VERSION ""

NS_ :

BS_:

BU_: SMART_CORE
VAL_TABLE_ FIRST_TOUCH_COORDINATE_Y_IS 0 "Default Value" ;
VAL_TABLE_ FIRST_TOUCH_COORDINATE_X_IS 0 "Default Value" ;

BO_ 3221225472 VECTOR__INDEPENDENT_SIG_MSG: 0 Vector__XXX
 SG_ VCU_DRIVE_MODE : 0|3@1+ (1,0) [0|7] "" Vector__XXX
 SG_ VCU36_MSG_CNT : 0|4@1+ (1,0) [0|15] "" Vector__XXX
 SG_ REMAINING_OIL_LIFE_PERCENT : 0|7@1+ (1,0) [0|100] "%" Vector__XXX
 SG_ BATT_OCV : 0|9@1+ (20,6000) [6000|16000] "mV" Vector__XXX

BO_ 1506 EMS49_500: 8 Vector__XXX
 SG_ IBS_Q_DISCHARGE : 32|16@1+ (0.125,0) [0|8191.75] "Ah"  SMART_CORE
 SG_ IBS_Q_CHARGE : 16|16@1+ (0.125,0) [0|8191.75] "Ah"  SMART_CORE
 SG_ IBS_INT_RESISTANCE_ERR : 12|4@1+ (1,2) [0|15] "%"  SMART_CORE
 SG_ IBS_INT_RESISTANCE : 0|12@1+ (0.0625,0) [0|255.875] "mOhm"  SMART_CORE

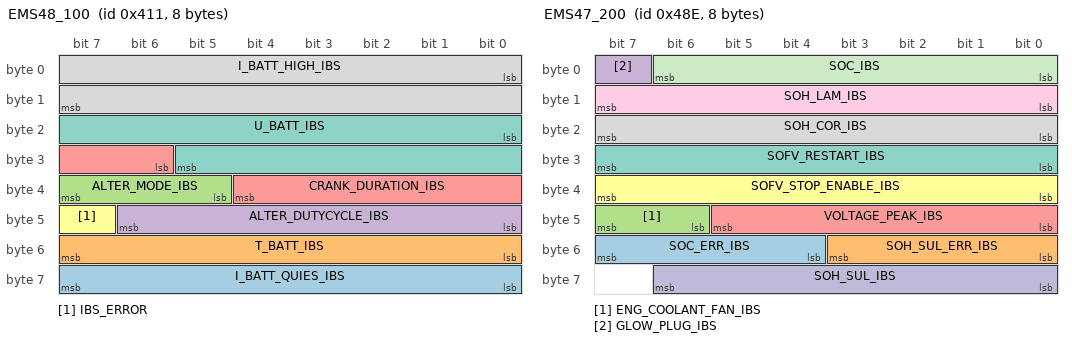
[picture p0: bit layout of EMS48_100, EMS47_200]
BO_ 1041 EMS48_100: 8 Vector__XXX
 SG_ I_BATT_QUIES_IBS : 56|8@1+ (0.00390625,0) [0|0.984375] "A"  SMART_CORE
 SG_ T_BATT_IBS : 48|8@1+ (1,-40) [-40|214] "degC"  SMART_CORE
 SG_ ALTER_MODE_IBS : 37|3@1+ (1,0) [0|7] ""  SMART_CORE
 SG_ ALTER_DUTYCYCLE_IBS : 40|7@1+ (1,0) [0|100] "%"  SMART_CORE
 SG_ CRANK_DURATION_IBS : 30|7@1+ (0.1,0) [0|9] "sec"  SMART_CORE
 SG_ IBS_ERROR : 47|1@1+ (1,0) [0|1] ""  SMART_CORE
 SG_ U_BATT_IBS : 16|14@1+ (0.001,3) [3|19.382] "V"  SMART_CORE
 SG_ I_BATT_HIGH_IBS : 0|16@1+ (0.03125,-1536) [-1536|511.90625] "A"  SMART_CORE

BO_ 1166 EMS47_200: 8 Vector__XXX
 SG_ SOC_ERR_IBS : 52|4@1+ (1,2) [0|15] "%"  SMART_CORE
 SG_ SOH_SUL_ERR_IBS : 48|4@1+ (1,2) [0|15] "%"  SMART_CORE
 SG_ ENG_COOLANT_FAN_IBS : 46|2@1+ (1,0) [0|3] ""  SMART_CORE
 SG_ GLOW_PLUG_IBS : 7|1@1+ (1,0) [0|1] ""  SMART_CORE
 SG_ VOLTAGE_PEAK_IBS : 40|6@1+ (0.125,5) [5|12.75] "V"  SMART_CORE
 SG_ SOFV_STOP_ENABLE_IBS : 32|8@1+ (0.0625,0) [0|15.875] "V"  SMART_CORE
 SG_ SOFV_RESTART_IBS : 24|8@1+ (0.0625,0) [0|15.875] "V"  SMART_CORE
 SG_ SOH_COR_IBS : 16|8@1+ (1,0) [0|100] "%"  SMART_CORE
 SG_ SOH_LAM_IBS : 8|8@1+ (1,0) [0|100] "%"  SMART_CORE
 SG_ SOH_SUL_IBS : 56|7@1+ (1,0) [0|100] "%"  SMART_CORE
 SG_ SOC_IBS : 0|7@1+ (1,0) [0|100] "%"  SMART_CORE

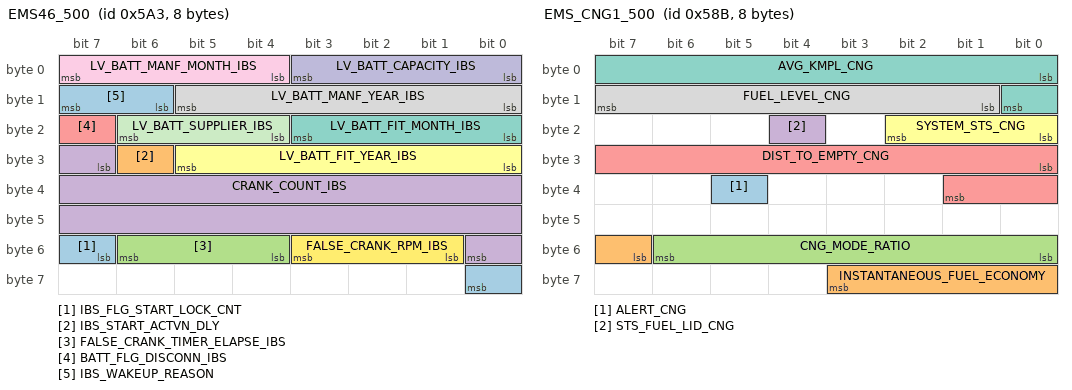
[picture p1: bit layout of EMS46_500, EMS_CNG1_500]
BO_ 1443 EMS46_500: 8 Vector__XXX
 SG_ IBS_FLG_START_LOCK_CNT : 55|2@1+ (1,0) [0|3] ""  SMART_CORE
 SG_ IBS_START_ACTVN_DLY : 30|1@1+ (1,0) [0|1] ""  SMART_CORE
 SG_ FALSE_CRANK_TIMER_ELAPSE_IBS : 52|3@1+ (1,0) [0|7] ""  SMART_CORE
 SG_ CRANK_COUNT_IBS : 31|18@1+ (1,0) [0|262143] ""  SMART_CORE
 SG_ BATT_FLG_DISCONN_IBS : 23|1@1+ (1,0) [0|1] ""  SMART_CORE
 SG_ LV_BATT_FIT_YEAR_IBS : 24|6@1+ (1,2026) [2026|2089] ""  SMART_CORE
 SG_ LV_BATT_FIT_MONTH_IBS : 16|4@1+ (1,0) [0|12] ""  SMART_CORE
 SG_ LV_BATT_MANF_YEAR_IBS : 8|6@1+ (1,2026) [2026|2089] ""  SMART_CORE
 SG_ LV_BATT_MANF_MONTH_IBS : 4|4@1+ (1,0) [0|12] ""  SMART_CORE
 SG_ LV_BATT_CAPACITY_IBS : 0|4@1+ (1,0) [0|15] "Ah"  SMART_CORE
 SG_ LV_BATT_SUPPLIER_IBS : 20|3@1+ (1,0) [0|7] ""  SMART_CORE
 SG_ FALSE_CRANK_RPM_IBS : 49|3@1+ (1,0) [0|7] ""  SMART_CORE
 SG_ IBS_WAKEUP_REASON : 14|2@1+ (1,0) [0|3] ""  SMART_CORE

BO_ 1419 EMS_CNG1_500: 8 Vector__XXX
 SG_ ALERT_CNG : 37|1@1+ (1,0) [0|1] ""  SMART_CORE
 SG_ INSTANTANEOUS_FUEL_ECONOMY : 55|5@1+ (1,0) [0|30] "km/kg"  SMART_CORE
 SG_ CNG_MODE_RATIO : 48|7@1+ (1,0) [0|100] "%"  SMART_CORE
 SG_ STS_FUEL_LID_CNG : 20|1@1+ (1,0) [0|1] ""  SMART_CORE
 SG_ DIST_TO_EMPTY_CNG : 24|10@1+ (1,0) [0|1000] "Km"  SMART_CORE
 SG_ SYSTEM_STS_CNG : 16|3@1+ (1,0) [0|7] ""  SMART_CORE
 SG_ AVG_KMPL_CNG : 0|9@1+ (0.1,0) [0|51] "km/kg"  SMART_CORE
 SG_ FUEL_LEVEL_CNG : 9|7@1+ (1,0) [0|100] "%"  SMART_CORE

BO_ 535 RVC1_100: 8 Vector__XXX
 SG_ RVC_GUIDED_VOICE_REQ : 8|4@1+ (1,0) [0|15] ""  SMART_CORE
 SG_ RVC_OPERATION_STATE : 4|3@1+ (1,0) [0|5] ""  SMART_CORE
 SG_ RVC_BUTTON_GROUP : 0|4@1+ (1,0) [0|9] ""  SMART_CORE

BO_ 833 MCM3_100: 8 SMART_CORE
 SG_ F_TRIG_F_STATE : 2|2@1+ (1,0) [0|3] "" Vector__XXX

BO_ 257 MCM_SP: 8 SMART_CORE
 SG_ IMMOVAL4 : 0|64@1+ (1,0) [0|1.8446744074] "" Vector__XXX

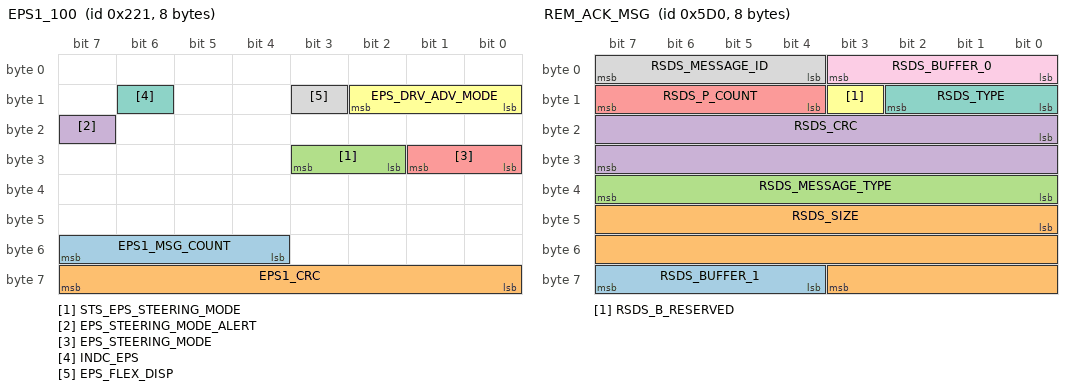
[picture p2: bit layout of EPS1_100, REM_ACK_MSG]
BO_ 545 EPS1_100: 8 Vector__XXX
 SG_ EPS1_MSG_COUNT : 52|4@1+ (1,0) [0|15] ""  SMART_CORE
 SG_ EPS1_CRC : 56|8@1+ (1,0) [0|255] ""  SMART_CORE
 SG_ STS_EPS_STEERING_MODE : 26|2@1+ (1,0) [0|3] ""  SMART_CORE
 SG_ EPS_STEERING_MODE_ALERT : 23|1@1+ (1,0) [0|1] ""  SMART_CORE
 SG_ EPS_STEERING_MODE : 24|2@1+ (1,0) [0|3] ""  SMART_CORE
 SG_ EPS_DRV_ADV_MODE : 8|3@1+ (1,0) [0|7] ""  SMART_CORE
 SG_ INDC_EPS : 14|1@1+ (1,0) [0|1] ""  SMART_CORE
 SG_ EPS_FLEX_DISP : 11|1@1+ (1,0) [0|1] ""  SMART_CORE

BO_ 987 OBC5_100: 8 Vector__XXX
 SG_ OBC_EVWARNING_TT : 4|2@1+ (1,0) [0|3] ""  SMART_CORE
 SG_ OBC_ALERT_MESGS : 8|6@1+ (1,0) [0|63] ""  SMART_CORE

BO_ 818 MCU6_100: 8 Vector__XXX
 SG_ MCU_EVWARNING_TT : 6|2@1+ (1,0) [0|3] ""  SMART_CORE
 SG_ MCU_ALERT_MSGS : 0|6@1+ (1,0) [0|63] ""  SMART_CORE

BO_ 992 LDC5_100: 8 Vector__XXX
 SG_ LDC_EVWARNING_TT : 6|2@1+ (1,0) [0|3] ""  SMART_CORE
 SG_ LDC_ALERT_MSGS : 0|6@1+ (1,0) [0|63] ""  SMART_CORE

BO_ 298 BMS21_100: 8 Vector__XXX
 SG_ BMS_BattEnergyDisAcc_Drv : 48|16@1+ (0.01,0) [0|50] "KWH"  SMART_CORE
 SG_ BMS_BattEnergyAcc_Regen : 32|16@1+ (0.01,0) [0|50] "KWH"  SMART_CORE
 SG_ BMS_BattEnergyAcc_NC : 16|16@1+ (0.01,0) [0|50] "KWH"  SMART_CORE
 SG_ BMS_BattEnergyAcc_FC : 0|16@1+ (0.01,0) [0|50] "KWH"  SMART_CORE

BO_ 1019 BMS15_200: 8 Vector__XXX
 SG_ BMS_ServiceDueDetection : 26|2@1+ (1,0) [0|3] ""  SMART_CORE
 SG_ BMS_BatteryContactorLife : 0|11@1+ (1,0) [0|2000] "kcycle"  SMART_CORE

BO_ 445 ESC16_10: 8 Vector__XXX
 SG_ STS_ITA : 0|2@1+ (1,0) [0|3] ""  SMART_CORE
 SG_ ITA_ACTIVE : 2|1@1+ (1,0) [0|1] ""  SMART_CORE
 SG_ CCO_WARNING : 11|3@1+ (1,0) [0|7] ""  SMART_CORE
 SG_ CCO_SET_SPD : 8|3@1+ (1,0) [0|7] ""  SMART_CORE
 SG_ CCO_ACTIVE : 5|2@1+ (1,0) [0|3] ""  SMART_CORE

BO_ 1488 REM_ACK_MSG: 8 SMART_CORE
 SG_ RSDS_BUFFER_1 : 60|4@1+ (1,0) [0|15] "" Vector__XXX
 SG_ RSDS_SIZE : 40|20@1+ (1,0) [0|1048575] "Byte" Vector__XXX
 SG_ RSDS_MESSAGE_TYPE : 32|8@1+ (1,0) [0|255] "NA" Vector__XXX
 SG_ RSDS_CRC : 16|16@1+ (1,0) [0|65535] "NA" Vector__XXX
 SG_ RSDS_P_COUNT : 12|4@1+ (1,0) [0|15] "counter" Vector__XXX
 SG_ RSDS_B_RESERVED : 11|1@1+ (1,0) [0|1] "NA" Vector__XXX
 SG_ RSDS_TYPE : 8|3@1+ (1,0) [0|7] "ENUM" Vector__XXX
 SG_ RSDS_MESSAGE_ID : 4|4@1+ (1,0) [0|15] "" Vector__XXX
 SG_ RSDS_BUFFER_0 : 0|4@1+ (1,0) [0|15] "" Vector__XXX

BO_ 1486 IS_REM_05: 8 SMART_CORE
 SG_ GPS_LONGITUDE : 32|31@1+ (1E-007,0) [0|180] "deg" Vector__XXX
 SG_ GPS_LATITUDE : 0|31@1+ (1E-007,0) [0|90] "deg" Vector__XXX
 SG_ GPS_HDOP_V : 31|1@1+ (1,0) [0|1] "bool" Vector__XXX

BO_ 1485 IS_REM_04: 8 SMART_CORE
 SG_ GPS_MCU_TIMESTAMP : 0|64@1+ (1,0) [0|1.84467440737096E+019] "us" Vector__XXX

BO_ 1484 IS_REM_03: 8 SMART_CORE
 SG_ GPS_EPOCH_TIMESTAMP : 0|64@1+ (1,0) [0|1.84467440737096E+019] "ms" Vector__XXX

BO_ 1827 EX_SUMMARY_RESPONSE_0: 8 SMART_CORE
 SG_ SUMMARY_DATA_0_MSG_CNT : 56|8@1+ (1,0) [0|255] "" Vector__XXX
 SG_ SUMMARY_DATA_0 : 0|56@1+ (1,0) [0|7.20575940379279E+016] "" Vector__XXX

BO_ 1828 EX_SUMMARY_RESPONSE_1: 8 SMART_CORE
 SG_ SUMMARY_DATA_1_MSG_CNT : 56|8@1+ (1,0) [0|255] "" Vector__XXX
 SG_ SUMMARY_DATA_1 : 0|56@1+ (1,0) [0|7.20575940379279E+016] "" Vector__XXX

BO_ 1830 EX_SUMMARY_RESPONSE_2: 8 SMART_CORE
 SG_ SUMMARY_DATA_2_MSG_CNT : 56|8@1+ (1,0) [0|255] "" Vector__XXX
 SG_ SUMMARY_DATA_2 : 0|56@1+ (1,0) [0|7.20575940379279E+016] "" Vector__XXX

BO_ 1831 EX_SUMMARY_RESPONSE_3: 8 SMART_CORE
 SG_ SUMMARY_DATA_3_MSG_CNT : 56|8@1+ (1,0) [0|255] "" Vector__XXX
 SG_ SUMMARY_DATA_3 : 0|56@1+ (1,0) [0|7.20575940379279E+016] "" Vector__XXX

BO_ 1487 IS_REM_06: 8 SMART_CORE
 SG_ GPS_HDOP : 0|10@1+ (0.1,0) [0|100] "NA" Vector__XXX
 SG_ GPS_ALTITUDE : 10|20@1+ (0.01,-500) [-500|6000] "m" Vector__XXX
 SG_ GPS_ALT_POSITION_STD : 30|14@1+ (0.01,0) [0|100] "m" Vector__XXX

BO_ 1483 IS_REM_02: 8 SMART_CORE
 SG_ GPS_ALT_POSITION_STD_V : 0|1@1+ (1,0) [0|1] "bool" Vector__XXX
 SG_ GPS_NUM_SATELLITES_V : 22|1@1+ (1,0) [0|1] "BOOL" Vector__XXX
 SG_ GPS_NUM_SATELLITES : 24|5@1+ (1,0) [0|31] "COUNTER" Vector__XXX
 SG_ GPS_MCU_TIMESTAMP_V : 21|1@1+ (1,0) [0|1] "bool" Vector__XXX
 SG_ GPS_LONGITUDE_V : 20|1@1+ (1,0) [0|1] "bool" Vector__XXX
 SG_ GPS_LONG_POSITION_STD_V : 18|1@1+ (1,0) [0|1] "bool" Vector__XXX
 SG_ GPS_LONG_POSITION_STD : 46|14@1+ (0.01,0) [0|100] "m" Vector__XXX
 SG_ GPS_LONG_DIRECTION_V : 19|1@1+ (1,0) [0|1] "bool" Vector__XXX
 SG_ GPS_LONG_DIRECTION : 23|1@1+ (1,0) [0|1] "bool" Vector__XXX
 SG_ GPS_LATITUDE_V : 17|1@1+ (1,0) [0|1] "bool" Vector__XXX
 SG_ GPS_LAT_POSITION_STD_V : 29|1@1+ (1,0) [0|1] "bool" Vector__XXX
 SG_ GPS_LAT_POSITION_STD : 32|14@1+ (0.01,0) [0|100] "m" Vector__XXX
 SG_ GPS_LAT_DIRECTION_V : 30|1@1+ (1,0) [0|1] "bool" Vector__XXX
 SG_ GPS_LAT_DIRECTION : 31|1@1+ (1,0) [0|1] "bool" Vector__XXX
 SG_ GPS_EPOCH_TIMESTAMP_V : 4|1@1+ (1,0) [0|1] "bool" Vector__XXX
 SG_ GPS_COURSE_V : 2|1@1+ (1,0) [0|1] "bool" Vector__XXX
 SG_ GPS_COURSE : 5|12@1+ (0.1,0) [0|360] "deg" Vector__XXX
 SG_ GPS_ALTITUDE_V : 1|1@1+ (1,0) [0|1] "bool" Vector__XXX

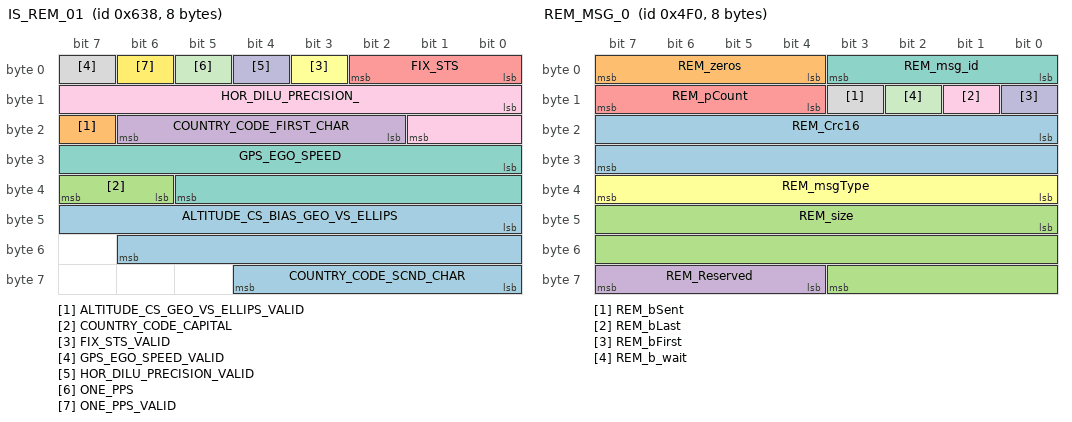
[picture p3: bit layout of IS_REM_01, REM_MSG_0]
BO_ 1592 IS_REM_01: 8 SMART_CORE
 SG_ ALTITUDE_CS_BIAS_GEO_VS_ELLIPS : 40|15@1+ (0.01,-150) [-150|150] "m" Vector__XXX
 SG_ ALTITUDE_CS_GEO_VS_ELLIPS_VALID : 23|1@1+ (1,0) [0|1] "bool" Vector__XXX
 SG_ COUNTRY_CODE_CAPITAL : 38|2@1+ (1,0) [0|2] "ENUM" Vector__XXX
 SG_ COUNTRY_CODE_FIRST_CHAR : 18|5@1+ (1,0) [0|26] "" Vector__XXX
 SG_ FIX_STS : 0|3@1+ (1,0) [0|6] "ENUM" Vector__XXX
 SG_ FIX_STS_VALID : 3|1@1+ (1,0) [0|1] "bool" Vector__XXX
 SG_ GPS_EGO_SPEED : 24|14@1+ (0.01,0) [0|100] "m_per_s" Vector__XXX
 SG_ GPS_EGO_SPEED_VALID : 7|1@1+ (1,0) [0|1] "bool" Vector__XXX
 SG_ HOR_DILU_PRECISION_ : 8|10@1+ (0.1,0) [0|100] "NA" Vector__XXX
 SG_ HOR_DILU_PRECISION_VALID : 4|1@1+ (1,0) [0|1] "bool" Vector__XXX
 SG_ ONE_PPS : 5|1@1+ (1,0) [0|1] "bool" Vector__XXX
 SG_ ONE_PPS_VALID : 6|1@1+ (1,0) [0|1] "bool" Vector__XXX
 SG_ COUNTRY_CODE_SCND_CHAR : 56|5@1+ (1,0) [0|26] "" Vector__XXX

BO_ 1279 REM_MSG_15: 8 Vector__XXX
 SG_ REM_DATA_15_MSG_CNT : 56|8@1+ (1,0) [0|255] ""  SMART_CORE
 SG_ REM_DATA_15 : 0|56@1+ (1,0) [0|7.20575940379279E+016] ""  SMART_CORE

BO_ 1278 REM_MSG_14: 8 Vector__XXX
 SG_ REM_DATA_14_MSG_CNT : 56|8@1+ (1,0) [0|255] ""  SMART_CORE
 SG_ REM_DATA_14 : 0|56@1+ (1,0) [0|7.20575940379279E+016] ""  SMART_CORE

BO_ 1277 REM_MSG_13: 8 Vector__XXX
 SG_ REM_DATA_13_MSG_CNT : 56|8@1+ (1,0) [0|255] ""  SMART_CORE
 SG_ REM_DATA_13 : 0|56@1+ (1,0) [0|7.20575940379279E+016] ""  SMART_CORE

BO_ 1276 REM_MSG_12: 8 Vector__XXX
 SG_ REM_DATA_12_MSG_CNT : 56|8@1+ (1,0) [0|255] ""  SMART_CORE
 SG_ REM_DATA_12 : 0|56@1+ (1,0) [0|7.20575940379279E+016] ""  SMART_CORE

BO_ 1275 REM_MSG_11: 8 Vector__XXX
 SG_ REM_DATA_11_MSG_CNT : 56|8@1+ (1,0) [0|255] ""  SMART_CORE
 SG_ REM_DATA_11 : 0|56@1+ (1,0) [0|7.20575940379279E+016] ""  SMART_CORE

BO_ 1274 REM_MSG_10: 8 Vector__XXX
 SG_ REM_DATA_10_MSG_CNT : 56|8@1+ (1,0) [0|255] ""  SMART_CORE
 SG_ REM_DATA_10 : 0|56@1+ (1,0) [0|7.20575940379279E+016] ""  SMART_CORE

BO_ 1273 REM_MSG_9: 8 Vector__XXX
 SG_ REM_DATA_9_MSG_CNT : 56|8@1+ (1,0) [0|255] ""  SMART_CORE
 SG_ REM_DATA_9 : 0|56@1+ (1,0) [0|7.20575940379279E+016] ""  SMART_CORE

BO_ 1272 REM_MSG_8: 8 Vector__XXX
 SG_ REM_DATA_8_MSG_CNT : 56|8@1+ (1,0) [0|255] ""  SMART_CORE
 SG_ REM_DATA_8 : 0|56@1+ (1,0) [0|7.20575940379279E+016] ""  SMART_CORE

BO_ 1271 REM_MSG_7: 8 Vector__XXX
 SG_ REM_DATA_7_MSG_CNT : 56|8@1+ (1,0) [0|255] ""  SMART_CORE
 SG_ REM_DATA_7 : 0|56@1+ (1,0) [0|7.20575940379279E+016] ""  SMART_CORE

BO_ 1270 REM_MSG_6: 8 Vector__XXX
 SG_ REM_DATA_6_MSG_CNT : 56|8@1+ (1,0) [0|255] ""  SMART_CORE
 SG_ REM_DATA_6 : 0|56@1+ (1,0) [0|7.20575940379279E+016] ""  SMART_CORE

BO_ 1269 REM_MSG_5: 8 Vector__XXX
 SG_ REM_DATA_5_MSG_CNT : 56|8@1+ (1,0) [0|255] ""  SMART_CORE
 SG_ REM_DATA_5 : 0|56@1+ (1,0) [0|7.20575940379279E+016] ""  SMART_CORE

BO_ 1268 REM_MSG_4: 8 Vector__XXX
 SG_ REM_DATA_4_MSG_CNT : 56|8@1+ (1,0) [0|255] ""  SMART_CORE
 SG_ REM_DATA_4 : 0|56@1+ (1,0) [0|7.20575940379279E+016] ""  SMART_CORE

BO_ 1267 REM_MSG_3: 8 Vector__XXX
 SG_ REM_DATA_3_MSG_CNT : 56|8@1+ (1,0) [0|255] ""  SMART_CORE
 SG_ REM_DATA_3 : 0|56@1+ (1,0) [0|7.20575940379279E+016] ""  SMART_CORE

BO_ 1266 REM_MSG_2: 8 Vector__XXX
 SG_ REM_DATA_2_MSG_CNT : 56|8@1+ (1,0) [0|255] ""  SMART_CORE
 SG_ REM_DATA_2 : 0|56@1+ (1,0) [0|7.20575940379279E+016] ""  SMART_CORE

BO_ 1265 REM_MSG_1: 8 Vector__XXX
 SG_ REM_DATA_1_MSG_CNT : 56|8@1+ (1,0) [0|255] ""  SMART_CORE
 SG_ REM_DATA_1 : 0|56@1+ (1,0) [0|7.20575940379279E+016] ""  SMART_CORE

BO_ 1264 REM_MSG_0: 8 Vector__XXX
 SG_ REM_Crc16 : 16|16@1+ (1,0) [0|65535] ""  SMART_CORE
 SG_ REM_zeros : 4|4@1+ (1,0) [0|15] ""  SMART_CORE
 SG_ REM_size : 40|20@1+ (1,0) [0|1048575] ""  SMART_CORE
 SG_ REM_Reserved : 60|4@1+ (1,0) [0|15] ""  SMART_CORE
 SG_ REM_pCount : 12|4@1+ (1,0) [0|15] ""  SMART_CORE
 SG_ REM_msgType : 32|8@1+ (1,0) [0|255] ""  SMART_CORE
 SG_ REM_msg_id : 0|4@1+ (1,0) [0|15] ""  SMART_CORE
 SG_ REM_bSent : 11|1@1+ (1,0) [0|1] ""  SMART_CORE
 SG_ REM_bLast : 9|1@1+ (1,0) [0|1] ""  SMART_CORE
 SG_ REM_bFirst : 8|1@1+ (1,0) [0|1] ""  SMART_CORE
 SG_ REM_b_wait : 10|1@1+ (1,0) [0|1] ""  SMART_CORE

BO_ 1007 VCU15_100: 8 Vector__XXX
 SG_ VCU_TorqueCoasting : 32|16@1+ (0.0625,-2048) [-2045|2045] "Nm"  SMART_CORE
 SG_ VCU_SwitchS2 : 50|1@1+ (1,0) [0|1] ""  SMART_CORE
 SG_ VCU_StCreep : 49|1@1+ (1,0) [0|1] ""  SMART_CORE
 SG_ VCU_StCoasting : 48|1@1+ (1,0) [0|1] ""  SMART_CORE
 SG_ VCU_HVAccPowerConsumption : 16|16@1+ (0.001,0) [0|65] "Kw"  SMART_CORE
 SG_ VCU_EConsPerKm : 0|16@1+ (0.001,0) [0|65.535] "Kwh/km"  SMART_CORE

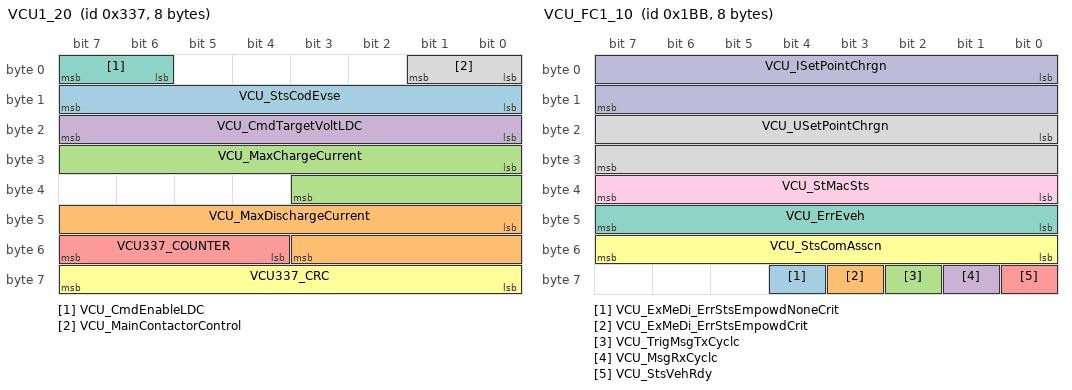
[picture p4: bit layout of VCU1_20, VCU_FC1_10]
BO_ 823 VCU1_20: 8 Vector__XXX
 SG_ VCU_StsCodEvse : 8|8@1+ (1,0) [0|255] ""  SMART_CORE
 SG_ VCU_MaxDischargeCurrent : 40|12@1+ (1,0) [0|4094] "A"  SMART_CORE
 SG_ VCU_MaxChargeCurrent : 24|12@1+ (1,0) [0|4094] "A"  SMART_CORE
 SG_ VCU_CmdTargetVoltLDC : 16|8@1+ (0.1,0) [0|25.5] "V"  SMART_CORE
 SG_ VCU337_COUNTER : 52|4@1+ (1,0) [0|15] "NA"  SMART_CORE
 SG_ VCU337_CRC : 56|8@1+ (1,0) [0|255] "NA"  SMART_CORE
 SG_ VCU_CmdEnableLDC : 6|2@1+ (1,0) [0|3] "NA"  SMART_CORE
 SG_ VCU_MainContactorControl : 0|2@1+ (1,0) [0|3] ""  SMART_CORE

BO_ 443 VCU_FC1_10: 8 Vector__XXX
 SG_ VCU_ExMeDi_ErrStsEmpowdNoneCrit : 60|1@1+ (1,0) [0|1] ""  SMART_CORE
 SG_ VCU_ExMeDi_ErrStsEmpowdCrit : 59|1@1+ (1,0) [0|1] ""  SMART_CORE
 SG_ VCU_TrigMsgTxCyclc : 58|1@1+ (1,0) [0|1] ""  SMART_CORE
 SG_ VCU_MsgRxCyclc : 57|1@1+ (1,0) [0|1] ""  SMART_CORE
 SG_ VCU_StsVehRdy : 56|1@1+ (1,0) [0|1] ""  SMART_CORE
 SG_ VCU_StsComAsscn : 48|8@1+ (1,0) [0|255] ""  SMART_CORE
 SG_ VCU_ErrEveh : 40|8@1+ (1,0) [0|255] ""  SMART_CORE
 SG_ VCU_USetPointChrgn : 16|16@1+ (0.1,0) [0|1500] "V"  SMART_CORE
 SG_ VCU_StMacSts : 32|8@1+ (1,0) [0|255] ""  SMART_CORE
 SG_ VCU_ISetPointChrgn : 0|16@1+ (0.1,0) [0|1000] "A"  SMART_CORE

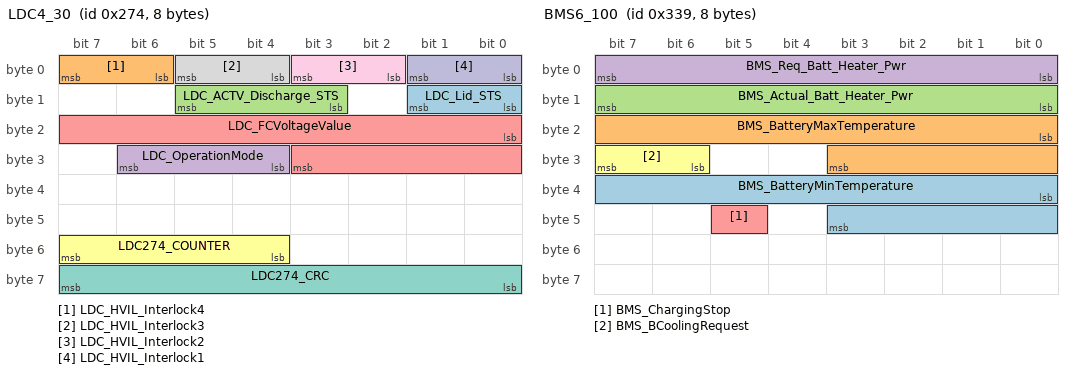
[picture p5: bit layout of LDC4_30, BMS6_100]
BO_ 628 LDC4_30: 8 Vector__XXX
 SG_ LDC_Lid_STS : 8|2@1+ (1,0) [0|3] ""  SMART_CORE
 SG_ LDC_HVIL_Interlock4 : 6|2@1+ (1,0) [0|3] "NA"  SMART_CORE
 SG_ LDC_ACTV_Discharge_STS : 11|3@1+ (1,0) [0|3] ""  SMART_CORE
 SG_ LDC_OperationMode : 28|3@1+ (1,0) [0|7] "NA"  SMART_CORE
 SG_ LDC_FCVoltageValue : 16|12@1+ (0.1,0) [0|500] "V"  SMART_CORE
 SG_ LDC274_COUNTER : 52|4@1+ (1,0) [0|14] "NA"  SMART_CORE
 SG_ LDC274_CRC : 56|8@1+ (1,0) [0|0] "NA"  SMART_CORE
 SG_ LDC_HVIL_Interlock3 : 4|2@1+ (1,0) [0|3] "NA"  SMART_CORE
 SG_ LDC_HVIL_Interlock2 : 2|2@1+ (1,0) [0|3] "NA"  SMART_CORE
 SG_ LDC_HVIL_Interlock1 : 0|2@1+ (1,0) [0|3] "NA"  SMART_CORE

BO_ 991 LDC3_100: 8 Vector__XXX
 SG_ LDC_OPV_Circuit_Error : 22|1@1+ (1,0) [0|1] ""  SMART_CORE
 SG_ LDC_Low_Temp_Shutdown : 23|1@1+ (1,0) [0|1] ""  SMART_CORE
 SG_ LDC_IPV_Circuit_Error : 21|1@1+ (1,0) [0|1] ""  SMART_CORE
 SG_ LDC_INTERNAL_FAIL : 20|1@1+ (1,0) [0|1] ""  SMART_CORE
 SG_ LDC_Input_Over_Current : 19|1@1+ (1,0) [0|1] ""  SMART_CORE
 SG_ LDC_Heat_Sink_Over_Temp_Shutdown : 2|1@1+ (1,0) [0|1] ""  SMART_CORE
 SG_ LDC_HVDC_Side_Relay_Sts : 52|1@1+ (1,0) [0|1] ""  SMART_CORE
 SG_ LDC_CC_CV_STS : 51|1@1+ (1,0) [0|1] ""  SMART_CORE
 SG_ LDC_Burst_Mode_Sts : 50|1@1+ (1,0) [0|1] ""  SMART_CORE
 SG_ LDC_HW_Enable : 49|1@1+ (1,0) [0|1] ""  SMART_CORE
 SG_ LDC_Stage : 46|3@1+ (1,0) [0|7] ""  SMART_CORE
 SG_ LDC_Debounce_Count : 41|3@1+ (1,0) [0|7] ""  SMART_CORE
 SG_ LDC_Vprog_Out_of_Range : 40|1@1+ (1,0) [0|1] ""  SMART_CORE
 SG_ LDC_Watchdog_Failure : 18|1@1+ (1,0) [0|1] ""  SMART_CORE
 SG_ LDC_VCU_Node_Absent : 17|1@1+ (1,0) [0|1] ""  SMART_CORE
 SG_ LDC_Temp_Sensing_Failure : 16|1@1+ (1,0) [0|1] ""  SMART_CORE
 SG_ LDC_IPC_COMM_ERR_OBC : 15|1@1+ (1,0) [0|1] ""  SMART_CORE
 SG_ LDC_EEPROM_Failure : 14|1@1+ (1,0) [0|1] ""  SMART_CORE
 SG_ LDC_Short_Circuit : 13|1@1+ (1,0) [0|1] ""  SMART_CORE
 SG_ LDC_Output_Under_Voltage : 12|1@1+ (1,0) [0|1] ""  SMART_CORE
 SG_ LDC_Output_Over_Voltage : 11|1@1+ (1,0) [0|1] ""  SMART_CORE
 SG_ LDC_Output_Over_Current : 10|1@1+ (1,0) [0|1] ""  SMART_CORE
 SG_ LDC_LPS_Under_Voltage : 9|1@1+ (1,0) [0|1] ""  SMART_CORE
 SG_ LDC_LPS_Over_Voltage : 8|1@1+ (1,0) [0|1] ""  SMART_CORE
 SG_ LDC_Input_Under_Voltage : 7|1@1+ (1,0) [0|1] ""  SMART_CORE
 SG_ LDC_Input_Over_Voltage : 6|1@1+ (1,0) [0|1] ""  SMART_CORE
 SG_ LDC_Heat_Sink_Over_Temp_Wng_2 : 5|1@1+ (1,0) [0|1] ""  SMART_CORE
 SG_ LDC_Heat_Sink_Over_Temp_Wng_1 : 4|1@1+ (1,0) [0|1] ""  SMART_CORE
 SG_ LDC_Heat_Sink_Over_Temp_Wng_0 : 3|1@1+ (1,0) [0|1] ""  SMART_CORE
 SG_ LDC_Amb_Over_Temp_Wng : 1|1@1+ (1,0) [0|1] ""  SMART_CORE
 SG_ LDC_Amb_Over_Temp_Shutdown : 0|1@1+ (1,0) [0|1] ""  SMART_CORE

BO_ 580 LDC2_30: 8 Vector__XXX
 SG_ LDC_OutputVoltageValue : 40|12@1+ (0.01,0) [0|25] "V"  SMART_CORE
 SG_ LDC_OutputCurrent : 16|14@1+ (0.1,0) [0|1000] "A"  SMART_CORE
 SG_ LDC_InputVoltageValue : 0|14@1+ (0.1,0) [0|1000] "V"  SMART_CORE
 SG_ LDC_InputCurrentValue : 32|8@1+ (0.1,0) [0|25] "A"  SMART_CORE

BO_ 989 LDC1_100: 8 Vector__XXX
 SG_ LDC_Primary_Temperature : 32|12@1+ (0.1,-55) [-55|150] "deg C"  SMART_CORE
 SG_ LDC_CoolingRequest : 0|8@1+ (0.5,0) [0|100] "%"  SMART_CORE
 SG_ LDC_MOSFET_Temperature : 48|12@1+ (0.1,-55) [-55|150] "deg C"  SMART_CORE
 SG_ LDC_Secondary_Temperature : 8|12@1+ (0.1,-55) [-55|150] "deg C"  SMART_CORE
 SG_ LDC_ProtectionMode : 28|3@1+ (1,0) [0|7] "NA"  SMART_CORE

BO_ 825 BMS6_100: 8 Vector__XXX
 SG_ BMS_BatteryMinTemperature : 32|12@1+ (0.1,-40) [-40|125] "deg C"  SMART_CORE
 SG_ BMS_BatteryMaxTemperature : 16|12@1+ (0.1,-40) [-40|125] "deg C"  SMART_CORE
 SG_ BMS_Actual_Batt_Heater_Pwr : 8|8@1+ (50,0) [0|8000] "Watts"  SMART_CORE
 SG_ BMS_Req_Batt_Heater_Pwr : 0|8@1+ (50,0) [0|8000] "watts"  SMART_CORE
 SG_ BMS_ChargingStop : 45|1@1+ (1,0) [0|1] ""  SMART_CORE
 SG_ BMS_BCoolingRequest : 30|2@1+ (1,0) [0|3] ""  SMART_CORE

BO_ 352 BMS_IVT_MSG_RESULT_U3: 6 Vector__XXX
 SG_ BMS_IVT_Result_U3 : 0|32@1+ (1,0) [0|45000] "mV"  SMART_CORE

BO_ 345 BMS_IVT_MSG_RESULT_U2: 6 Vector__XXX
 SG_ BMS_IVT_Result_U2 : 0|32@1+ (1,0) [0|45000] "mV"  SMART_CORE

BO_ 344 BMS_IVT_MSG_RESULT_U1: 6 Vector__XXX
 SG_ BMS_IVT_Result_U1 : 0|32@1+ (1,0) [0|45000] "mV"  SMART_CORE

BO_ 979 BMS9_10: 8 Vector__XXX
 SG_ BMS_Discharge_Cycle : 48|16@1+ (1,0) [0|65534] ""  SMART_CORE
 SG_ BMS_Charge_Cycle : 32|16@1+ (1,0) [0|65534] ""  SMART_CORE
 SG_ BMS_ChargePowerAvailable_2 : 16|16@1+ (0.01,0) [0|200] "Kw"  SMART_CORE
 SG_ BMS_ChargePowerAvailable_10 : 0|16@1+ (0.01,0) [0|200] "Kw"  SMART_CORE

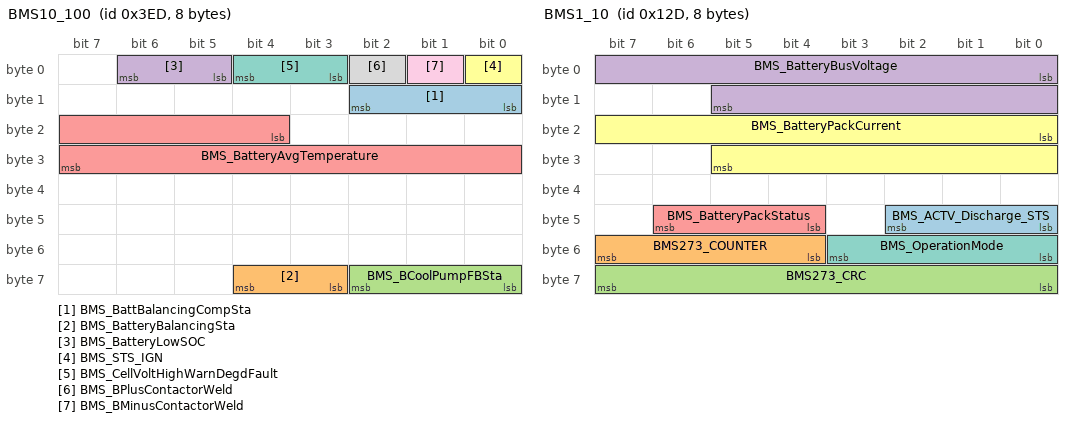
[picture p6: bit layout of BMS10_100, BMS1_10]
BO_ 1005 BMS10_100: 8 Vector__XXX
 SG_ BMS_BattBalancingCompSta : 8|3@1+ (1,0) [0|4] ""  SMART_CORE
 SG_ BMS_BatteryBalancingSta : 59|2@1+ (1,0) [0|1] ""  SMART_CORE
 SG_ BMS_BCoolPumpFBSta : 56|3@1+ (1,0) [0|7] ""  SMART_CORE
 SG_ BMS_BatteryLowSOC : 5|2@1+ (1,0) [0|3] ""  SMART_CORE
 SG_ BMS_BatteryAvgTemperature : 20|12@1+ (0.1,-40) [-40|125] "deg C"  SMART_CORE
 SG_ BMS_STS_IGN : 0|1@1+ (1,0) [0|1] ""  SMART_CORE
 SG_ BMS_CellVoltHighWarnDegdFault : 3|2@1+ (1,0) [0|3] ""  SMART_CORE
 SG_ BMS_BPlusContactorWeld : 2|1@1+ (1,0) [0|1] ""  SMART_CORE
 SG_ BMS_BMinusContactorWeld : 1|1@1+ (1,0) [0|1] ""  SMART_CORE

BO_ 301 BMS1_10: 8 Vector__XXX
 SG_ BMS_ACTV_Discharge_STS : 40|3@1+ (1,0) [0|4] ""  SMART_CORE
 SG_ BMS273_COUNTER : 52|4@1+ (1,0) [0|14] "NA"  SMART_CORE
 SG_ BMS273_CRC : 56|8@1+ (1,0) [0|0] "NA"  SMART_CORE
 SG_ BMS_BatteryBusVoltage : 0|14@1+ (0.1,0) [0|460] "V"  SMART_CORE
 SG_ BMS_BatteryPackStatus : 44|3@1+ (1,0) [0|7] ""  SMART_CORE
 SG_ BMS_BatteryPackCurrent : 16|14@1+ (0.1,-600) [-600|600] "A"  SMART_CORE
 SG_ BMS_OperationMode : 48|4@1+ (1,0) [0|15] ""  SMART_CORE

BO_ 1003 BMS19_100: 8 Vector__XXX
 SG_ BMS_CellTemp9 m2 : 48|16@1+ (0.1,-50) [-40|125] "degC"  SMART_CORE
 SG_ BMS_CellTemp8 m2 : 32|16@1+ (0.1,-50) [-40|125] "degC"  SMART_CORE
 SG_ BMS_CellTemp7 m2 : 16|16@1+ (0.1,-50) [-40|125] "degC"  SMART_CORE
 SG_ BMS_CellTemp6 m1 : 48|16@1+ (0.1,-50) [-40|125] "degC"  SMART_CORE
 SG_ BMS_CellTemp5 m1 : 32|16@1+ (0.1,-50) [-40|125] "degC"  SMART_CORE
 SG_ BMS_CellTemp4 m1 : 16|16@1+ (0.1,-50) [-40|125] "degC"  SMART_CORE
 SG_ BMS_CellTemp32 m10 : 32|16@1+ (0.1,-50) [-40|125] "degC"  SMART_CORE
 SG_ BMS_CellTemp31 m10 : 16|16@1+ (0.1,-50) [-40|125] "degC"  SMART_CORE
 SG_ BMS_CellTemp30 m9 : 48|16@1+ (0.1,-50) [-40|125] "degC"  SMART_CORE
 SG_ BMS_CellTemp29 m9 : 32|16@1+ (0.1,-50) [-40|125] "degC"  SMART_CORE
 SG_ BMS_CellTemp28 m9 : 16|16@1+ (0.1,-50) [-40|125] "degC"  SMART_CORE
 SG_ BMS_CellTemp27 m8 : 48|16@1+ (0.1,-50) [-40|125] "degC"  SMART_CORE
 SG_ BMS_CellTemp26 m8 : 32|16@1+ (0.1,-50) [-40|125] "degC"  SMART_CORE
 SG_ BMS_CellTemp25 m8 : 16|16@1+ (0.1,-50) [-40|125] "degC"  SMART_CORE
 SG_ BMS_CellTemp24 m7 : 48|16@1+ (0.1,-50) [-40|125] "degC"  SMART_CORE
 SG_ BMS_CellTemp23 m7 : 32|16@1+ (0.1,-50) [-40|125] "degC"  SMART_CORE
 SG_ BMS_CellTemp22 m7 : 16|16@1+ (0.1,-50) [-40|125] "degC"  SMART_CORE
 SG_ BMS_CellTemp21 m6 : 48|16@1+ (0.1,-50) [-40|125] "degC"  SMART_CORE
 SG_ BMS_CellTemp20 m6 : 32|16@1+ (0.1,-50) [-40|125] "degC"  SMART_CORE
 SG_ BMS_CellTemp19 m6 : 16|16@1+ (0.1,-50) [-40|125] "degC"  SMART_CORE
 SG_ BMS_CellTemp18 m5 : 48|16@1+ (0.1,-50) [-40|125] "degC"  SMART_CORE
 SG_ BMS_CellTemp17 m5 : 32|16@1+ (0.1,-50) [-40|125] "degC"  SMART_CORE
 SG_ BMS_CellTemp16 m5 : 16|16@1+ (0.1,-50) [-40|125] "degC"  SMART_CORE
 SG_ BMS_CellTemp15 m4 : 48|16@1+ (0.1,-50) [-40|125] "degC"  SMART_CORE
 SG_ BMS_CellTemp14 m4 : 32|16@1+ (0.1,-50) [-40|125] "degC"  SMART_CORE
 SG_ BMS_CellTemp13 m4 : 16|16@1+ (0.1,-50) [-40|125] "degC"  SMART_CORE
 SG_ BMS_CellTemp12 m3 : 48|16@1+ (0.1,-50) [-40|125] "degC"  SMART_CORE
 SG_ BMS_CellTemp11 m3 : 32|16@1+ (0.1,-50) [-40|125] "degC"  SMART_CORE
 SG_ BMS_CellTemp10 m3 : 16|16@1+ (0.1,-50) [-40|125] "degC"  SMART_CORE
 SG_ BMS_CellTemp3 m0 : 48|16@1+ (0.1,-50) [-40|125] "degC"  SMART_CORE
 SG_ BMS_CellTemp2 m0 : 32|16@1+ (0.1,-50) [-40|125] "degC"  SMART_CORE
 SG_ BMS_CellTemp1 m0 : 16|16@1+ (0.1,-50) [-40|125] "degC"  SMART_CORE
 SG_ BMS_CellTemp_Index M : 0|8@1+ (1,0) [0|255] ""  SMART_CORE

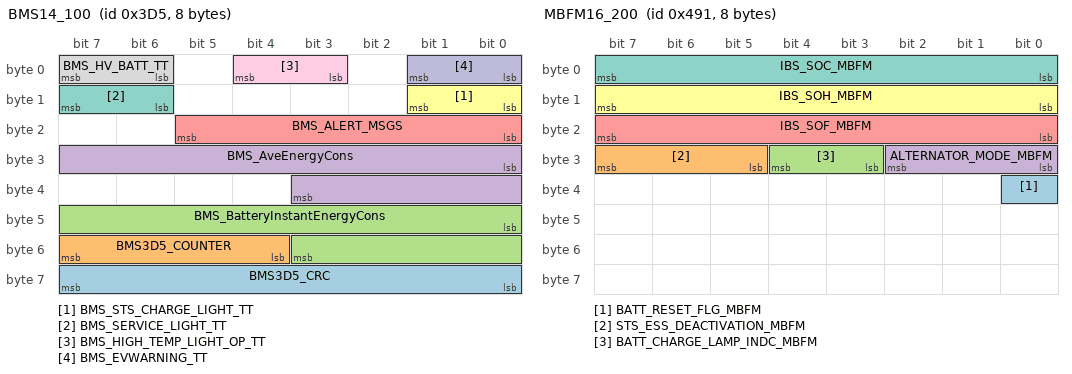
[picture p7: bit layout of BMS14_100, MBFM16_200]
BO_ 981 BMS14_100: 8 Vector__XXX
 SG_ BMS3D5_CRC : 56|8@1+ (1,0) [0|0] "NA"  SMART_CORE
 SG_ BMS3D5_COUNTER : 52|4@1+ (1,0) [0|14] "NA"  SMART_CORE
 SG_ BMS_BatteryInstantEnergyCons : 40|12@1+ (0.1,0) [0|45] "Kwh"  SMART_CORE
 SG_ BMS_AveEnergyCons : 24|12@1+ (0.1,0) [0|45] "Kwh"  SMART_CORE
 SG_ BMS_ALERT_MSGS : 16|6@1+ (1,0) [0|63] ""  SMART_CORE
 SG_ BMS_STS_CHARGE_LIGHT_TT : 8|2@1+ (1,0) [0|3] ""  SMART_CORE
 SG_ BMS_SERVICE_LIGHT_TT : 14|2@1+ (1,0) [0|3] ""  SMART_CORE
 SG_ BMS_HV_BATT_TT : 6|2@1+ (1,0) [0|3] ""  SMART_CORE
 SG_ BMS_HIGH_TEMP_LIGHT_OP_TT : 3|2@1+ (1,0) [0|3] ""  SMART_CORE
 SG_ BMS_EVWARNING_TT : 0|2@1+ (1,0) [0|3] ""  SMART_CORE

BO_ 1949 SBRM_DIAG_RES: 8 Vector__XXX
 SG_ DIAG_SBRM_RES_DATA : 0|64@1+ (1,0) [0|1.8446744074] ""  SMART_CORE

BO_ 1941 SBRM_DIAG_REQ: 8 SMART_CORE
 SG_ DIAG_SBRM_REQ_DATA : 0|64@1+ (1,0) [0|1.8446744074E+019] "" Vector__XXX

BO_ 779 FRM3_TEST_100: 8 Vector__XXX
 SG_ TIME_GAP_FRM : 40|8@1+ (0.1,0) [0|25.5] "sec"  SMART_CORE

BO_ 1852 FDHM_DIAG_RES: 8 Vector__XXX
 SG_ DIAG_FDHM_RES_DATA : 0|64@1+ (1,0) [0|1.8446744074E+019] ""  SMART_CORE

BO_ 1866 APA_DIAG_RES: 8 Vector__XXX
 SG_ DIAG_APA_RES_DATA : 0|64@1+ (1,0) [0|1.8446744074E+019] ""  SMART_CORE

BO_ 1585 ICC1_1000: 8 Vector__XXX
 SG_ TRANSFER_MODE_ICC : 4|2@1+ (1,0) [0|3] ""  SMART_CORE
 SG_ ICC_ALERT_MSG : 8|3@1+ (1,0) [0|7] ""  SMART_CORE

BO_ 1170 MBFM17_200: 8 Vector__XXX
 SG_ IBS_BATT_TEMP_MBFM : 32|16@1+ (0.5,-40) [-40|125] "DegC"  SMART_CORE
 SG_ IBS_BATT_VOLT_MBFM : 16|16@1+ (0.001,0) [4|24] "V"  SMART_CORE
 SG_ IBS_CURRENT_MBFM : 0|16@1+ (1,-1250) [-1250|1250] "Amps"  SMART_CORE

BO_ 1994 ICC_DIAG_RES: 8 Vector__XXX
 SG_ DIAG_ICC_RES_DATA : 0|64@1+ (1,0) [0|1.8446744074E+019] ""  SMART_CORE

BO_ 1169 MBFM16_200: 8 Vector__XXX
 SG_ BATT_RESET_FLG_MBFM : 32|1@1- (1,0) [0|1] ""  SMART_CORE
 SG_ STS_ESS_DEACTIVATION_MBFM : 29|3@1+ (1,0) [0|7] ""  SMART_CORE
 SG_ BATT_CHARGE_LAMP_INDC_MBFM : 27|2@1+ (1,0) [0|3] ""  SMART_CORE
 SG_ ALTERNATOR_MODE_MBFM : 24|3@1+ (1,0) [0|7] ""  SMART_CORE
 SG_ IBS_SOF_MBFM : 16|8@1+ (1,0) [0|100] "%"  SMART_CORE
 SG_ IBS_SOH_MBFM : 8|8@1+ (1,0) [0|100] "%"  SMART_CORE
 SG_ IBS_SOC_MBFM : 0|8@1+ (1,0) [0|100] "%"  SMART_CORE

BO_ 1988 HLCU1_DIAG_REQ: 8 SMART_CORE
 SG_ DIAG_HLCU_REQ_DATA : 0|64@1+ (1,0) [0|1.8446744074E+019] "" Vector__XXX

BO_ 2006 HLCU2_DIAG_REQ: 8 SMART_CORE
 SG_ DIAG_HLCU_REQ_DATA : 0|64@1+ (1,0) [0|1.8446744074E+019] "" Vector__XXX

BO_ 2019 TC_DIAG_REQ: 8 SMART_CORE
 SG_ DIAG_TC_REQ_DATA : 0|64@1+ (1,0) [0|1.8446744074E+019] "" Vector__XXX

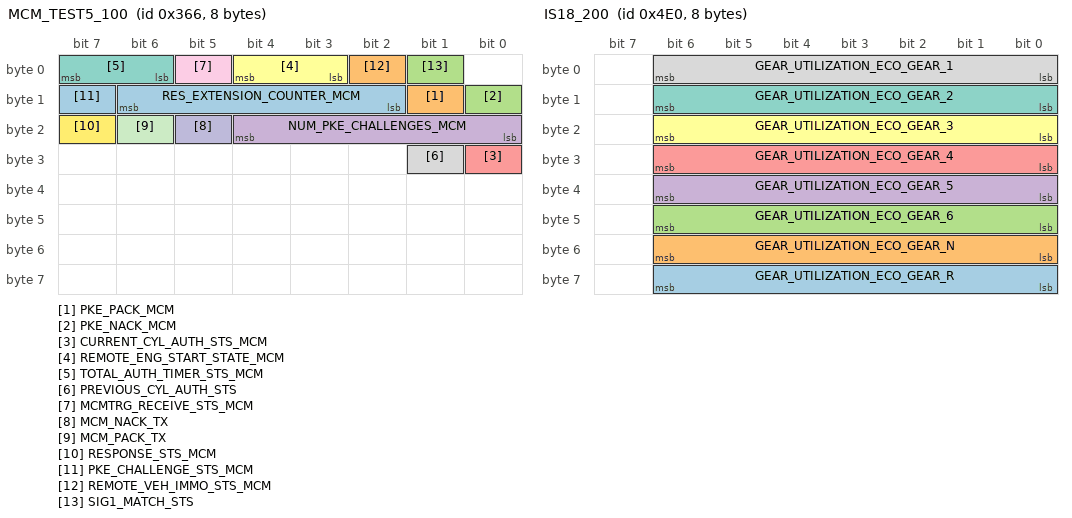
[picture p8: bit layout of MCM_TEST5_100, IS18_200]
BO_ 870 MCM_TEST5_100: 8 SMART_CORE
 SG_ RES_EXTENSION_COUNTER_MCM : 10|5@1+ (1,0) [0|31] "" Vector__XXX
 SG_ PKE_PACK_MCM : 9|1@1+ (1,0) [0|0] "" Vector__XXX
 SG_ PKE_NACK_MCM : 8|1@1+ (1,0) [0|0] "" Vector__XXX
 SG_ NUM_PKE_CHALLENGES_MCM : 16|5@1+ (1,0) [0|31] "" Vector__XXX
 SG_ CURRENT_CYL_AUTH_STS_MCM : 24|1@1+ (1,0) [0|1] "" Vector__XXX
 SG_ REMOTE_ENG_START_STATE_MCM : 3|2@1+ (1,0) [0|3] "" Vector__XXX
 SG_ TOTAL_AUTH_TIMER_STS_MCM : 6|2@1+ (1,0) [0|0] "" Vector__XXX
 SG_ PREVIOUS_CYL_AUTH_STS : 25|1@1+ (1,0) [0|1] "" Vector__XXX
 SG_ MCMTRG_RECEIVE_STS_MCM : 5|1@1+ (1,0) [0|1] "" Vector__XXX
 SG_ MCM_NACK_TX : 21|1@1+ (1,0) [0|1] "" Vector__XXX
 SG_ MCM_PACK_TX : 22|1@1+ (1,0) [0|1] "" Vector__XXX
 SG_ RESPONSE_STS_MCM : 23|1@1+ (1,0) [0|1] "" Vector__XXX
 SG_ PKE_CHALLENGE_STS_MCM : 15|1@1+ (1,0) [0|1] "" Vector__XXX
 SG_ REMOTE_VEH_IMMO_STS_MCM : 2|1@1+ (1,0) [0|1] "" Vector__XXX
 SG_ SIG1_MATCH_STS : 1|1@1+ (1,0) [0|1] "" Vector__XXX

BO_ 1654 MCM4_1000: 8 SMART_CORE
 SG_ UPDATE_REPROG_USER_AUTH : 2|2@1+ (1,0) [0|3] "" Vector__XXX
 SG_ UPDATE_DOWNLOAD_USER_AUTH : 0|2@1+ (1,0) [0|3] "" Vector__XXX
 SG_ MCM4_CRC : 56|8@1+ (1,0) [0|255] "" Vector__XXX
 SG_ MCM4_CNT : 52|4@1+ (1,0) [0|15] "" Vector__XXX

BO_ 1958 SCM_DIAG_REQ: 8 SMART_CORE
 SG_ DIAG_SCM_REQ_DATA : 0|64@1+ (1,0) [0|1.8446744074E+019] "" Vector__XXX

BO_ 1959 FVC_DIAG_REQ: 8 SMART_CORE
 SG_ DIAG_FVC_REQ_DATA : 0|64@1+ (1,0) [0|1.8446744074E+019] "" Vector__XXX

BO_ 1842 FRM_DIAG_REQ: 8 SMART_CORE
 SG_ DIAG_FRM_REQ_DATA : 0|64@1+ (1,0) [0|1.8446744074E+019] "" Vector__XXX

BO_ 1986 ICC_DIAG_REQ: 8 SMART_CORE
 SG_ DIAG_ICC_REQ_DATA : 0|64@1+ (1,0) [0|1.8446744074E+019] "" Vector__XXX

BO_ 1858 APA_DIAG_REQ: 8 SMART_CORE
 SG_ DIAG_APA_REQ_DATA : 0|64@1+ (1,0) [0|1.8446744074E+019] "" Vector__XXX

BO_ 1859 AMP_DIAG_REQ: 8 SMART_CORE
 SG_ DIAG_AMP_REQ_DATA : 0|64@1+ (1,0) [0|1.8446744074E+019] "" Vector__XXX

BO_ 1248 IS18_200: 8 SMART_CORE
 SG_ GEAR_UTILIZATION_ECO_GEAR_R : 56|7@1+ (1,0) [0|100] "perKM" Vector__XXX
 SG_ GEAR_UTILIZATION_ECO_GEAR_N : 48|7@1+ (1,0) [0|100] "perKM" Vector__XXX
 SG_ GEAR_UTILIZATION_ECO_GEAR_6 : 40|7@1+ (1,0) [0|100] "perKM" Vector__XXX
 SG_ GEAR_UTILIZATION_ECO_GEAR_5 : 32|7@1+ (1,0) [0|100] "perKM" Vector__XXX
 SG_ GEAR_UTILIZATION_ECO_GEAR_4 : 24|7@1+ (1,0) [0|100] "perKM" Vector__XXX
 SG_ GEAR_UTILIZATION_ECO_GEAR_3 : 16|7@1+ (1,0) [0|100] "perKM" Vector__XXX
 SG_ GEAR_UTILIZATION_ECO_GEAR_2 : 8|7@1+ (1,0) [0|100] "perKM" Vector__XXX
 SG_ GEAR_UTILIZATION_ECO_GEAR_1 : 0|7@1+ (1,0) [0|100] "perKM" Vector__XXX

BO_ 2017 TCU_DIAG_REQ: 8 SMART_CORE
 SG_ DIAG_TCU_REQ_DATA : 0|64@1+ (1,0) [0|1.8446744074E+019] "" Vector__XXX

BO_ 1955 WLC_DIAG_REQ: 8 SMART_CORE
 SG_ DIAG_WLC_REQ_DATA : 0|64@1+ (1,0) [0|1.84467440737096E+019] "" Vector__XXX

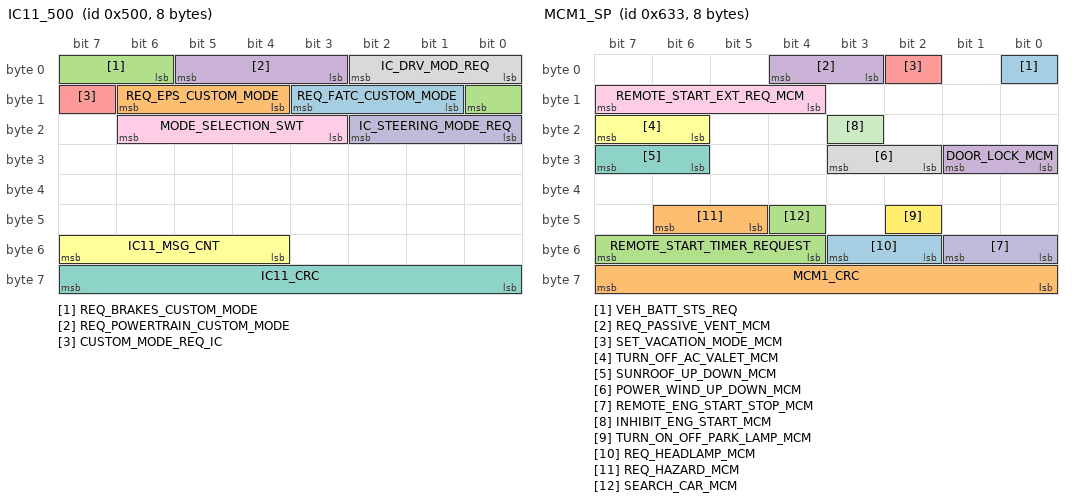
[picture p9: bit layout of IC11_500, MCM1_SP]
BO_ 1280 IC11_500: 8 SMART_CORE
 SG_ REQ_FATC_CUSTOM_MODE : 9|3@1+ (1,0) [0|0] "" Vector__XXX
 SG_ REQ_EPS_CUSTOM_MODE : 12|3@1+ (1,0) [0|7] "" Vector__XXX
 SG_ REQ_BRAKES_CUSTOM_MODE : 6|3@1+ (1,0) [0|7] "" Vector__XXX
 SG_ REQ_POWERTRAIN_CUSTOM_MODE : 3|3@1+ (1,0) [0|7] "" Vector__XXX
 SG_ CUSTOM_MODE_REQ_IC : 15|1@1+ (1,0) [0|1] "" Vector__XXX
 SG_ IC11_MSG_CNT : 52|4@1+ (1,0) [0|15] "" Vector__XXX
 SG_ IC11_CRC : 56|8@1+ (1,0) [0|255] "" Vector__XXX
 SG_ IC_DRV_MOD_REQ : 0|3@1+ (1,0) [0|7] "" Vector__XXX
 SG_ MODE_SELECTION_SWT : 19|4@1+ (1,0) [0|15] "" Vector__XXX
 SG_ IC_STEERING_MODE_REQ : 16|3@1+ (1,0) [0|7] "" Vector__XXX

BO_ 154 MCM_WAKEUP: 8 SMART_CORE
 SG_ MCM_WAKEUP_REASON : 0|16@1+ (1,0) [0|65535] "" Vector__XXX

BO_ 955 MCM_SLEEP: 8 SMART_CORE
 SG_ RESERVED_3 : 0|64@1+ (1,0) [0|1.8446744074E+019] "" Vector__XXX

BO_ 957 MCM_ACTIVE: 8 SMART_CORE
 SG_ RESERVED_3 : 0|64@1+ (1,0) [0|1.8446744074E+019] "" Vector__XXX

BO_ 1587 MCM1_SP: 8 SMART_CORE
 SG_ VEH_BATT_STS_REQ : 0|1@1+ (1,0) [0|1] "" Vector__XXX
 SG_ MCM1_CRC : 56|8@1+ (1,0) [0|0] "" Vector__XXX
 SG_ REMOTE_START_TIMER_REQUEST : 52|4@1+ (1,0) [0|15] "minutes" Vector__XXX
 SG_ REQ_PASSIVE_VENT_MCM : 3|2@1+ (1,0) [0|3] "" Vector__XXX
 SG_ SET_VACATION_MODE_MCM : 2|1@1+ (1,0) [0|1] "" Vector__XXX
 SG_ TURN_OFF_AC_VALET_MCM : 22|2@1+ (1,0) [0|3] "" Vector__XXX
 SG_ SUNROOF_UP_DOWN_MCM : 30|2@1+ (1,0) [0|3] "" Vector__XXX
 SG_ POWER_WIND_UP_DOWN_MCM : 26|2@1+ (1,0) [0|3] "" Vector__XXX
 SG_ REMOTE_START_EXT_REQ_MCM : 12|4@1+ (1,0) [0|15] "" Vector__XXX
 SG_ REMOTE_ENG_START_STOP_MCM : 48|2@1+ (1,0) [0|3] "" Vector__XXX
 SG_ INHIBIT_ENG_START_MCM : 19|1@1+ (1,0) [0|1] "" Vector__XXX
 SG_ TURN_ON_OFF_PARK_LAMP_MCM : 42|1@1+ (1,0) [0|1] "" Vector__XXX
 SG_ REQ_HEADLAMP_MCM : 50|2@1+ (1,0) [0|3] "" Vector__XXX
 SG_ REQ_HAZARD_MCM : 45|2@1+ (1,0) [0|3] "" Vector__XXX
 SG_ SEARCH_CAR_MCM : 44|1@1+ (1,0) [0|1] "" Vector__XXX
 SG_ DOOR_LOCK_MCM : 24|2@1+ (1,0) [0|3] "" Vector__XXX

BO_ 1856 FATC_DIAG_REQ: 8 SMART_CORE
 SG_ DIAG_FATC_REQ_DATA : 0|64@1+ (1,0) [0|1.8446744074E+019] "" Vector__XXX

BO_ 1144 SBRM1_100: 8 Vector__XXX
 SG_ PSGR_REAR_SEAT_BELT_SBRM : 2|6@1+ (1,0) [0|63] ""  SMART_CORE

BO_ 1963 WLC_DIAG_RES: 8 Vector__XXX
 SG_ DIAG_WLC_RES_DATA : 0|64@1+ (1,0) [0|1.84467440737096E+019] ""  SMART_CORE

BO_ 956 WLC_ACTIVE: 8 Vector__XXX
 SG_ RESERVED_2 : 0|64@1+ (1,0) [0|1.84467440737096E+019] ""  SMART_CORE

BO_ 786 EMS13_200: 8 Vector__XXX
 SG_ IBS_CURRENT : 0|16@1+ (1,-1250) [-1250|1250] "Amps"  SMART_CORE
 SG_ IBS_BATT_TEMP : 32|16@1+ (0.5,-40) [-40|125] "DegC"  SMART_CORE
 SG_ IBS_BATT_VOLT : 16|16@1+ (0.001,0) [4|24] "V"  SMART_CORE

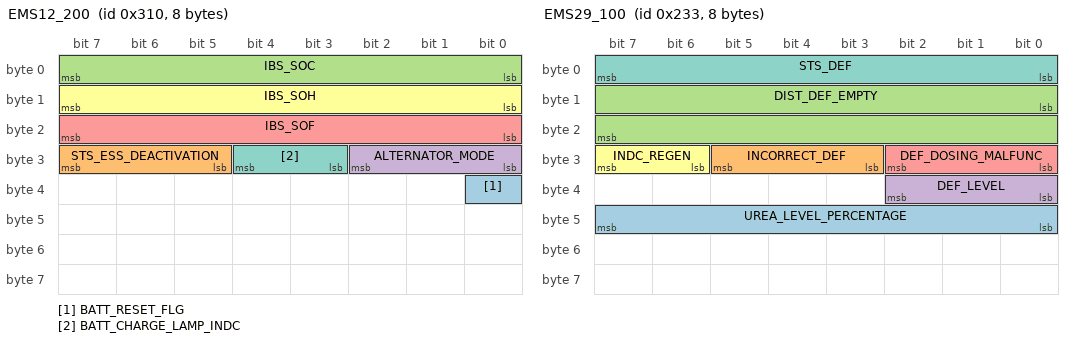
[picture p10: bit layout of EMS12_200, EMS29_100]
BO_ 784 EMS12_200: 8 Vector__XXX
 SG_ BATT_RESET_FLG : 32|1@1- (1,0) [0|1] ""  SMART_CORE
 SG_ STS_ESS_DEACTIVATION : 29|3@1+ (1,0) [0|7] ""  SMART_CORE
 SG_ IBS_SOC : 0|8@1+ (1,0) [0|100] "%"  SMART_CORE
 SG_ ALTERNATOR_MODE : 24|3@1+ (1,0) [0|7] ""  SMART_CORE
 SG_ IBS_SOF : 16|8@1+ (1,0) [0|100] "%"  SMART_CORE
 SG_ IBS_SOH : 8|8@1+ (1,0) [0|100] "%"  SMART_CORE
 SG_ BATT_CHARGE_LAMP_INDC : 27|2@1+ (1,0) [0|3] ""  SMART_CORE

BO_ 563 EMS29_100: 8 Vector__XXX
 SG_ UREA_LEVEL_PERCENTAGE : 40|8@1+ (1,0) [0|100] "%"  SMART_CORE
 SG_ INCORRECT_DEF : 27|3@1+ (1,0) [0|4] ""  SMART_CORE
 SG_ DIST_DEF_EMPTY : 8|16@1+ (1,0) [0|2400] "km"  SMART_CORE
 SG_ DEF_LEVEL : 32|3@1+ (1,0) [0|4] ""  SMART_CORE
 SG_ DEF_DOSING_MALFUNC : 24|3@1+ (1,0) [0|4] ""  SMART_CORE
 SG_ INDC_REGEN : 30|2@1+ (1,0) [0|3] ""  SMART_CORE
 SG_ STS_DEF : 0|8@1+ (1,0) [0|255] ""  SMART_CORE

BO_ 295 EMS21_10: 8 Vector__XXX
 SG_ ACC_PED_ACTUAL : 32|8@1+ (0.4,0) [0|100] "%"  SMART_CORE
 SG_ ENG_LOSSES : 40|11@1+ (1,-1024) [-1024|1021] "NM"  SMART_CORE
 SG_ EMS21_MSG_CNT : 52|4@1+ (1,0) [0|15] ""  SMART_CORE
 SG_ EMS21_CRC : 56|8@1+ (1,0) [0|255] ""  SMART_CORE
 SG_ BRK_PEDAL1 : 27|2@1+ (1,0) [0|3] ""  SMART_CORE

BO_ 375 AMT6_20: 8 Vector__XXX
 SG_ TGS_LEVER_AMT : 16|4@1+ (1,0) [0|15] ""  SMART_CORE
 SG_ AMT_BUZZER : 34|1@1+ (1,0) [0|1] ""  SMART_CORE
 SG_ AMT_MIL : 22|2@1+ (1,0) [0|3] ""  SMART_CORE
 SG_ ALERT_AMT : 29|3@1+ (1,0) [0|7] ""  SMART_CORE

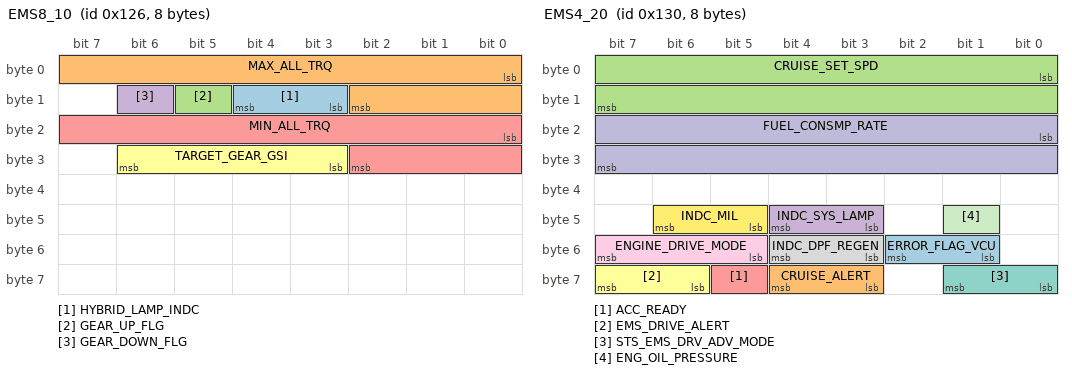
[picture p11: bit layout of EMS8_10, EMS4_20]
BO_ 294 EMS8_10: 8 Vector__XXX
 SG_ HYBRID_LAMP_INDC : 11|2@1+ (1,0) [0|2] ""  SMART_CORE
 SG_ MAX_ALL_TRQ : 0|11@1+ (1,-1024) [-1024|1022] "Nm"  SMART_CORE
 SG_ GEAR_UP_FLG : 13|1@1+ (1,0) [0|1] ""  SMART_CORE
 SG_ GEAR_DOWN_FLG : 14|1@1+ (1,0) [0|1] ""  SMART_CORE
 SG_ MIN_ALL_TRQ : 16|11@1+ (1,-1024) [-1024|1022] "Nm"  SMART_CORE
 SG_ TARGET_GEAR_GSI : 27|4@1+ (1,0) [0|15] ""  SMART_CORE

BO_ 304 EMS4_20: 8 Vector__XXX
 SG_ ERROR_FLAG_VCU : 49|2@1+ (1,0) [0|3] ""  SMART_CORE
 SG_ CRUISE_ALERT : 59|2@1+ (1,0) [0|3] ""  SMART_CORE
 SG_ CRUISE_SET_SPD : 0|16@1+ (0.015625,0) [0|300] "kmph"  SMART_CORE
 SG_ INDC_SYS_LAMP : 43|2@1+ (1,0) [0|3] ""  SMART_CORE
 SG_ ACC_READY : 61|1@1+ (1,0) [0|1] ""  SMART_CORE
 SG_ EMS_DRIVE_ALERT : 62|2@1+ (1,0) [0|3] ""  SMART_CORE
 SG_ STS_EMS_DRV_ADV_MODE : 56|2@1+ (1,0) [0|3] ""  SMART_CORE
 SG_ INDC_DPF_REGEN : 51|2@1+ (1,0) [0|3] ""  SMART_CORE
 SG_ ENGINE_DRIVE_MODE : 53|3@1+ (1,0) [0|7] ""  SMART_CORE
 SG_ FUEL_CONSMP_RATE : 16|16@1+ (1,0) [0|65534] "ul/20ms"  SMART_CORE
 SG_ ENG_OIL_PRESSURE : 41|1@1+ (1,0) [0|1] ""  SMART_CORE
 SG_ INDC_MIL : 45|2@1+ (1,0) [0|3] ""  SMART_CORE

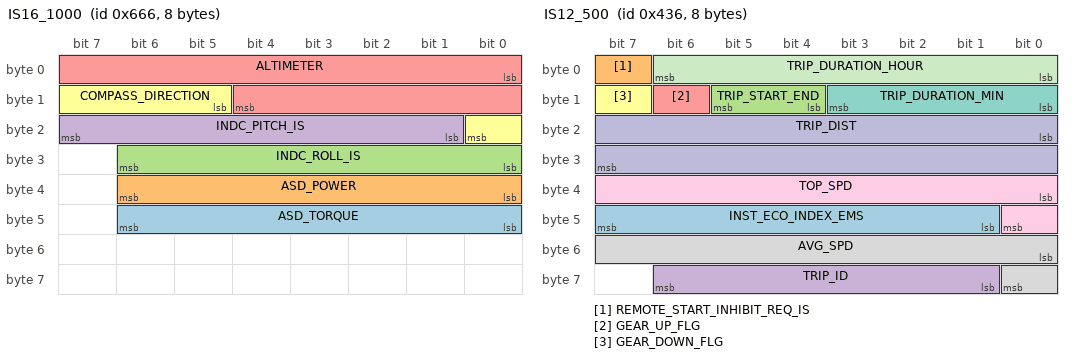
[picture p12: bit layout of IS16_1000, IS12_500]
BO_ 1638 IS16_1000: 8 SMART_CORE
 SG_ ASD_TORQUE : 40|7@1+ (1,0) [0|100] "%" Vector__XXX
 SG_ ASD_POWER : 32|7@1+ (1,0) [0|100] "%" Vector__XXX
 SG_ INDC_ROLL_IS : 24|7@1+ (1,-62) [-62|65] "Deg" Vector__XXX
 SG_ INDC_PITCH_IS : 17|7@1+ (1,-62) [-62|65] "Deg" Vector__XXX
 SG_ ALTIMETER : 0|13@1+ (1,0) [0|8192] "m" Vector__XXX
 SG_ COMPASS_DIRECTION : 13|4@1+ (1,0) [0|15] "" Vector__XXX

BO_ 1079 IS13_500: 8 SMART_CORE
 SG_ ESS_DURATION : 8|12@1+ (0.1,0) [0|409.5] "MIN" Vector__XXX
 SG_ IDLING_DURATION : 0|8@1+ (1,0) [0|254] "min" Vector__XXX

BO_ 1078 IS12_500: 8 SMART_CORE
 SG_ INST_ECO_INDEX_EMS : 41|7@1+ (1,0) [0|100] "" Vector__XXX
 SG_ REMOTE_START_INHIBIT_REQ_IS : 7|1@1+ (1,0) [0|1] "" Vector__XXX
 SG_ TRIP_START_END : 12|2@1+ (1,0) [0|3] "" Vector__XXX
 SG_ TRIP_ID : 57|6@1+ (1,0) [0|63] "" Vector__XXX
 SG_ GEAR_UP_FLG : 14|1@1+ (1,0) [0|1] "" Vector__XXX
 SG_ GEAR_DOWN_FLG : 15|1@1+ (1,0) [0|1] "" Vector__XXX
 SG_ TRIP_DURATION_MIN : 8|4@1+ (1,0) [0|14] "min" Vector__XXX
 SG_ AVG_SPD : 48|9@1+ (1,0) [0|300] "KMPH" Vector__XXX
 SG_ TOP_SPD : 32|9@1+ (1,0) [0|300] "kmph" Vector__XXX
 SG_ TRIP_DIST : 16|16@1+ (0.1,0) [0|6553.4] "km" Vector__XXX
 SG_ TRIP_DURATION_HOUR : 0|7@1+ (1,0) [0|126] "Hours" Vector__XXX

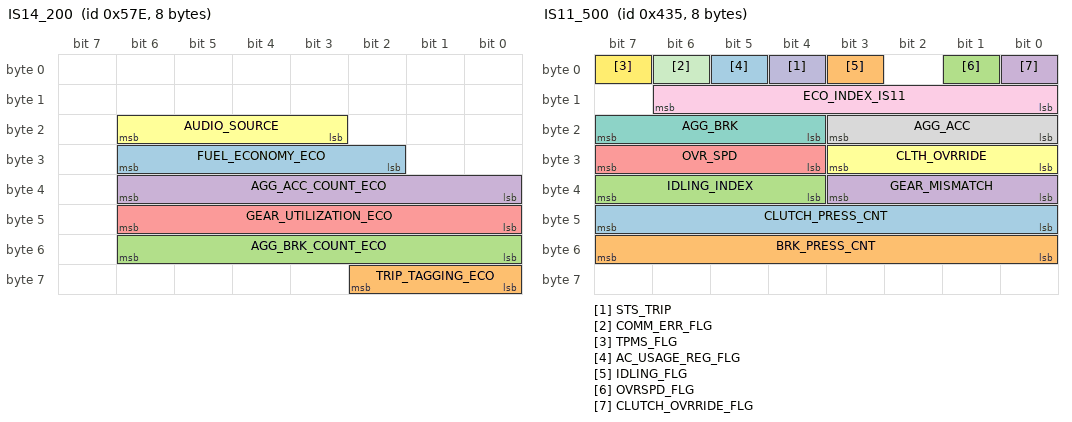
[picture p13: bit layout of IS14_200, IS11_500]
BO_ 1406 IS14_200: 8 SMART_CORE
 SG_ FUEL_ECONOMY_ECO : 26|5@1+ (1,0) [0|0] "" Vector__XXX
 SG_ TRIP_TAGGING_ECO : 56|3@1+ (1,0) [0|0] "" Vector__XXX
 SG_ AGG_BRK_COUNT_ECO : 48|7@1+ (1,0) [0|100] "perKM" Vector__XXX
 SG_ AGG_ACC_COUNT_ECO : 32|7@1+ (1,0) [0|100] "perKM" Vector__XXX
 SG_ GEAR_UTILIZATION_ECO : 40|7@1+ (1,0) [0|100] "perKM" Vector__XXX
 SG_ AUDIO_SOURCE : 19|4@1+ (1,0) [0|15] "" Vector__XXX

BO_ 1077 IS11_500: 8 SMART_CORE
 SG_ CLUTCH_PRESS_CNT : 40|8@1+ (1,0) [0|253] "" Vector__XXX
 SG_ BRK_PRESS_CNT : 48|8@1+ (1,0) [0|253] "" Vector__XXX
 SG_ IDLING_INDEX : 36|4@1+ (1,0) [0|15] "" Vector__XXX
 SG_ GEAR_MISMATCH : 32|4@1+ (1,0) [0|15] "" Vector__XXX
 SG_ OVR_SPD : 28|4@1+ (1,0) [0|15] "" Vector__XXX
 SG_ CLTH_OVRRIDE : 24|4@1+ (1,0) [0|15] "" Vector__XXX
 SG_ AGG_BRK : 20|4@1+ (1,0) [0|15] "" Vector__XXX
 SG_ AGG_ACC : 16|4@1+ (1,0) [0|15] "" Vector__XXX
 SG_ ECO_INDEX_IS11 : 8|7@1+ (1,0) [0|127] "" Vector__XXX
 SG_ STS_TRIP : 4|1@1+ (1,0) [0|1] "" Vector__XXX
 SG_ COMM_ERR_FLG : 6|1@1+ (1,0) [0|1] "" Vector__XXX
 SG_ TPMS_FLG : 7|1@1+ (1,0) [0|1] "" Vector__XXX
 SG_ AC_USAGE_REG_FLG : 5|1@1+ (1,0) [0|1] "" Vector__XXX
 SG_ IDLING_FLG : 3|1@1+ (1,0) [0|1] "" Vector__XXX
 SG_ OVRSPD_FLG : 1|1@1+ (1,0) [0|1] "" Vector__XXX
 SG_ CLUTCH_OVRRIDE_FLG : 0|1@1+ (1,0) [0|1] "" Vector__XXX

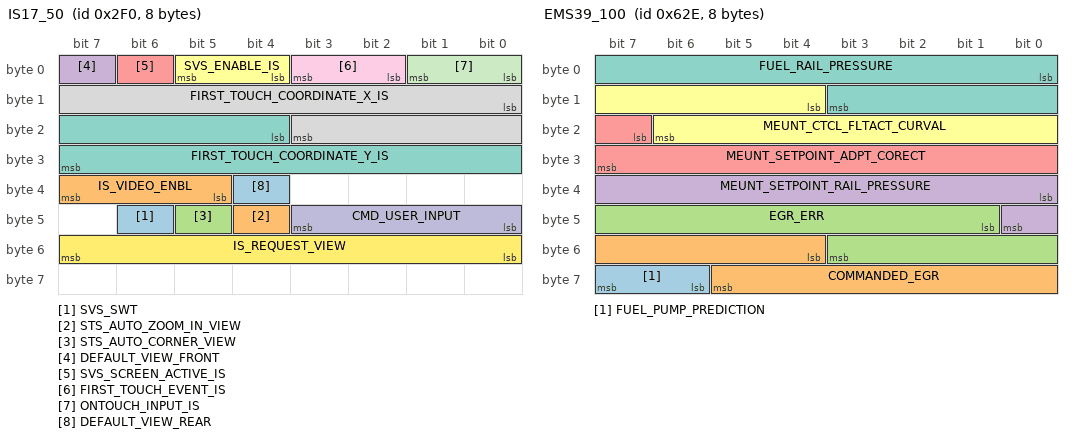
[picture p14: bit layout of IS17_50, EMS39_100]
BO_ 752 IS17_50: 8 SMART_CORE
 SG_ SVS_SWT : 46|1@1+ (1,0) [0|1] "" Vector__XXX
 SG_ STS_AUTO_ZOOM_IN_VIEW : 44|1@1+ (1,0) [0|1] "" Vector__XXX
 SG_ STS_AUTO_CORNER_VIEW : 45|1@1+ (1,0) [0|1] "" Vector__XXX
 SG_ DEFAULT_VIEW_FRONT : 7|1@1+ (1,0) [0|0] "" Vector__XXX
 SG_ SVS_SCREEN_ACTIVE_IS : 6|1@1+ (1,0) [0|1] "" Vector__XXX
 SG_ SVS_ENABLE_IS : 4|2@1+ (1,0) [0|0] "" Vector__XXX
 SG_ FIRST_TOUCH_COORDINATE_Y_IS : 20|12@1+ (0.025,0) [0|100] "%" Vector__XXX
 SG_ FIRST_TOUCH_COORDINATE_X_IS : 8|12@1+ (0.025,0) [0|100] "%" Vector__XXX
 SG_ FIRST_TOUCH_EVENT_IS : 2|2@1+ (1,0) [0|3] "" Vector__XXX
 SG_ CMD_USER_INPUT : 40|4@1+ (1,0) [0|15] "" Vector__XXX
 SG_ ONTOUCH_INPUT_IS : 0|2@1+ (1,0) [0|3] "" Vector__XXX
 SG_ IS_REQUEST_VIEW : 48|8@1+ (1,0) [0|255] "" Vector__XXX
 SG_ DEFAULT_VIEW_REAR : 36|1@1+ (1,0) [0|0] "" Vector__XXX
 SG_ IS_VIDEO_ENBL : 37|3@1+ (1,0) [0|7] "" Vector__XXX

BO_ 1584 EMS42_100: 8 Vector__XXX
 SG_ NOX_UPSTR_MDL : 0|9@1+ (4,0) [0|2000] ""  SMART_CORE

BO_ 1595 EMS44_100: 8 Vector__XXX
 SG_ KNOCK_SIGNALS_0 : 0|8@1+ (1,0) [0|255] ""  SMART_CORE
 SG_ KNOCK_SIGNALS_1 : 8|8@1+ (1,0) [0|255] ""  SMART_CORE
 SG_ KNOCK_SIGNALS_2 : 16|8@1+ (1,0) [0|255] ""  SMART_CORE
 SG_ KNOCK_SIGNALS_3 : 24|8@1+ (1,0) [0|255] ""  SMART_CORE
 SG_ MASS_AIR_FLOW : 32|8@1+ (4,0) [0|1020] ""  SMART_CORE
 SG_ MISFIRE_DETECT_THRESHOLD : 40|8@1+ (64,-12000) [-12000|4000] ""  SMART_CORE
 SG_ MISFIRE_SUM_A : 48|8@1+ (1,0) [0|255] ""  SMART_CORE
 SG_ MISFIRE_SUM_B : 56|8@1+ (1,0) [0|255] ""  SMART_CORE

BO_ 1596 EMS45_100: 8 Vector__XXX
 SG_ MISFIRE_CTR_A_0 : 0|8@1+ (1,0) [0|255] ""  SMART_CORE
 SG_ MISFIRE_CTR_A_1 : 8|8@1+ (1,0) [0|255] ""  SMART_CORE
 SG_ MISFIRE_CTR_A_2 : 16|8@1+ (1,0) [0|255] ""  SMART_CORE
 SG_ MISFIRE_CTR_A_3 : 24|8@1+ (1,0) [0|255] ""  SMART_CORE
 SG_ MISFIRE_CTR_B_0 : 32|8@1+ (1,0) [0|255] ""  SMART_CORE
 SG_ MISFIRE_CTR_B_1 : 40|8@1+ (1,0) [0|255] ""  SMART_CORE
 SG_ MISFIRE_CTR_B_2 : 48|8@1+ (1,0) [0|255] ""  SMART_CORE
 SG_ MISFIRE_CTR_B_3 : 56|8@1+ (1,0) [0|255] ""  SMART_CORE

BO_ 1428 ESC15_1000: 8 Vector__XXX
 SG_ BRAKE_PREDICTION_STS : 0|2@1+ (1,0) [0|3] ""  SMART_CORE

BO_ 661 TC_NSM: 8 Vector__XXX
 SG_ RESERVED_TC : 0|64@1+ (1,0) [0|0] ""  SMART_CORE

BO_ 922 SVS1_10: 8 Vector__XXX
 SG_ SVS_VIEW_REQUEST_IC : 10|1@1+ (1,0) [0|1] ""  SMART_CORE
 SG_ SVS_VIEW_REQUEST_IS : 9|1@1+ (1,0) [0|1] ""  SMART_CORE
 SG_ SVS_INFO : 8|1@1+ (1,0) [0|1] ""  SMART_CORE
 SG_ SVS_GUIDED_VOICE_REQ : 0|4@1+ (1,0) [0|15] ""  SMART_CORE

BO_ 1867 AMP_DIAG_RES: 8 Vector__XXX
 SG_ DIAG_AMP_RES_DATA : 0|64@1+ (1,0) [0|1.8446744074E+019] ""  SMART_CORE

BO_ 1582 EMS39_100: 8 Vector__XXX
 SG_ FUEL_PUMP_PREDICTION : 62|2@1+ (1,0) [0|0] ""  SMART_CORE
 SG_ COMMANDED_EGR : 52|10@1+ (0.1,-30) [-30|50] ""  SMART_CORE
 SG_ EGR_ERR : 41|11@1- (0.1,-60) [-60|60] ""  SMART_CORE
 SG_ MEUNT_SETPOINT_RAIL_PRESSURE : 32|9@1+ (10,-2000) [-2000|2000] ""  SMART_CORE
 SG_ MEUNT_SETPOINT_ADPT_CORECT : 23|9@1+ (10,-2000) [-2000|2000] ""  SMART_CORE
 SG_ MEUNT_CTCL_FLTACT_CURVAL : 12|11@1+ (1,-100) [-100|1000] ""  SMART_CORE
 SG_ FUEL_RAIL_PRESSURE : 0|12@1+ (1000,-100000) [-100000|2000000] ""  SMART_CORE

BO_ 1965 SVS_DIAG_RES: 8 Vector__XXX
 SG_ DIAG_SVS_RES_DATA : 0|64@1+ (1,0) [0|1.8446744074E+019] ""  SMART_CORE

BO_ 1967 FVC_DIAG_RES: 8 Vector__XXX
 SG_ DIAG_FVC_RES_DATA : 0|64@1+ (1,0) [0|1.8446744074] ""  SMART_CORE

BO_ 2014 HLCU2_DIAG_RES: 8 Vector__XXX
 SG_ DIAG_HLCU_RES_DATA : 0|64@1+ (1,0) [0|1.8446744074E+019] ""  SMART_CORE

BO_ 1996 HLCU1_DIAG_RES: 8 Vector__XXX
 SG_ DIAG_HLCU_RES_DATA : 0|64@1+ (1,0) [0|1.8446744074E+019] ""  SMART_CORE

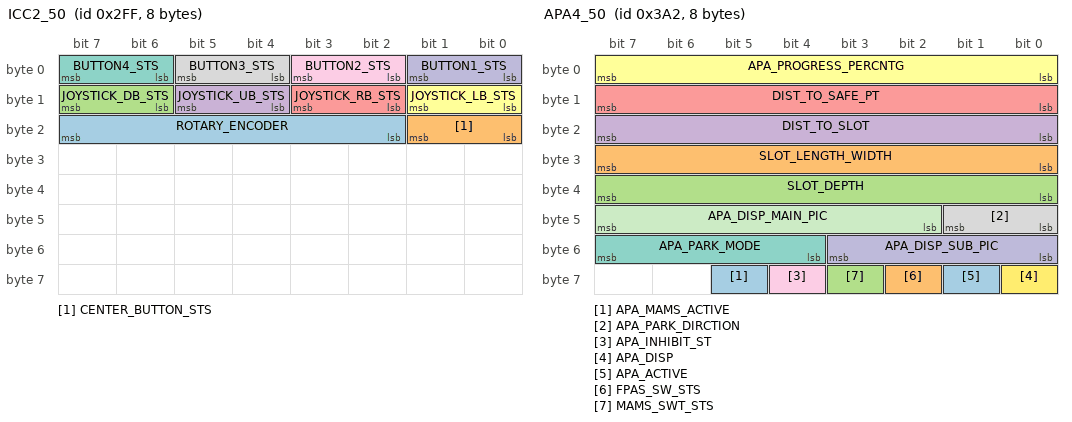
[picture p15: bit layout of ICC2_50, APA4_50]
BO_ 767 ICC2_50: 8 Vector__XXX
 SG_ ROTARY_ENCODER : 18|6@1+ (1,0) [0|64] ""  SMART_CORE
 SG_ CENTER_BUTTON_STS : 16|2@1+ (1,0) [0|3] ""  SMART_CORE
 SG_ JOYSTICK_DB_STS : 14|2@1+ (1,0) [0|3] ""  SMART_CORE
 SG_ JOYSTICK_UB_STS : 12|2@1+ (1,0) [0|3] ""  SMART_CORE
 SG_ JOYSTICK_RB_STS : 10|2@1+ (1,0) [0|3] ""  SMART_CORE
 SG_ JOYSTICK_LB_STS : 8|2@1+ (1,0) [0|3] ""  SMART_CORE
 SG_ BUTTON4_STS : 6|2@1+ (1,0) [0|3] ""  SMART_CORE
 SG_ BUTTON3_STS : 4|2@1+ (1,0) [0|3] ""  SMART_CORE
 SG_ BUTTON2_STS : 2|2@1+ (1,0) [0|3] ""  SMART_CORE
 SG_ BUTTON1_STS : 0|2@1+ (1,0) [0|3] ""  SMART_CORE

BO_ 917 FVC1_100: 8 Vector__XXX
 SG_ FVC_OPERATION_STATE : 4|3@1+ (1,0) [0|5] ""  SMART_CORE
 SG_ FVC_BUTTON_GROUP : 0|4@1+ (1,0) [0|9] ""  SMART_CORE

BO_ 2027 TC_DIAG_RES: 8 Vector__XXX
 SG_ DIAG_TC_RES_DATA : 0|64@1+ (1,0) [0|1.8446744074E+019] ""  SMART_CORE

BO_ 1966 SCM_DIAG_RES: 8 Vector__XXX
 SG_ DIAG_SCM_RES_DATA : 0|64@1+ (1,0) [0|1.8446744074] ""  SMART_CORE

BO_ 1850 FRM_DIAG_RES: 8 Vector__XXX
 SG_ DIAG_FRM_RES_DATA : 0|64@1+ (1,0) [0|1.8446744074E+019] ""  SMART_CORE

BO_ 666 FRM_NSM: 8 Vector__XXX
 SG_ RESERVED_FRM : 0|64@1+ (1,0) [0|0] ""  SMART_CORE

BO_ 930 APA4_50: 8 Vector__XXX
 SG_ APA_MAMS_ACTIVE : 61|1@1+ (1,0) [0|1] ""  SMART_CORE
 SG_ SLOT_LENGTH_WIDTH : 24|8@1+ (5,0) [0|800] "cm"  SMART_CORE
 SG_ SLOT_DEPTH : 32|8@1+ (2,0) [0|500] "cm"  SMART_CORE
 SG_ DIST_TO_SLOT : 16|8@1+ (5,0) [0|1000] "cm"  SMART_CORE
 SG_ DIST_TO_SAFE_PT : 8|8@1+ (5,0) [0|1000] "cm"  SMART_CORE
 SG_ APA_PROGRESS_PERCNTG : 0|8@1+ (1,0) [0|100] "%"  SMART_CORE
 SG_ APA_PARK_MODE : 52|4@1+ (1,0) [0|15] ""  SMART_CORE
 SG_ APA_PARK_DIRCTION : 40|2@1+ (1,0) [0|3] ""  SMART_CORE
 SG_ APA_INHIBIT_ST : 60|1@1+ (1,0) [0|1] ""  SMART_CORE
 SG_ APA_DISP_SUB_PIC : 48|4@1+ (1,0) [0|15] ""  SMART_CORE
 SG_ APA_DISP_MAIN_PIC : 42|6@1+ (1,0) [0|63] ""  SMART_CORE
 SG_ APA_DISP : 56|1@1+ (1,0) [0|1] ""  SMART_CORE
 SG_ APA_ACTIVE : 57|1@1+ (1,0) [0|1] ""  SMART_CORE
 SG_ FPAS_SW_STS : 58|1@1+ (1,0) [0|1] ""  SMART_CORE
 SG_ MAMS_SWT_STS : 59|1@1+ (1,0) [0|1] ""  SMART_CORE

BO_ 929 APA3_50: 8 Vector__XXX
 SG_ FLS_SEGMENT : 0|4@1+ (1,0) [0|15] ""  SMART_CORE
 SG_ LEFT_MIN_DIST : 40|8@1+ (2,0) [0|500] "cm"  SMART_CORE
 SG_ RRMS_SEGMENT : 24|4@1+ (1,0) [0|15] ""  SMART_CORE
 SG_ APA_SWITCH_FAULT : 59|3@1+ (1,0) [0|7] ""  SMART_CORE
 SG_ FRMS_SEGMENT : 8|4@1+ (1,0) [0|15] ""  SMART_CORE
 SG_ RIGHT_MIN_DIST : 48|8@1+ (2,0) [0|500] "cm"  SMART_CORE
 SG_ RRS_SEG_WARN : 39|1@1+ (1,0) [0|1] ""  SMART_CORE
 SG_ RRMS_SEG_WARN : 38|1@1+ (1,0) [0|1] ""  SMART_CORE
 SG_ RLMS_SEG_WARN : 37|1@1+ (1,0) [0|1] ""  SMART_CORE
 SG_ RLS_SEG_WARN : 36|1@1+ (1,0) [0|1] ""  SMART_CORE
 SG_ FRS_SEG_WARN : 35|1@1+ (1,0) [0|1] ""  SMART_CORE
 SG_ FLMS_SEG_WARN : 33|1@1+ (1,0) [0|1] ""  SMART_CORE
 SG_ RRS_SEGMENT : 28|4@1+ (1,0) [0|15] ""  SMART_CORE
 SG_ RLMS_SEGMENT : 20|4@1+ (1,0) [0|15] ""  SMART_CORE
 SG_ FLS_SEG_WARN : 32|1@1+ (1,0) [0|1] ""  SMART_CORE
 SG_ FRS_SEGMENT : 12|4@1+ (1,0) [0|15] ""  SMART_CORE
 SG_ APA_LED_FAULT : 56|3@1+ (1,0) [0|6] ""  SMART_CORE
 SG_ FRMS_SEG_WARN : 34|1@1+ (1,0) [0|1] ""  SMART_CORE
 SG_ RLS_SEGMENT : 16|4@1+ (1,0) [0|15] ""  SMART_CORE
 SG_ FLMS_SEGMENT : 4|4@1+ (1,0) [0|15] ""  SMART_CORE

BO_ 1653 GW1_1000: 8 Vector__XXX
 SG_ PRECNT_COMPLETION : 32|8@1+ (1,0) [0|100] "%"  SMART_CORE
 SG_ STS_CODE_FOTA : 0|8@1+ (1,0) [0|255] ""  SMART_CORE
 SG_ REQ_REPROG_FOTA : 25|1@1+ (1,0) [0|1] ""  SMART_CORE
 SG_ READY_UPDATE_DOWNLOAD_FOTA : 24|1@1+ (1,0) [0|1] ""  SMART_CORE
 SG_ METADATA_ID_FOTA : 8|8@1+ (1,0) [0|255] ""  SMART_CORE
 SG_ LAST_EXECUTED_STEP_FOTA : 16|8@1+ (1,0) [0|255] ""  SMART_CORE

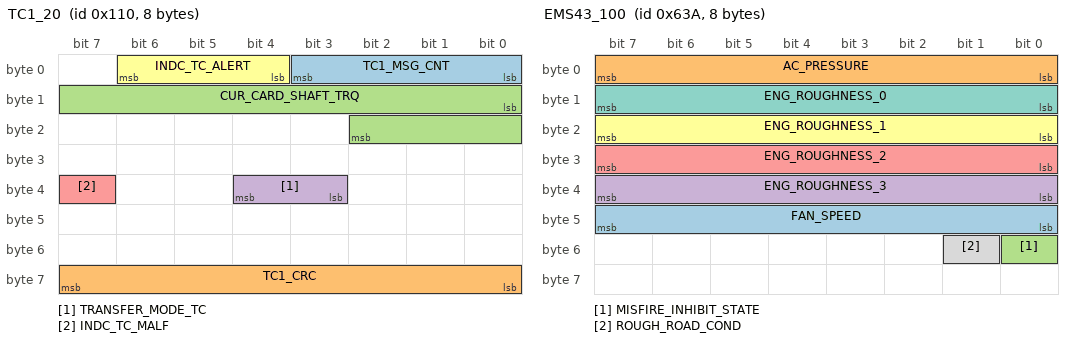
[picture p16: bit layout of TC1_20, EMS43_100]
BO_ 272 TC1_20: 8 Vector__XXX
 SG_ TC1_MSG_CNT : 0|4@1+ (1,0) [0|15] ""  SMART_CORE
 SG_ TC1_CRC : 56|8@1+ (1,0) [0|255] ""  SMART_CORE
 SG_ CUR_CARD_SHAFT_TRQ : 8|11@1+ (1,-1024) [-1024|1022] "Nm"  SMART_CORE
 SG_ TRANSFER_MODE_TC : 35|2@1+ (1,0) [0|3] ""  SMART_CORE
 SG_ INDC_TC_MALF : 39|1@1+ (1,0) [0|1] ""  SMART_CORE
 SG_ INDC_TC_ALERT : 4|3@1+ (1,0) [0|7] ""  SMART_CORE

BO_ 950 HLCU1_ACTIVE: 8 Vector__XXX
 SG_ RESERVED_2 : 0|64@1+ (1,0) [0|1.84467440737096E+019] ""  SMART_CORE

BO_ 962 ICC_SLEEP: 8 Vector__XXX
 SG_ RESERVED_2 : 0|64@1+ (1,0) [0|1.84467440737096E+019] ""  SMART_CORE

BO_ 158 ICC_WAKEUP: 8 Vector__XXX
 SG_ ICC_WAKEUP_REASON : 0|16@1+ (1,0) [0|65535] ""  SMART_CORE

BO_ 949 ICC_ACTIVE: 8 Vector__XXX
 SG_ RESERVED_2 : 0|64@1+ (1,0) [0|1.84467440737096E+019] ""  SMART_CORE

BO_ 2031 ICUA_DIAG_RES: 8 Vector__XXX
 SG_ DIAG_ICUA_RES_DATA : 0|64@1+ (1,0) [0|1.84467440737096E+019] ""  SMART_CORE

BO_ 1594 EMS43_100: 8 Vector__XXX
 SG_ FAN_SPEED : 40|8@1+ (0.5,0) [0|100] ""  SMART_CORE
 SG_ AC_PRESSURE : 0|8@1+ (16,0) [0|3100] ""  SMART_CORE
 SG_ MISFIRE_INHIBIT_STATE : 48|1@1+ (1,0) [0|1] ""  SMART_CORE
 SG_ ENG_ROUGHNESS_3 : 32|8@1+ (64,-12000) [-12000|4000] ""  SMART_CORE
 SG_ ENG_ROUGHNESS_2 : 24|8@1+ (64,-12000) [-12000|4000] ""  SMART_CORE
 SG_ ENG_ROUGHNESS_1 : 16|8@1+ (64,-12000) [-12000|4000] ""  SMART_CORE
 SG_ ENG_ROUGHNESS_0 : 8|8@1+ (64,-12000) [-12000|4000] ""  SMART_CORE
 SG_ ROUGH_ROAD_COND : 49|1@1+ (1,0) [0|1] ""  SMART_CORE

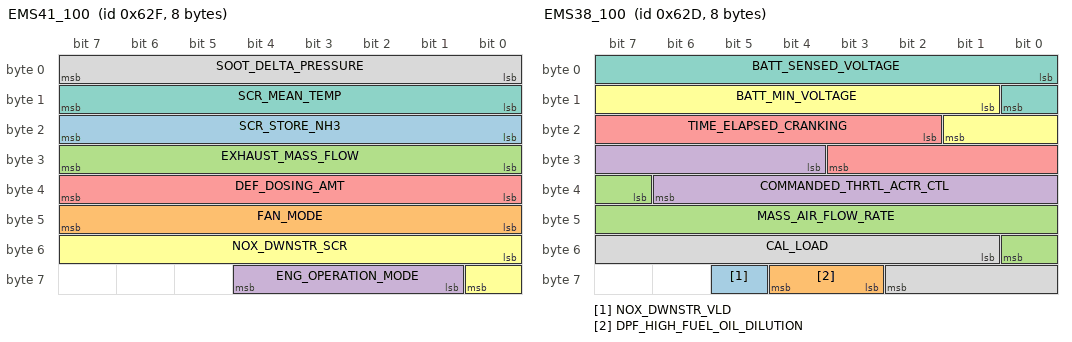
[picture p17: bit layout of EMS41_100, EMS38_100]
BO_ 1583 EMS41_100: 8 Vector__XXX
 SG_ SCR_STORE_NH3 : 16|8@1+ (0.05,0) [0|12] ""  SMART_CORE
 SG_ FAN_MODE : 40|8@1+ (0.5,0) [0|100] ""  SMART_CORE
 SG_ EXHAUST_MASS_FLOW : 24|8@1+ (4,-100) [-100|800] ""  SMART_CORE
 SG_ ENG_OPERATION_MODE : 57|4@1+ (1,0) [0|15] ""  SMART_CORE
 SG_ DEF_DOSING_AMT : 32|8@1+ (2,0) [0|300] ""  SMART_CORE
 SG_ NOX_DWNSTR_SCR : 48|9@1+ (2,0) [0|1000] ""  SMART_CORE
 SG_ SCR_MEAN_TEMP : 8|8@1+ (4,-100) [-100|800] ""  SMART_CORE
 SG_ SOOT_DELTA_PRESSURE : 0|8@1+ (0.25,0) [0|60] ""  SMART_CORE

BO_ 2025 TCU_DIAG_RES: 8 Vector__XXX
 SG_ DIAG_TCU_RES_DATA : 0|64@1+ (1,0) [0|1.8446744074E+019] ""  SMART_CORE

BO_ 1581 EMS38_100: 8 Vector__XXX
 SG_ NOX_DWNSTR_VLD : 61|1@1+ (1,0) [0|1] ""  SMART_CORE
 SG_ DPF_HIGH_FUEL_OIL_DILUTION : 59|2@1+ (1,0) [0|3] ""  SMART_CORE
 SG_ MASS_AIR_FLOW_RATE : 39|10@1+ (0.1,0) [0|100] ""  SMART_CORE
 SG_ COMMANDED_THRTL_ACTR_CTL : 28|11@1- (0.1,-50) [-50|100] ""  SMART_CORE
 SG_ TIME_ELAPSED_CRANKING : 18|10@1+ (10,0) [0|8000] "ms"  SMART_CORE
 SG_ BATT_MIN_VOLTAGE : 9|9@1+ (20,6000) [6000|16000] "mV"  SMART_CORE
 SG_ BATT_SENSED_VOLTAGE : 0|9@1+ (20,6000) [6000|16000] "mV"  SMART_CORE
 SG_ CAL_LOAD : 49|10@1+ (0.1,0) [0|100] "%"  SMART_CORE

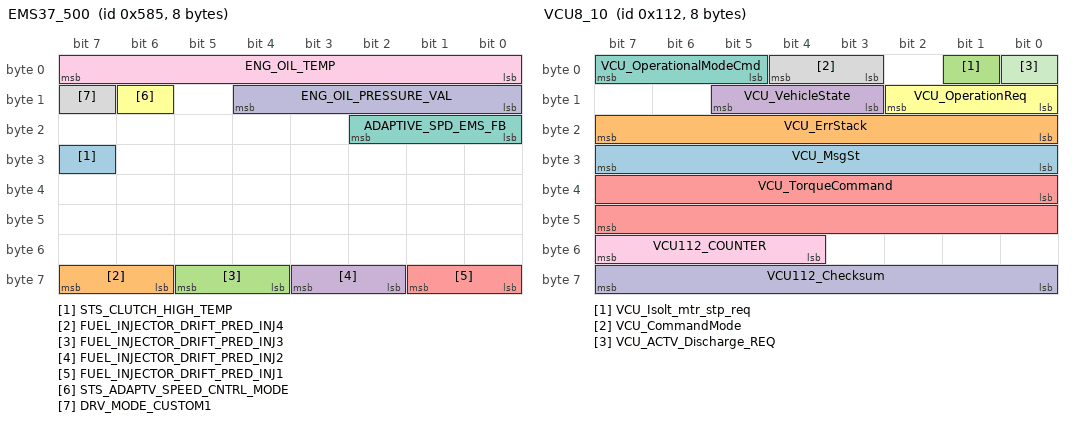
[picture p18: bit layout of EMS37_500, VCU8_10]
BO_ 1413 EMS37_500: 8 Vector__XXX
 SG_ STS_CLUTCH_HIGH_TEMP : 31|1@1+ (1,0) [0|1] ""  SMART_CORE
 SG_ FUEL_INJECTOR_DRIFT_PRED_INJ4 : 62|2@1+ (1,0) [0|0] ""  SMART_CORE
 SG_ FUEL_INJECTOR_DRIFT_PRED_INJ3 : 60|2@1+ (1,0) [0|0] ""  SMART_CORE
 SG_ FUEL_INJECTOR_DRIFT_PRED_INJ2 : 58|2@1+ (1,0) [0|0] ""  SMART_CORE
 SG_ FUEL_INJECTOR_DRIFT_PRED_INJ1 : 56|2@1+ (1,0) [0|0] ""  SMART_CORE
 SG_ STS_ADAPTV_SPEED_CNTRL_MODE : 14|1@1+ (1,0) [0|1] ""  SMART_CORE
 SG_ ADAPTIVE_SPD_EMS_FB : 16|3@1+ (1,0) [0|7] ""  SMART_CORE
 SG_ DRV_MODE_CUSTOM1 : 15|1@1+ (1,0) [0|1] ""  SMART_CORE
 SG_ ENG_OIL_TEMP : 0|8@1+ (1,-40) [-40|214] "deg C."  SMART_CORE
 SG_ ENG_OIL_PRESSURE_VAL : 8|5@1+ (1,0) [0|30] "Bar"  SMART_CORE

BO_ 259 EMS30_SP: 8 Vector__XXX
 SG_ IMMOVAL3 : 0|64@1+ (1,0) [0|1.8446744074] ""  SMART_CORE

BO_ 1864 FATC_DIAG_RES: 8 Vector__XXX
 SG_ DIAG_FATC_RES_DATA : 0|64@1+ (1,0) [0|1.8446744074E+019] ""  SMART_CORE

BO_ 1786 IC10_1000_TEST: 8 SMART_CORE
 SG_ RAWPITCH : 16|16@1- (0.01,0) [0|0] "" Vector__XXX
 SG_ RAWROLL : 0|16@1- (0.01,0) [0|0] "" Vector__XXX

BO_ 1787 IC11_1000_TEST: 8 SMART_CORE
 SG_ PITCHCOMP : 16|16@1- (0.01,0) [0|0] "" Vector__XXX
 SG_ ROLLCOMP : 0|16@1- (0.01,0) [0|0] "" Vector__XXX

BO_ 1784 IC8_1000_TEST: 6 SMART_CORE
 SG_ ROLLDEBOUNCE : 40|8@1+ (1,0) [0|0] "" Vector__XXX
 SG_ PITCHDEBOUNCE : 32|8@1+ (1,0) [0|0] "" Vector__XXX
 SG_ ROLLRATE : 16|16@1- (1,0) [0|0] "" Vector__XXX
 SG_ ACCEL : 0|16@1- (1,0) [0|0] "" Vector__XXX

BO_ 1785 IC9_1000_TEST: 8 SMART_CORE
 SG_ PITCH : 32|16@1- (0.01,0) [0|0] "" Vector__XXX
 SG_ ROLL : 0|16@1- (0.01,0) [0|0] "" Vector__XXX

BO_ 2023 ICUA_DIAG_REQ: 8 SMART_CORE
 SG_ DIAG_ICUA_REQ_DATA : 0|64@1+ (1,0) [0|1.84467440737096E+019] "" Vector__XXX

BO_ 1844 FDHM_DIAG_REQ: 8 SMART_CORE
 SG_ DIAG_FDHM_REQ_DATA : 0|64@1+ (1,0) [0|1.8446744074E+019] "" Vector__XXX

BO_ 1957 SVS_DIAG_REQ: 8 SMART_CORE
 SG_ DIAG_SVS_REQ_DATA : 0|64@1+ (1,0) [0|1.8446744074E+019] "" Vector__XXX

BO_ 581 OBC4_30: 8 Vector__XXX
 SG_ OBC_DCOutputVoltage : 48|14@1+ (0.1,0) [0|500] "V"  SMART_CORE
 SG_ OBC_DCOutputCurrent : 32|12@1+ (0.01,0) [0|30] "A"  SMART_CORE
 SG_ OBC_ACInputVoltageRMS : 16|12@1+ (0.1,0) [0|300] "Vrms"  SMART_CORE
 SG_ OBC_ACInputCurrentRMS : 0|14@1+ (0.01,0) [0|50] "Arms"  SMART_CORE

BO_ 274 VCU8_10: 8 Vector__XXX
 SG_ VCU_MsgSt : 24|8@1+ (1,0) [0|255] ""  SMART_CORE
 SG_ VCU_ErrStack : 16|8@1+ (1,0) [0|255] ""  SMART_CORE
 SG_ VCU_Isolt_mtr_stp_req : 1|1@1+ (1,0) [0|1] ""  SMART_CORE
 SG_ VCU_VehicleState : 11|3@1+ (1,0) [0|7] ""  SMART_CORE
 SG_ VCU_TorqueCommand : 32|16@1+ (0.0625,-2048) [-2045|2045] "Nm"  SMART_CORE
 SG_ VCU_OperationReq : 8|3@1+ (1,0) [0|7] "NA"  SMART_CORE
 SG_ VCU_OperationalModeCmd : 5|3@1+ (1,0) [0|7] "NA"  SMART_CORE
 SG_ VCU_CommandMode : 3|2@1+ (1,0) [0|3] "NA"  SMART_CORE
 SG_ VCU112_COUNTER : 52|4@1+ (1,0) [0|15] ""  SMART_CORE
 SG_ VCU112_Checksum : 56|8@1+ (1,0) [0|255] ""  SMART_CORE
 SG_ VCU_ACTV_Discharge_REQ : 0|1@1+ (1,0) [0|1] ""  SMART_CORE

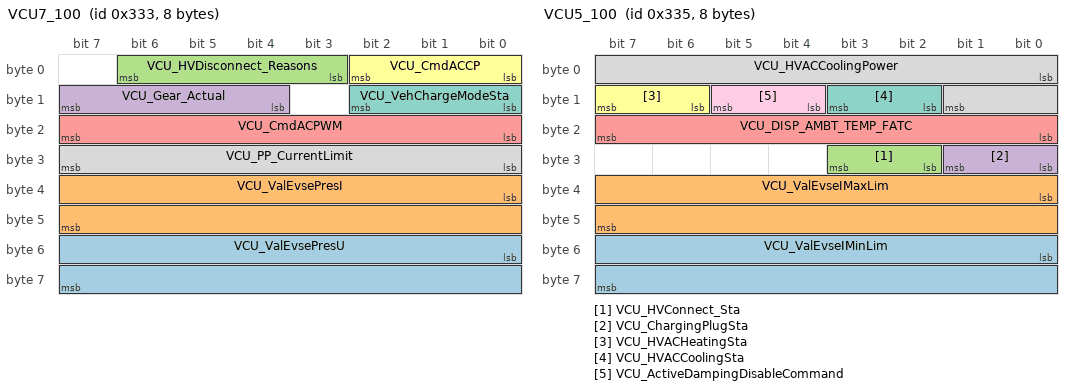
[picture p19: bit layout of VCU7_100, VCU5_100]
BO_ 819 VCU7_100: 8 Vector__XXX
 SG_ VCU_ValEvsePresU : 48|16@1+ (0.1,0) [0|1500] "V"  SMART_CORE
 SG_ VCU_ValEvsePresI : 32|16@1+ (0.1,0) [0|1000] "A"  SMART_CORE
 SG_ VCU_HVDisconnect_Reasons : 3|4@1- (1,0) [0|16] ""  SMART_CORE
 SG_ VCU_Gear_Actual : 12|4@1+ (1,0) [0|15] ""  SMART_CORE
 SG_ VCU_CmdACPWM : 16|8@1+ (1,0) [0|100] "%"  SMART_CORE
 SG_ VCU_CmdACCP : 0|3@1+ (1,0) [0|7] "NA"  SMART_CORE
 SG_ VCU_VehChargeModeSta : 8|3@1+ (1,0) [0|7] ""  SMART_CORE
 SG_ VCU_PP_CurrentLimit : 24|8@1+ (1,0) [0|80] "A"  SMART_CORE

BO_ 821 VCU5_100: 8 Vector__XXX
 SG_ VCU_ValEvseIMinLim : 48|16@1+ (0.1,0) [0|1000] "A"  SMART_CORE
 SG_ VCU_ValEvseIMaxLim : 32|16@1+ (0.1,0) [0|1000] "A"  SMART_CORE
 SG_ VCU_HVConnect_Sta : 26|2@1+ (1,0) [0|2] ""  SMART_CORE
 SG_ VCU_ChargingPlugSta : 24|2@1+ (1,0) [0|3] ""  SMART_CORE
 SG_ VCU_DISP_AMBT_TEMP_FATC : 16|8@1+ (1,-40) [-40|215] "deg C."  SMART_CORE
 SG_ VCU_HVACHeatingSta : 14|2@1+ (1,0) [0|3] ""  SMART_CORE
 SG_ VCU_HVACCoolingSta : 10|2@1+ (1,0) [0|3] ""  SMART_CORE
 SG_ VCU_HVACCoolingPower : 0|10@1+ (10,0) [0|8000] "W"  SMART_CORE
 SG_ VCU_ActiveDampingDisableCommand : 12|2@1+ (1,0) [0|3] ""  SMART_CORE

CM_ BO_ 3221225472 "This is a message for not used signals, created by Vector CANdb++ DBC OLE DB Provider.";
CM_ SG_ 3221225472 REMAINING_OIL_LIFE_PERCENT "The initial defult value is 100%";
CM_ SG_ 3221225472 BATT_OCV "Batterry open circuit voltage (OCV)";
CM_ SG_ 1506 IBS_Q_DISCHARGE "Total Discharging";
CM_ SG_ 1506 IBS_Q_CHARGE "Total Charging";
CM_ SG_ 1506 IBS_INT_RESISTANCE_ERR "Error Value of Internal Resistance";
CM_ SG_ 1506 IBS_INT_RESISTANCE "Internal Resistance";
CM_ SG_ 1041 I_BATT_QUIES_IBS "Quiescent Phase current";
CM_ SG_ 1041 T_BATT_IBS "Battery temp";
CM_ SG_ 1041 ALTER_MODE_IBS "Alternator mode";
CM_ SG_ 1041 ALTER_DUTYCYCLE_IBS "Alternative duty cycle";
CM_ SG_ 1041 IBS_ERROR "Flag to show if failure in the current, voltage or temperature measurement path is detected";
CM_ SG_ 1041 U_BATT_IBS "Battery voltage";
CM_ SG_ 1041 I_BATT_HIGH_IBS "Current value High- 16 bit data";
CM_ SG_ 1166 SOC_ERR_IBS "Error Value in SOC";
CM_ SG_ 1166 SOH_SUL_ERR_IBS "Error value in SOH_SUL";
CM_ SG_ 1166 ENG_COOLANT_FAN_IBS "Engine coolant fan";
CM_ SG_ 1166 GLOW_PLUG_IBS "Glow Plug Status";
CM_ SG_ 1166 VOLTAGE_PEAK_IBS "Voltage at I_Peak";
CM_ SG_ 1166 SOFV_STOP_ENABLE_IBS "SOFV_StopEnable considers a pre-discharge period preceding the engine cranking";
CM_ SG_ 1166 SOFV_RESTART_IBS "The SOFV_Restart is calculated without a pre-discharge period";
CM_ SG_ 1166 SOH_COR_IBS "State of health - degree of corrosion";
CM_ SG_ 1166 SOH_LAM_IBS "State of health - degree of LAM";
CM_ SG_ 1166 SOH_SUL_IBS "State of health - degree of sulphation";
CM_ SG_ 1166 SOC_IBS "State of charge";
CM_ SG_ 1443 IBS_FLG_START_LOCK_CNT "Flag for Starter Lock";
CM_ SG_ 1443 IBS_START_ACTVN_DLY "Starter Activation Delay";
CM_ SG_ 1443 FALSE_CRANK_TIMER_ELAPSE_IBS "Engine cranked but not started";
CM_ SG_ 1443 BATT_FLG_DISCONN_IBS "Battery disconnected";
CM_ SG_ 1443 LV_BATT_FIT_YEAR_IBS "Battery_Fit_Year_Current";
CM_ SG_ 1443 LV_BATT_FIT_MONTH_IBS "Battery_Fit_month_current";
CM_ SG_ 1443 LV_BATT_MANF_YEAR_IBS "Battery_Manf_year_current";
CM_ SG_ 1443 LV_BATT_MANF_MONTH_IBS "Batetry_Manf_month_current";
CM_ SG_ 1443 LV_BATT_CAPACITY_IBS "Battery capacity_current";
CM_ SG_ 1443 LV_BATT_SUPPLIER_IBS "Battery supplier name_current";
CM_ SG_ 1443 FALSE_CRANK_RPM_IBS "Engine cranked but not started";
CM_ SG_ 1443 IBS_WAKEUP_REASON "EBS wake up reason";
CM_ SG_ 1419 ALERT_CNG "After driving 950km in CNG mode EMS will automaticaly change to CNG for 33 sec.
S223:EMS should transmit signal (Alert CNG) to cluster after 15th forced CNG start onwards to alert as switch to petrol in cluster.Need to run in Petrol mode before 20 counts";
CM_ SG_ 1419 INSTANTANEOUS_FUEL_ECONOMY "Instantanoeusly fuel ecomocy";
CM_ SG_ 1419 CNG_MODE_RATIO "CNG mode ratio in percentage
(In Total Engine Working Time ,CNG mode ratio defines How much time that engine runs inCNG mode)";
CM_ SG_ 545 STS_EPS_STEERING_MODE "EPS steering Mode status";
CM_ SG_ 545 EPS_STEERING_MODE_ALERT "EPS steering Mode alert";
CM_ SG_ 545 EPS_STEERING_MODE "EPS steering Mode";
CM_ SG_ 545 EPS_DRV_ADV_MODE "Flex & Drive modes have same signal mapping (Feature code control)
Flex steer Tx Map:
0x0 - Mode 1 / Normal 
0x1 - Mode 2 / Sports
0x2 - Mode 3 / Comfort";
CM_ SG_ 545 EPS_FLEX_DISP "Flex Map Display";
CM_ SG_ 987 OBC_EVWARNING_TT "OBC EV Waning Telltale";
CM_ SG_ 987 OBC_ALERT_MESGS "OBC ALERT MESSAGES";
CM_ SG_ 818 MCU_EVWARNING_TT "MCU EV WARNING TELL TALE";
CM_ SG_ 818 MCU_ALERT_MSGS "MCU ALERT MESSAGES";
CM_ SG_ 992 LDC_EVWARNING_TT "LDC EV WARNING TELL TALE";
CM_ SG_ 992 LDC_ALERT_MSGS "LDC Alert Message Values";
CM_ SG_ 298 BMS_BattEnergyDisAcc_Drv "Battery Energy Discharge Accumulation kWh  during Driving
";
CM_ SG_ 298 BMS_BattEnergyAcc_Regen "Battery Energy Accumulation kWh during Regeneration
";
CM_ SG_ 298 BMS_BattEnergyAcc_NC "Battery Energy accumulation kWh in Normal Charge
";
CM_ SG_ 298 BMS_BattEnergyAcc_FC "Battery Energy accumulation kWh in Fast Charge
";
CM_ SG_ 1019 BMS_ServiceDueDetection "HV Battery Pack service detection due information";
CM_ SG_ 1019 BMS_BatteryContactorLife "Battery Contactor Life";
CM_ SG_ 445 ITA_ACTIVE "INTELLIGENT TURN ASSIST";
CM_ SG_ 445 CCO_WARNING "cRAWL cONTROL oPERATION";
CM_ SG_ 445 CCO_SET_SPD "cRAWL cONTROL oPERATION";
CM_ SG_ 445 CCO_ACTIVE "cRAWL cONTROL oPERATION";
CM_ SG_ 1276 REM_DATA_12_MSG_CNT "EMS21 message counter";
CM_ SG_ 1007 VCU_TorqueCoasting "Coast regen torque information";
CM_ SG_ 1007 VCU_SwitchS2 "S2 Switch status";
CM_ SG_ 1007 VCU_StCreep "Creep Activation flag status";
CM_ SG_ 1007 VCU_StCoasting "Coasting activation flag status";
CM_ SG_ 1007 VCU_HVAccPowerConsumption "Power consumption by HV accessories(mcu,ldc ,hvac,battery heater)";
CM_ SG_ 1007 VCU_EConsPerKm "Total energy consumption per km";
CM_ BO_ 823 "VCU Critical Signals 01";
CM_ SG_ 823 VCU_StsCodEvse "EVSE Status Code";
CM_ SG_ 823 VCU_MaxDischargeCurrent "Maximum DC current allowed for discharging the high power battery.
";
CM_ SG_ 823 VCU_MaxChargeCurrent "Maximum DC current allowed for charging the high power battery.";
CM_ SG_ 823 VCU_CmdTargetVoltLDC "Low Votage(12V) Output LDC Target voltage";
CM_ SG_ 823 VCU337_COUNTER "Message Counter";
CM_ SG_ 823 VCU337_CRC "CRC, CHECKSUM ERROR as per SAEJ1850";
CM_ SG_ 823 VCU_CmdEnableLDC "VCU sends Enable command to LDC";
CM_ SG_ 823 VCU_MainContactorControl "Main Contactor Control Request";
CM_ SG_ 443 VCU_ExMeDi_ErrStsEmpowdNoneCrit "Emergency PowerDown None Critical Error Status";
CM_ SG_ 443 VCU_ExMeDi_ErrStsEmpowdCrit "Emergency PowerDown Critical Error Status";
CM_ SG_ 443 VCU_TrigMsgTxCyclc "Trigger Message Cyclic Transmit";
CM_ SG_ 443 VCU_MsgRxCyclc "Cyclic Message received";
CM_ SG_ 443 VCU_StsVehRdy "Status of EV ready to charge";
CM_ SG_ 443 VCU_StsComAsscn "SLAC_Association step indication";
CM_ SG_ 443 VCU_ErrEveh "EV Error Indicator";
CM_ SG_ 443 VCU_USetPointChrgn "EV Target Voltage Value";
CM_ SG_ 443 VCU_StMacSts "State Machine Status";
CM_ SG_ 443 VCU_ISetPointChrgn "EV Target Current Value";
CM_ SG_ 628 LDC_HVIL_Interlock4 "LDC HVIL interlock status for AC input connector";
CM_ SG_ 628 LDC_ACTV_Discharge_STS "HV Active Discharging Status";
CM_ SG_ 628 LDC_OperationMode "LDC Operation modes
";
CM_ SG_ 628 LDC_FCVoltageValue "LDC Fast Charge voltage
";
CM_ SG_ 628 LDC274_COUNTER "Message Counter";
CM_ SG_ 628 LDC274_CRC "CRC, CHECKSUM ERROR as per SAEJ1850";
CM_ SG_ 628 LDC_HVIL_Interlock3 "LDC HVIL interlock status for Battery Heater, Cabin Heater & Compressor";
CM_ SG_ 628 LDC_HVIL_Interlock2 "LDC HVIL interlock status for MCU, Battery connectors";
CM_ SG_ 628 LDC_HVIL_Interlock1 "LDC HVIL interlock status for FC connector";
CM_ SG_ 991 LDC_OPV_Circuit_Error "LDC_output voltage_Circuit_Error";
CM_ SG_ 991 LDC_Low_Temp_Shutdown "LDC_Low_Temp_Shutdown";
CM_ SG_ 991 LDC_IPV_Circuit_Error "LDC_input voltage_Circuit_Error";
CM_ SG_ 991 LDC_INTERNAL_FAIL "LDC_INTERNAL_FAIL";
CM_ SG_ 991 LDC_Input_Over_Current "LDC_Input_Over_Current";
CM_ SG_ 991 LDC_Heat_Sink_Over_Temp_Shutdown "Heat Sink Over Temp Shutdown";
CM_ SG_ 991 LDC_Vprog_Out_of_Range "Vprog out of range
";
CM_ SG_ 991 LDC_Watchdog_Failure "Watchdog Failure";
CM_ SG_ 991 LDC_VCU_Node_Absent "Node Absent";
CM_ SG_ 991 LDC_Temp_Sensing_Failure "LDC Temperature Sensing Failure";
CM_ SG_ 991 LDC_IPC_COMM_ERR_OBC "IPC Communication Error OBC";
CM_ SG_ 991 LDC_EEPROM_Failure "EEPROM Failure";
CM_ SG_ 991 LDC_Short_Circuit "Short Circuit";
CM_ SG_ 991 LDC_Output_Under_Voltage "Output Under Voltage";
CM_ SG_ 991 LDC_Output_Over_Voltage "Output Over Voltage";
CM_ SG_ 991 LDC_Output_Over_Current "Output Over Current";
CM_ SG_ 991 LDC_LPS_Under_Voltage "LPS Under Voltage";
CM_ SG_ 991 LDC_LPS_Over_Voltage "LPS Over Voltage";
CM_ SG_ 991 LDC_Input_Under_Voltage "Input Voltage Under Voltage";
CM_ SG_ 991 LDC_Input_Over_Voltage "Input Over Voltage";
CM_ SG_ 991 LDC_Heat_Sink_Over_Temp_Wng_2 "Heat Sink Over Temp Warning 2";
CM_ SG_ 991 LDC_Heat_Sink_Over_Temp_Wng_1 "Heat Sink Over Temp Warning 1";
CM_ SG_ 991 LDC_Heat_Sink_Over_Temp_Wng_0 "Heat Sink Over Temp Warning 0";
CM_ SG_ 991 LDC_Amb_Over_Temp_Wng "Ambient over temp Warning";
CM_ SG_ 991 LDC_Amb_Over_Temp_Shutdown "Ambient over temp Shutdown";
CM_ BO_ 580 "LDC Normal Signals 02";
CM_ SG_ 580 LDC_OutputVoltageValue "LDC output voltage";
CM_ SG_ 580 LDC_OutputCurrent "LDC output current
";
CM_ SG_ 580 LDC_InputVoltageValue "LDC input voltage
";
CM_ SG_ 580 LDC_InputCurrentValue "LDC input current";
CM_ BO_ 989 "LDC Normal Signals 01";
CM_ SG_ 989 LDC_Primary_Temperature "LDC temperature- Primary DC-DC Temperature";
CM_ SG_ 989 LDC_CoolingRequest "LDC_Cooling Request signal";
CM_ SG_ 989 LDC_MOSFET_Temperature "LDC temperature- MOSFET DC-DC Temperature";
CM_ SG_ 989 LDC_Secondary_Temperature "LDC temperature -Secondary DC-DC  temperature";
CM_ SG_ 989 LDC_ProtectionMode "LDC Protection Mode ";
CM_ BO_ 825 "BMS Normal Signals 04";
CM_ SG_ 825 BMS_BatteryMinTemperature "Battery Min temperature";
CM_ SG_ 825 BMS_BatteryMaxTemperature "Battery Max temperature";
CM_ SG_ 825 BMS_Actual_Batt_Heater_Pwr "Actual power consumed by Battery heater ";
CM_ SG_ 825 BMS_Req_Batt_Heater_Pwr "Battery Heater Power requested by BMS";
CM_ SG_ 825 BMS_ChargingStop "BMS request Charging stop";
CM_ SG_ 825 BMS_BCoolingRequest "setting the cooling request to On or OFF completely";
CM_ BO_ 979 "BMS Normal Signals 07";
CM_ SG_ 979 BMS_Discharge_Cycle "Charge Cycle Calculation";
CM_ SG_ 979 BMS_Charge_Cycle "Charge Cycle Calculation";
CM_ SG_ 979 BMS_ChargePowerAvailable_2 "Battery available charge power in the next 2s(SOP)";
CM_ SG_ 979 BMS_ChargePowerAvailable_10 "Battery available charge power in the next 10s(SOP)";
CM_ BO_ 1005 "BMS Normal Signals 08";
CM_ SG_ 1005 BMS_BattBalancingCompSta "Indicates whether Balancing is Completed or not completed";
CM_ SG_ 1005 BMS_BatteryBalancingSta "Indicates whether Balancing is active or not";
CM_ SG_ 1005 BMS_BCoolPumpFBSta "Battery coolant pump feedback  (Like Dry run ..etc)";
CM_ SG_ 1005 BMS_BatteryLowSOC "HV Battery Low battery SOC warning message";
CM_ SG_ 1005 BMS_BatteryAvgTemperature "Battery Average Termperature";
CM_ SG_ 1005 BMS_STS_IGN "BMS IGN KL 15 detect information";
CM_ SG_ 1005 BMS_CellVoltHighWarnDegdFault "HV Battery cell high voltage warning / fault information";
CM_ SG_ 1005 BMS_BPlusContactorWeld "HV Battery Postive contactor weld status";
CM_ SG_ 1005 BMS_BMinusContactorWeld "HV Battery Negative contactor weld status";
CM_ BO_ 301 "BMS Critical Signals 01";
CM_ SG_ 301 BMS_ACTV_Discharge_STS "HV Active Discharging Status";
CM_ SG_ 301 BMS273_COUNTER "Message Counter";
CM_ SG_ 301 BMS273_CRC "CRC, CHECKSUM ERROR as per SAEJ1850";
CM_ SG_ 301 BMS_BatteryBusVoltage "HV Battery Bus voltage (After contactor)";
CM_ SG_ 301 BMS_BatteryPackStatus "Battery Pack Status";
CM_ SG_ 301 BMS_BatteryPackCurrent "Battery Pack Current ";
CM_ SG_ 301 BMS_OperationMode "BMS Operation Modes
(BMS Internal Status)";
CM_ SG_ 1003 BMS_CellTemp9 "Battery Cell temperature 9";
CM_ SG_ 1003 BMS_CellTemp8 "Battery Cell temperature 8";
CM_ SG_ 1003 BMS_CellTemp7 "Battery Cell temperature 7";
CM_ SG_ 1003 BMS_CellTemp6 "Battery Cell temperature 6";
CM_ SG_ 1003 BMS_CellTemp5 "Battery Cell temperature 5";
CM_ SG_ 1003 BMS_CellTemp4 "Battery Cell temperature 4";
CM_ SG_ 1003 BMS_CellTemp32 "Battery Cell temperature 32";
CM_ SG_ 1003 BMS_CellTemp31 "Battery Cell temperature 31";
CM_ SG_ 1003 BMS_CellTemp30 "Battery Cell temperature 30";
CM_ SG_ 1003 BMS_CellTemp29 "Battery Cell temperature 29";
CM_ SG_ 1003 BMS_CellTemp28 "Battery Cell temperature 28";
CM_ SG_ 1003 BMS_CellTemp27 "Battery Cell temperature 27";
CM_ SG_ 1003 BMS_CellTemp26 "Battery Cell temperature 26";
CM_ SG_ 1003 BMS_CellTemp25 "Battery Cell temperature 25";
CM_ SG_ 1003 BMS_CellTemp24 "Battery Cell temperature 24";
CM_ SG_ 1003 BMS_CellTemp23 "Battery Cell temperature 23";
CM_ SG_ 1003 BMS_CellTemp22 "Battery Cell temperature 22";
CM_ SG_ 1003 BMS_CellTemp21 "Battery Cell temperature 21";
CM_ SG_ 1003 BMS_CellTemp20 "Battery Cell temperature 20";
CM_ SG_ 1003 BMS_CellTemp19 "Battery Cell temperature 19";
CM_ SG_ 1003 BMS_CellTemp18 "Battery Cell temperature 18";
CM_ SG_ 1003 BMS_CellTemp17 "Battery Cell temperature 17";
CM_ SG_ 1003 BMS_CellTemp16 "Battery Cell temperature 16";
CM_ SG_ 1003 BMS_CellTemp15 "Battery Cell temperature 15";
CM_ SG_ 1003 BMS_CellTemp14 "Battery Cell temperature 14";
CM_ SG_ 1003 BMS_CellTemp13 "Battery Cell temperature 13";
CM_ SG_ 1003 BMS_CellTemp12 "Battery Cell temperature 12";
CM_ SG_ 1003 BMS_CellTemp11 "Battery Cell temperature 11";
CM_ SG_ 1003 BMS_CellTemp10 "Battery Cell temperature 10";
CM_ SG_ 1003 BMS_CellTemp3 "Battery Cell temperature 3";
CM_ SG_ 1003 BMS_CellTemp2 "Battery Cell temperature 2";
CM_ SG_ 1003 BMS_CellTemp1 "Battery Cell temperature 1";
CM_ SG_ 1003 BMS_CellTemp_Index "BMS Cell Temp Index signal";
CM_ BO_ 981 "BMS Normal Signals 12";
CM_ SG_ 981 BMS3D5_CRC "CRC, CHECKSUM ERROR as per SAEJ1850";
CM_ SG_ 981 BMS3D5_COUNTER "Message Counter";
CM_ SG_ 981 BMS_BatteryInstantEnergyCons "Battery Instant Energy consumption";
CM_ SG_ 981 BMS_AveEnergyCons "BMS Average Energy consumption - Indication purpose";
CM_ SG_ 981 BMS_ALERT_MSGS "BMS Alert Message Values";
CM_ SG_ 981 BMS_STS_CHARGE_LIGHT_TT "Charge Light Status";
CM_ SG_ 981 BMS_SERVICE_LIGHT_TT "BMS SERVICE LIGHT TEL TALE";
CM_ SG_ 981 BMS_HV_BATT_TT "BMS HV Battery Failure TellTale";
CM_ SG_ 981 BMS_HIGH_TEMP_LIGHT_OP_TT "BMS HIGH TEMPERATURE LIGHT OUTPUT TEL TALE";
CM_ SG_ 981 BMS_EVWARNING_TT "BMS EV WARNING TELL TALE";
CM_ SG_ 1585 ICC_ALERT_MSG "Alert message from ICC to cluster";
CM_ SG_ 2019 DIAG_TC_REQ_DATA "TPMS Diagnostics Request";
CM_ BO_ 870 "MCM to PKE Authentication message";
CM_ SG_ 870 PKE_CHALLENGE_STS_MCM "PKE Challenge Recieve status";
CM_ SG_ 1280 IC11_MSG_CNT "EMS21 message counter";
CM_ SG_ 1280 IC11_CRC "EMS21 message checksum";
CM_ SG_ 1280 MODE_SELECTION_SWT "Mode selection switch used for different mode selection like grass, snow, mud& rut etc.";
CM_ SG_ 1280 IC_STEERING_MODE_REQ "EPS sterring mode request from Cluster";
CM_ SG_ 154 MCM_WAKEUP_REASON "Reason for wake-up.";
CM_ SG_ 1587 MCM1_CRC "CRC implementation for the Message";
CM_ SG_ 1587 REQ_HEADLAMP_MCM "Turn ON/OFF headlamp request from MCM.";
CM_ BO_ 1144 "MBFM1_100";
CM_ SG_ 1144 PSGR_REAR_SEAT_BELT_SBRM "BIT 0:- Rear Left Passenger
BIT 1:- Rear Middle Passenger
BIT 2:- Rear Right Passenger
BIT 3:- Rear 3rd RowLeft Passenger
BIT 4:- Rear 3rd Row Middle Passenger
BIT 5:- Rear 3rd Row Right Passenger

0x0:-Not Buckled/DV
0x1:-Buckled";
CM_ SG_ 563 DIST_DEF_EMPTY "Distance till the DEF level is empty.";
CM_ SG_ 563 INDC_REGEN "0x00= telltale OFF/No manual regenaration needed/regen completed/Default value
0x01=telltale ON/Manual regenaration needed/regen not completed(requested by IC)
0x02=telltale blink/Manual regenaration in progress/regen request accepted(requested by IC)";
CM_ SG_ 563 STS_DEF "Urea status

Bit 0: Incorrect DEF
Bit 1: DEF level low
Bit2: DEF dosing malfunction

0 - Error inactive       1 - Error active";
CM_ SG_ 295 ACC_PED_ACTUAL "raw value of acc pedal.";
CM_ SG_ 295 ENG_LOSSES "Engine losses";
CM_ SG_ 295 EMS21_MSG_CNT "EMS21 message counter";
CM_ SG_ 295 EMS21_CRC "EMS21 message checksum";
CM_ SG_ 295 BRK_PEDAL1 "Break Pedal Signal";
CM_ SG_ 375 TGS_LEVER_AMT "Transmission Gear Select lever position.
";
CM_ SG_ 304 ACC_READY "Adaptive Cruise Control (ACC) function available status";
CM_ SG_ 304 EMS_DRIVE_ALERT "EMS DRIVE MODE:-DRIVE mode status indication to IC in case of failure.";
CM_ SG_ 304 STS_EMS_DRV_ADV_MODE "Feedback indication to ESC for Terrain or Adventure response mode.";
CM_ SG_ 1638 ASD_TORQUE "Adventure statistics torque display in percentage";
CM_ SG_ 1638 ASD_POWER "Adventure statistics power display in percentage";
CM_ SG_ 1079 IDLING_DURATION "Unwanted Idling duration";
CM_ SG_ 1078 AVG_SPD "Average Speed";
CM_ SG_ 1078 TOP_SPD "Top Speed";
CM_ SG_ 1078 TRIP_DIST "Trip Distance";
CM_ SG_ 1078 TRIP_DURATION_HOUR "Trip Duration";
CM_ SG_ 1077 IDLING_INDEX "Unwanted Idling Index";
CM_ SG_ 1077 GEAR_MISMATCH "Gear RPM Mismatch Index";
CM_ SG_ 1077 OVR_SPD "Overspeed Index indication to infotainment";
CM_ SG_ 1077 CLTH_OVRRIDE "Clutch Override Index indication to infotainment";
CM_ SG_ 1077 AGG_BRK "Aggressive Braking Index indication to infotainment";
CM_ SG_ 1077 AGG_ACC "Aggressive Acceleration Index to infotainment";
CM_ SG_ 1077 STS_TRIP "Trip Status to infotaiment";
CM_ SG_ 1077 COMM_ERR_FLG "Communication Error Flag indication to infotainment";
CM_ SG_ 1077 TPMS_FLG "TPMS Indication Request to Infotainment";
CM_ SG_ 1077 AC_USAGE_REG_FLG "AC Usage Indication Request to infotainment
";
CM_ SG_ 1077 IDLING_FLG "Idling Indication Request to infotainment
";
CM_ SG_ 1077 OVRSPD_FLG "Overspeed Indication Request to infotainment";
CM_ SG_ 1077 CLUTCH_OVRRIDE_FLG "Clutch Override Indication Request to Infotainment";
CM_ SG_ 752 SVS_SWT "Only for projects where SVS Switch is hardwired to SMARTCORE / IS ";
CM_ SG_ 752 STS_AUTO_ZOOM_IN_VIEW "AUTO ZOOM IN VIEW
- If this feature is enabled in IS then only camera will switch to auto zoom  
";
CM_ SG_ 752 STS_AUTO_CORNER_VIEW "AUTO CORNER VIEW
- If this feature is enabled in IS then only auto cornered view is available, depending on status of cornering lamp";
CM_ SG_ 752 DEFAULT_VIEW_FRONT "Default view for Front View Camera";
CM_ SG_ 752 DEFAULT_VIEW_REAR "Default view for Rear View Camera";
CM_ SG_ 1584 NOX_UPSTR_MDL "NOx upstream SCR modelled";
CM_ SG_ 1595 KNOCK_SIGNALS_0 "Knock signals
";
CM_ SG_ 1595 KNOCK_SIGNALS_1 "Knock signals
";
CM_ SG_ 1595 KNOCK_SIGNALS_2 "Knock signals
";
CM_ SG_ 1595 KNOCK_SIGNALS_3 "Knock signals
";
CM_ SG_ 1595 MASS_AIR_FLOW "Air mass flow ";
CM_ SG_ 1595 MISFIRE_DETECT_THRESHOLD "Threshold for misfire detection";
CM_ SG_ 1595 MISFIRE_SUM_A "Sum of misfire counters a 
";
CM_ SG_ 1595 MISFIRE_SUM_B "Sum of misfire counters B
 
";
CM_ SG_ 1596 MISFIRE_CTR_A_0 "Misfire counter a per cylinder ";
CM_ SG_ 1596 MISFIRE_CTR_A_1 "Misfire counter a per cylinder ";
CM_ SG_ 1596 MISFIRE_CTR_A_2 "Misfire counter a per cylinder ";
CM_ SG_ 1596 MISFIRE_CTR_A_3 "Misfire counter a per cylinder ";
CM_ SG_ 1596 MISFIRE_CTR_B_0 "Misfire counter B per cylinder ";
CM_ SG_ 1596 MISFIRE_CTR_B_1 "Misfire counter B per cylinder ";
CM_ SG_ 1596 MISFIRE_CTR_B_2 "Misfire counter B per cylinder ";
CM_ SG_ 1596 MISFIRE_CTR_B_3 "Misfire counter B per cylinder ";
CM_ SG_ 1428 BRAKE_PREDICTION_STS "Prognosis - Brake System Prediction";
CM_ SG_ 1582 COMMANDED_EGR "Commanded EGR";
CM_ SG_ 1582 EGR_ERR "EGR_Error";
CM_ SG_ 1582 MEUNT_SETPOINT_RAIL_PRESSURE "Setpoint value (volume flow) of rail pressure";
CM_ SG_ 1582 MEUNT_SETPOINT_ADPT_CORECT "Adaptive correction of metering unit set point value";
CM_ SG_ 1582 MEUNT_CTCL_FLTACT_CURVAL "Metering unit current control filtered actual current value";
CM_ SG_ 1582 FUEL_RAIL_PRESSURE "Fuel Rail pressure";
CM_ BO_ 1967 "Diagnostics response message from FVC";
CM_ SG_ 767 JOYSTICK_DB_STS "JOYSTICK DOWNWARD MOVEMENT";
CM_ SG_ 767 JOYSTICK_UB_STS "JOYSTICK UPWARD MOVEMENT";
CM_ SG_ 767 JOYSTICK_RB_STS "JOYSTICK RIGHT MOVEMENT";
CM_ SG_ 767 JOYSTICK_LB_STS "JOYSTICK LEFT MOVEMENT";
CM_ BO_ 1966 "Diagnostics response message from SCM";
CM_ SG_ 930 SLOT_LENGTH_WIDTH "Slot Length for parallel parking or Slot width for perpendicular parking.";
CM_ SG_ 930 SLOT_DEPTH "Slot Depth .";
CM_ SG_ 930 DIST_TO_SLOT "Distance to Slot  .";
CM_ SG_ 930 DIST_TO_SAFE_PT "Distance to Safe Point .";
CM_ SG_ 930 APA_PROGRESS_PERCNTG "The progress bar display percentage in  a single moving step .";
CM_ SG_ 930 APA_PARK_MODE "Parking mode selected .";
CM_ SG_ 930 APA_PARK_DIRCTION "Parking direction .";
CM_ SG_ 930 APA_DISP_SUB_PIC "Display HMI Sub picture .";
CM_ SG_ 930 APA_DISP_MAIN_PIC "Display HMI main picture .";
CM_ SG_ 930 APA_DISP "HMI Active request";
CM_ SG_ 930 APA_ACTIVE "APA Work Status.";
CM_ SG_ 930 FPAS_SW_STS " PAS Work Status ";
CM_ SG_ 930 MAMS_SWT_STS " CMBS Work Status .";
CM_ SG_ 929 FLS_SEGMENT "Front Left Side display segment .";
CM_ SG_ 929 LEFT_MIN_DIST "Minimum obstacle distance detected by FPAS sensors .";
CM_ SG_ 929 RRMS_SEGMENT "Rear Right Middle Side Sensor Display Segment .";
CM_ SG_ 929 APA_SWITCH_FAULT " APA system Switch  fault information .

bit0: APA
bit1: PAS
bit2:CMBS

0x0 - OK / Default
0x1 - Not OK";
CM_ SG_ 929 FRMS_SEGMENT "Front Right Middle Side Sensor Display Segment.";
CM_ SG_ 929 RIGHT_MIN_DIST "Minimum obstacle distance detected by FPAS sensors .";
CM_ SG_ 929 RRS_SEG_WARN "Rear Right Side Sensor Warning status.";
CM_ SG_ 929 RRMS_SEG_WARN "Rear Right Middle Side Sensor Warning status.";
CM_ SG_ 929 RLMS_SEG_WARN "Rear Left Middle Side Sensor Warning status.";
CM_ SG_ 929 RLS_SEG_WARN "Rear Left Side Sensor Warning status.";
CM_ SG_ 929 FRS_SEG_WARN "Front Right Side Sensor Warning status.";
CM_ SG_ 929 FLMS_SEG_WARN "Front Left Middle Side Sensor Warning status.";
CM_ SG_ 929 RRS_SEGMENT "Rear Right Side Sensor Display Segment .";
CM_ SG_ 929 RLMS_SEGMENT "Rear Left Middle Side Sensor Display Segment.";
CM_ SG_ 929 FLS_SEG_WARN "Front Left Side Sensor Warning status.";
CM_ SG_ 929 FRS_SEGMENT "Front Right Side Sensor Display Segment .";
CM_ SG_ 929 APA_LED_FAULT " APA system LED  fault information .

bit0: APA
bit1: PAS
bit2:CMBS

0x0 - OK / Default
0x1 - Not OK";
CM_ SG_ 929 FRMS_SEG_WARN "Front Right Middle Side Sensor Warning status.";
CM_ SG_ 929 RLS_SEGMENT "Rear Left Side Sensor Display Segment.";
CM_ SG_ 929 FLMS_SEGMENT "Front Left Middle Side Sensor Display Segment .";
CM_ SG_ 1653 METADATA_ID_FOTA "Default -0
";
CM_ SG_ 1653 LAST_EXECUTED_STEP_FOTA "0 default
";
CM_ SG_ 272 CUR_CARD_SHAFT_TRQ "4WD current cardan shaft torque";
CM_ SG_ 272 TRANSFER_MODE_TC "4WD mode";
CM_ SG_ 272 INDC_TC_MALF "Indicates malfunctin of TC to IC";
CM_ SG_ 272 INDC_TC_ALERT "1.2WD to 4WH.The alert to IC - reduce veh spd below 80 kmph.
2.2WD to 4WL or 4WH to 4WL.The alert to IC- MT vehicle(Stop&Shift transmission into N)
3.2WD to 4WL or 4WH to 4WL.The alert to IC - AT vehicle(Stop&Shift transmission intoP or N).
";
CM_ SG_ 158 ICC_WAKEUP_REASON "Reason for wake-up.

0X0 - Any Button Press ( Button 1,2,3,4 & Centre button)
0X1 - Any Joystick Button Press( Joystick DB,LB,RB & UB)";
CM_ SG_ 1594 FAN_SPEED "Fan speed";
CM_ SG_ 1594 AC_PRESSURE "AIr conditioning pressure";
CM_ SG_ 1594 MISFIRE_INHIBIT_STATE "Inhibition state for misfire detection ";
CM_ SG_ 1594 ENG_ROUGHNESS_3 "Engine roughness";
CM_ SG_ 1594 ENG_ROUGHNESS_2 "Engine roughness";
CM_ SG_ 1594 ENG_ROUGHNESS_1 "Engine roughness";
CM_ SG_ 1594 ENG_ROUGHNESS_0 "Engine roughness";
CM_ SG_ 1594 ROUGH_ROAD_COND "State of rough road condition";
CM_ SG_ 1583 SCR_STORE_NH3 "Level of NH3 stored in the SCR catalyst";
CM_ SG_ 1583 FAN_MODE "fan mode";
CM_ SG_ 1583 EXHAUST_MASS_FLOW "Exhaust mass flow 2 ";
CM_ SG_ 1583 ENG_OPERATION_MODE "Engine operation Mode State";
CM_ SG_ 1583 DEF_DOSING_AMT "DEF dosing amount";
CM_ SG_ 1583 NOX_DWNSTR_SCR "NOx downstream SCR";
CM_ SG_ 1583 SCR_MEAN_TEMP "SCR mean temperature";
CM_ SG_ 1583 SOOT_DELTA_PRESSURE "Soot Load Delta pressure model";
CM_ SG_ 1581 MASS_AIR_FLOW_RATE "Air flow rate from mass air flow sensor";
CM_ SG_ 1581 COMMANDED_THRTL_ACTR_CTL "Commanded throttle actuator control";
CM_ SG_ 1581 CAL_LOAD " ratio of driver demand torque to the engine effective torque available at crank shaft";
CM_ SG_ 1413 STS_CLUTCH_HIGH_TEMP "Clutch Press State ";
CM_ SG_ 1413 ENG_OIL_TEMP "Engine Oil Temperature";
CM_ SG_ 1413 ENG_OIL_PRESSURE_VAL "Engine Oil Pressure";
CM_ BO_ 581 "OBC Normal Signals 03";
CM_ SG_ 581 OBC_DCOutputVoltage "Output Voltage
";
CM_ SG_ 581 OBC_DCOutputCurrent "Output Current
";
CM_ SG_ 581 OBC_ACInputVoltageRMS "AC Input Source Voltage (rms)";
CM_ SG_ 581 OBC_ACInputCurrentRMS "AC Input Source Current (rms)";
CM_ SG_ 274 VCU_MsgSt "Message State";
CM_ SG_ 274 VCU_ErrStack "Stack Error";
CM_ SG_ 274 VCU_Isolt_mtr_stp_req "Insulation Monitoring Stop request -- 
During DC Charging EVSE will activate the Isolation monitoring
-> If both EVSE and BMS start monitoring simultaneously, Isolation resistance value will not be proper.";
CM_ SG_ 274 VCU_VehicleState "Vehicle State";
CM_ SG_ 274 VCU_TorqueCommand "TorqueCommand ? (CommandMode = TorqueMode)  Electric motorization torque desired at the motor output shaft (at the input of the gearbox).";
CM_ SG_ 274 VCU_OperationReq "VCU Operation Request";
CM_ SG_ 274 VCU_OperationalModeCmd "Operation command to MCU";
CM_ SG_ 274 VCU_CommandMode "Mode request by VCU";
CM_ SG_ 274 VCU112_COUNTER "Message Counter
";
CM_ SG_ 274 VCU112_Checksum "Checksum";
CM_ SG_ 274 VCU_ACTV_Discharge_REQ "HV Active Discharging request
";
CM_ BO_ 819 "VCU Normal Signals 04";
CM_ SG_ 819 VCU_ValEvsePresU "EVSE Present Voltage Value from Station";
CM_ SG_ 819 VCU_ValEvsePresI "EVSE Present Current Value from Station";
CM_ SG_ 819 VCU_HVDisconnect_Reasons "Reasons for HV Disconnect";
CM_ SG_ 819 VCU_Gear_Actual "Drive Mode - Coming from VCAN";
CM_ SG_ 819 VCU_CmdACPWM "AC PWM(Duty)";
CM_ SG_ 819 VCU_CmdACCP "AC CP Voltage Status";
CM_ SG_ 819 VCU_VehChargeModeSta "Vehicle Charging Mode Status";
CM_ SG_ 819 VCU_PP_CurrentLimit "AC Charger capacity";
CM_ BO_ 821 "VCU Normal Signals 02";
CM_ SG_ 821 VCU_ValEvseIMinLim "EVSE Minimum Current value from EVSE Station";
CM_ SG_ 821 VCU_ValEvseIMaxLim "EVSE Maximum Current limit value from Station";
CM_ SG_ 821 VCU_HVConnect_Sta "Once HV connect is successful, VCU should communicate HV connect successful/ unsuccessful status to TGU.";
CM_ SG_ 821 VCU_ChargingPlugSta "AC/DC Charging plug status ";
CM_ SG_ 821 VCU_DISP_AMBT_TEMP_FATC "Ambient Temperature";
CM_ SG_ 821 VCU_HVACHeatingSta "HVAC Heating status";
CM_ SG_ 821 VCU_HVACCoolingSta "HVAC Cooling Status";
CM_ SG_ 821 VCU_HVACCoolingPower "HVAC Cabin Cooling Power";
CM_ SG_ 821 VCU_ActiveDampingDisableCommand "Active Damping Disable command";
BA_DEF_  "BusType" STRING ;
BA_DEF_  "DBName" STRING ;
BA_DEF_ EV_  "GenEnvControlType" ENUM  "NoControl","SliderHoriz","SliderVert","PushButton","Edit","BitmapSwitch";
BA_DEF_ SG_  "SignalType" STRING ;
BA_DEF_ SG_  "SignalCategory" HEX 10 15;
BA_DEF_ SG_  "GenSigTimeoutTime_IS" INT 0 65535;
BA_DEF_ SG_  "CmxSigDefaultRaw" HEX 0 2147483647;
BA_DEF_ SG_  "GwSigLatencyTime" INT 0 65535;
BA_DEF_ SG_  "GwSigMissingSourceType" ENUM  "Undef","OldValue","DefaultValue","InitialValue";
BA_DEF_ SG_  "GenSigEnvVarType" ENUM  "int","float","undef";
BA_DEF_ SG_  "GenSigEVName" STRING ;
BA_DEF_ SG_  "GenSigStartValue" INT 0 0;
BA_DEF_ SG_  "GenSigSendType" ENUM  "Cyclic","OnWrite","OnWriteWithRepetition","OnChange","OnChangeWithRepetition","IfActive","IfActiveWithRepetition","NoSigSendType";
BA_DEF_ SG_  "GenSigInactiveValue" INT 0 0;
BA_DEF_ SG_  "SigCreator" STRING ;
BA_DEF_ BO_  "NWM-Botschaft" ENUM  "nein","ja";
BA_DEF_ BO_  "GenMsgNrOfRepetitions" INT 1 999999;
BA_DEF_ BO_  "MsgCreator" STRING ;
BA_DEF_ BO_  "GenMsgTimeOut" INT 0 0;
BA_DEF_ BO_  "DiagState" ENUM  "No","Yes";
BA_DEF_ BO_  "DiagRequest" ENUM  "No","Yes";
BA_DEF_ BO_  "DiagResponse" ENUM  "No","Yes";
BA_DEF_ BO_  "TpTxIndex" INT 0 255;
BA_DEF_ BO_  "GenMsgILSupport" ENUM  "No","Yes";
BA_DEF_ BO_  "GenMsgNrOfRepetition" INT 0 3;
BA_DEF_ BO_  "GenMsgDelayTime" INT 0 0;
BA_DEF_ BO_  "GenMsgCycleTimeFast" INT 0 500;
BA_DEF_ BO_  "GenMsgStartDelayTime" INT 0 140;
BA_DEF_ BO_  "GenMsgSendType" ENUM  "Cyclic","Spontaneous","not_used","not_used","not_used","Cyclic","not_used","IfActive","NoMsgSendType";
BA_DEF_ BO_  "GenMsgCycleTime" INT 0 0;
BA_DEF_ BU_  "NWM-Knoten" ENUM  "nein","ja";
BA_DEF_ BU_  "NodeLayerModules" STRING ;
BA_DEF_ BU_  "GenNodSleepTime" INT 1375 1650;
BA_DEF_ BU_  "NmNode" ENUM  "No","Yes";
BA_DEF_ BU_  "NmCAN" INT 1 2;
BA_DEF_ BU_  "ILUsed" ENUM  "No","Yes";
BA_DEF_REL_ BU_SG_REL_  "GenSigTimeoutTime" INT 30 3500;
BA_DEF_DEF_  "BusType" "";
BA_DEF_DEF_  "DBName" "";
BA_DEF_DEF_  "GenEnvControlType" "NoControl";
BA_DEF_DEF_  "SignalType" "";
BA_DEF_DEF_  "SignalCategory" 10;
BA_DEF_DEF_  "GenSigTimeoutTime_IS" 0;
BA_DEF_DEF_  "CmxSigDefaultRaw" 0;
BA_DEF_DEF_  "GwSigLatencyTime" 40;
BA_DEF_DEF_  "GwSigMissingSourceType" "Undef";
BA_DEF_DEF_  "GenSigEnvVarType" "undef";
BA_DEF_DEF_  "GenSigEVName" "";
BA_DEF_DEF_  "GenSigStartValue" 0;
BA_DEF_DEF_  "GenSigSendType" "Cyclic";
BA_DEF_DEF_  "GenSigInactiveValue" 0;
BA_DEF_DEF_  "SigCreator" "M&M-IVN";
BA_DEF_DEF_  "NWM-Botschaft" "nein";
BA_DEF_DEF_  "GenMsgNrOfRepetitions" 1;
BA_DEF_DEF_  "MsgCreator" "M&M-IVN";
BA_DEF_DEF_  "GenMsgTimeOut" 0;
BA_DEF_DEF_  "DiagState" "No";
BA_DEF_DEF_  "DiagRequest" "No";
BA_DEF_DEF_  "DiagResponse" "No";
BA_DEF_DEF_  "TpTxIndex" 0;
BA_DEF_DEF_  "GenMsgILSupport" "Yes";
BA_DEF_DEF_  "GenMsgNrOfRepetition" 0;
BA_DEF_DEF_  "GenMsgDelayTime" 0;
BA_DEF_DEF_  "GenMsgCycleTimeFast" 0;
BA_DEF_DEF_  "GenMsgStartDelayTime" 0;
BA_DEF_DEF_  "GenMsgSendType" "Cyclic";
BA_DEF_DEF_  "GenMsgCycleTime" 0;
BA_DEF_DEF_  "NWM-Knoten" "nein";
BA_DEF_DEF_  "NodeLayerModules" "dmoseknm.dll,CANoeILNLVector.dll";
BA_DEF_DEF_  "GenNodSleepTime" 1500;
BA_DEF_DEF_  "NmNode" "Yes";
BA_DEF_DEF_  "NmCAN" 1;
BA_DEF_DEF_  "ILUsed" "Yes";
BA_DEF_DEF_REL_ "GenSigTimeoutTime" 1400;
BA_ "BusType" "CAN";
BA_ "DBName" "SMART_CORE";
BA_ "NodeLayerModules" BU_ SMART_CORE "CANoeILNLVector.dll";
BA_ "GenMsgCycleTime" BO_ 1506 500;
BA_ "GenMsgCycleTime" BO_ 1041 100;
BA_ "GenMsgCycleTime" BO_ 1166 200;
BA_ "GenMsgCycleTime" BO_ 1443 500;
BA_ "GenMsgCycleTime" BO_ 1419 500;
BA_ "GenMsgCycleTime" BO_ 535 100;
BA_ "GenMsgCycleTime" BO_ 833 100;
BA_ "GenMsgDelayTime" BO_ 545 5;
BA_ "GenMsgCycleTime" BO_ 545 100;
BA_ "GenMsgCycleTime" BO_ 987 100;
BA_ "GenMsgCycleTime" BO_ 818 100;
BA_ "GenMsgCycleTime" BO_ 992 100;
BA_ "GenMsgCycleTime" BO_ 298 100;
BA_ "GenMsgCycleTime" BO_ 1019 200;
BA_ "GenMsgCycleTime" BO_ 445 10;
BA_ "GenMsgCycleTime" BO_ 1488 500;
BA_ "GenMsgCycleTime" BO_ 1486 500;
BA_ "GenMsgCycleTime" BO_ 1485 500;
BA_ "GenMsgCycleTime" BO_ 1484 500;
BA_ "GenMsgCycleTime" BO_ 1827 20;
BA_ "GenMsgCycleTime" BO_ 1828 20;
BA_ "GenMsgCycleTime" BO_ 1830 20;
BA_ "GenMsgCycleTime" BO_ 1831 20;
BA_ "GenMsgCycleTime" BO_ 1487 500;
BA_ "GenMsgCycleTime" BO_ 1483 500;
BA_ "GenMsgCycleTime" BO_ 1592 500;
BA_ "GenMsgCycleTime" BO_ 1279 30;
BA_ "GenMsgCycleTime" BO_ 1278 30;
BA_ "GenMsgCycleTime" BO_ 1277 30;
BA_ "GenMsgCycleTime" BO_ 1276 30;
BA_ "GenMsgCycleTime" BO_ 1275 30;
BA_ "GenMsgCycleTime" BO_ 1274 30;
BA_ "GenMsgCycleTime" BO_ 1273 30;
BA_ "GenMsgCycleTime" BO_ 1272 30;
BA_ "GenMsgCycleTime" BO_ 1271 30;
BA_ "GenMsgCycleTime" BO_ 1270 30;
BA_ "GenMsgCycleTime" BO_ 1269 30;
BA_ "GenMsgCycleTime" BO_ 1268 30;
BA_ "GenMsgCycleTime" BO_ 1267 30;
BA_ "GenMsgCycleTime" BO_ 1266 30;
BA_ "GenMsgCycleTime" BO_ 1265 30;
BA_ "GenMsgCycleTime" BO_ 1264 30;
BA_ "GenMsgCycleTime" BO_ 1007 100;
BA_ "GenMsgCycleTime" BO_ 823 20;
BA_ "GenMsgCycleTime" BO_ 443 10;
BA_ "GenMsgCycleTime" BO_ 628 30;
BA_ "GenMsgCycleTime" BO_ 991 100;
BA_ "GenMsgCycleTime" BO_ 580 30;
BA_ "GenMsgCycleTime" BO_ 989 100;
BA_ "GenMsgCycleTime" BO_ 825 100;
BA_ "GenMsgCycleTime" BO_ 352 50;
BA_ "GenMsgCycleTime" BO_ 345 50;
BA_ "GenMsgCycleTime" BO_ 344 50;
BA_ "GenMsgCycleTime" BO_ 979 10;
BA_ "GenMsgCycleTime" BO_ 1005 100;
BA_ "GenMsgTimeOut" BO_ 301 10;
BA_ "GenMsgCycleTime" BO_ 301 10;
BA_ "GenMsgCycleTime" BO_ 1003 100;
BA_ "GenMsgCycleTime" BO_ 981 100;
BA_ "GenMsgILSupport" BO_ 1949 0;
BA_ "GenMsgDelayTime" BO_ 1949 20;
BA_ "GenMsgSendType" BO_ 1949 1;
BA_ "GenMsgILSupport" BO_ 1941 0;
BA_ "GenMsgDelayTime" BO_ 1941 20;
BA_ "GenMsgSendType" BO_ 1941 1;
BA_ "GenMsgCycleTime" BO_ 779 100;
BA_ "DiagResponse" BO_ 1852 1;
BA_ "GenMsgSendType" BO_ 1852 1;
BA_ "DiagResponse" BO_ 1866 1;
BA_ "GenMsgSendType" BO_ 1866 1;
BA_ "GenMsgCycleTime" BO_ 1585 1000;
BA_ "GenMsgTimeOut" BO_ 1170 2000;
BA_ "GenMsgCycleTime" BO_ 1170 200;
BA_ "DiagResponse" BO_ 1994 1;
BA_ "GenMsgSendType" BO_ 1994 1;
BA_ "GenMsgTimeOut" BO_ 1169 2000;
BA_ "GenMsgCycleTime" BO_ 1169 200;
BA_ "DiagRequest" BO_ 1988 1;
BA_ "GenMsgSendType" BO_ 1988 1;
BA_ "DiagRequest" BO_ 2006 1;
BA_ "GenMsgSendType" BO_ 2006 1;
BA_ "DiagRequest" BO_ 2019 1;
BA_ "GenMsgILSupport" BO_ 2019 0;
BA_ "GenMsgDelayTime" BO_ 2019 5;
BA_ "GenMsgSendType" BO_ 2019 1;
BA_ "GenMsgCycleTime" BO_ 870 100;
BA_ "GenMsgCycleTime" BO_ 1654 1000;
BA_ "DiagRequest" BO_ 1958 1;
BA_ "GenMsgSendType" BO_ 1958 1;
BA_ "DiagRequest" BO_ 1959 1;
BA_ "GenMsgSendType" BO_ 1959 1;
BA_ "DiagRequest" BO_ 1842 1;
BA_ "GenMsgSendType" BO_ 1842 1;
BA_ "DiagRequest" BO_ 1986 1;
BA_ "GenMsgILSupport" BO_ 1986 0;
BA_ "GenMsgDelayTime" BO_ 1986 5;
BA_ "GenMsgSendType" BO_ 1986 1;
BA_ "DiagRequest" BO_ 1858 1;
BA_ "GenMsgSendType" BO_ 1858 1;
BA_ "DiagRequest" BO_ 1859 1;
BA_ "GenMsgSendType" BO_ 1859 1;
BA_ "GenMsgCycleTime" BO_ 1248 200;
BA_ "DiagRequest" BO_ 2017 1;
BA_ "GenMsgSendType" BO_ 2017 1;
BA_ "GenMsgSendType" BO_ 1955 1;
BA_ "GenMsgCycleTime" BO_ 1280 500;
BA_ "GenMsgCycleTime" BO_ 154 20;
BA_ "GenMsgNrOfRepetition" BO_ 955 1;
BA_ "GenMsgSendType" BO_ 955 1;
BA_ "GenMsgCycleTime" BO_ 957 100;
BA_ "GenMsgSendType" BO_ 1587 1;
BA_ "DiagRequest" BO_ 1856 1;
BA_ "GenMsgILSupport" BO_ 1856 0;
BA_ "GenMsgDelayTime" BO_ 1856 5;
BA_ "GenMsgSendType" BO_ 1856 1;
BA_ "GenMsgCycleTime" BO_ 1144 100;
BA_ "DiagResponse" BO_ 1963 1;
BA_ "GenMsgSendType" BO_ 1963 1;
BA_ "GenMsgCycleTime" BO_ 956 100;
BA_ "GenMsgTimeOut" BO_ 786 2000;
BA_ "GenMsgCycleTime" BO_ 786 200;
BA_ "GenMsgTimeOut" BO_ 784 2000;
BA_ "GenMsgCycleTime" BO_ 784 200;
BA_ "GenMsgTimeOut" BO_ 563 1000;
BA_ "GenMsgCycleTime" BO_ 563 100;
BA_ "GenMsgTimeOut" BO_ 295 100;
BA_ "GenMsgCycleTime" BO_ 295 10;
BA_ "GenMsgCycleTime" BO_ 375 20;
BA_ "GenMsgTimeOut" BO_ 294 100;
BA_ "GenMsgCycleTime" BO_ 294 10;
BA_ "GenMsgTimeOut" BO_ 304 200;
BA_ "GenMsgCycleTime" BO_ 304 20;
BA_ "GenMsgCycleTime" BO_ 1638 1000;
BA_ "GenMsgTimeOut" BO_ 1079 1000;
BA_ "GenMsgCycleTime" BO_ 1079 500;
BA_ "GenMsgTimeOut" BO_ 1078 1000;
BA_ "GenMsgCycleTime" BO_ 1078 500;
BA_ "GenMsgCycleTime" BO_ 1406 200;
BA_ "GenMsgTimeOut" BO_ 1077 1000;
BA_ "GenMsgCycleTime" BO_ 1077 500;
BA_ "GenMsgCycleTime" BO_ 752 50;
BA_ "GenMsgCycleTime" BO_ 1584 100;
BA_ "GenMsgCycleTime" BO_ 1595 100;
BA_ "GenMsgCycleTime" BO_ 1596 100;
BA_ "GenMsgCycleTime" BO_ 1428 1000;
BA_ "GenMsgCycleTime" BO_ 922 10;
BA_ "DiagResponse" BO_ 1867 1;
BA_ "GenMsgSendType" BO_ 1867 1;
BA_ "GenMsgCycleTime" BO_ 1582 100;
BA_ "DiagResponse" BO_ 1965 1;
BA_ "GenMsgSendType" BO_ 1965 1;
BA_ "DiagResponse" BO_ 1967 1;
BA_ "GenMsgSendType" BO_ 1967 1;
BA_ "DiagResponse" BO_ 2014 1;
BA_ "GenMsgSendType" BO_ 2014 1;
BA_ "DiagResponse" BO_ 1996 1;
BA_ "GenMsgSendType" BO_ 1996 1;
BA_ "GenMsgCycleTime" BO_ 767 50;
BA_ "GenMsgCycleTime" BO_ 917 100;
BA_ "DiagResponse" BO_ 2027 1;
BA_ "GenMsgSendType" BO_ 2027 1;
BA_ "DiagResponse" BO_ 1966 1;
BA_ "GenMsgSendType" BO_ 1966 1;
BA_ "DiagResponse" BO_ 1850 1;
BA_ "GenMsgSendType" BO_ 1850 1;
BA_ "GenMsgCycleTime" BO_ 666 100;
BA_ "GenMsgCycleTime" BO_ 930 50;
BA_ "GenMsgCycleTime" BO_ 929 50;
BA_ "GenMsgCycleTime" BO_ 1653 1000;
BA_ "GenMsgCycleTime" BO_ 272 20;
BA_ "GenMsgCycleTime" BO_ 950 100;
BA_ "GenMsgNrOfRepetition" BO_ 962 1;
BA_ "GenMsgSendType" BO_ 962 1;
BA_ "GenMsgCycleTime" BO_ 158 20;
BA_ "GenMsgCycleTime" BO_ 949 100;
BA_ "GenMsgSendType" BO_ 2031 1;
BA_ "GenMsgCycleTime" BO_ 1594 100;
BA_ "GenMsgCycleTime" BO_ 1583 100;
BA_ "DiagResponse" BO_ 2025 1;
BA_ "GenMsgSendType" BO_ 2025 1;
BA_ "GenMsgCycleTime" BO_ 1581 100;
BA_ "GenMsgCycleTime" BO_ 1413 500;
BA_ "GenMsgSendType" BO_ 259 1;
BA_ "DiagResponse" BO_ 1864 1;
BA_ "GenMsgSendType" BO_ 1864 1;
BA_ "GenMsgCycleTime" BO_ 1786 20;
BA_ "GenMsgCycleTime" BO_ 1787 20;
BA_ "GenMsgCycleTime" BO_ 1784 20;
BA_ "GenMsgCycleTime" BO_ 1785 20;
BA_ "GenMsgSendType" BO_ 2023 1;
BA_ "DiagRequest" BO_ 1844 1;
BA_ "GenMsgSendType" BO_ 1844 1;
BA_ "DiagRequest" BO_ 1957 1;
BA_ "GenMsgSendType" BO_ 1957 1;
BA_ "GenMsgCycleTime" BO_ 581 30;
BA_ "GenMsgCycleTime" BO_ 274 10;
BA_ "GenMsgCycleTime" BO_ 819 100;
BA_ "GenMsgCycleTime" BO_ 821 100;
BA_ "GenSigStartValue" SG_ 1506 IBS_Q_DISCHARGE 65534;
BA_ "GenSigStartValue" SG_ 1506 IBS_Q_CHARGE 65534;
BA_ "GenSigStartValue" SG_ 1506 IBS_INT_RESISTANCE_ERR 13;
BA_ "GenSigStartValue" SG_ 1506 IBS_INT_RESISTANCE 4094;
BA_ "GenSigStartValue" SG_ 1041 I_BATT_QUIES_IBS 252;
BA_ "GenSigStartValue" SG_ 1041 U_BATT_IBS 16382;
BA_ "GenSigStartValue" SG_ 1041 I_BATT_HIGH_IBS 65533;
BA_ "GenSigStartValue" SG_ 1166 SOC_ERR_IBS 13;
BA_ "GenSigStartValue" SG_ 1166 SOH_SUL_ERR_IBS 13;
BA_ "GenSigStartValue" SG_ 1166 VOLTAGE_PEAK_IBS 62;
BA_ "GenSigStartValue" SG_ 1166 SOFV_STOP_ENABLE_IBS 254;
BA_ "GenSigStartValue" SG_ 1166 SOFV_RESTART_IBS 254;
BA_ "GenSigStartValue" SG_ 1166 SOH_COR_IBS 100;
BA_ "GenSigStartValue" SG_ 1166 SOH_LAM_IBS 100;
BA_ "GenSigStartValue" SG_ 1166 SOH_SUL_IBS 100;
BA_ "GenSigStartValue" SG_ 1166 SOC_IBS 100;
BA_ "GenSigSendType" SG_ 545 STS_EPS_STEERING_MODE 7;
BA_ "GenSigSendType" SG_ 545 EPS_STEERING_MODE_ALERT 7;
BA_ "GenSigSendType" SG_ 545 EPS_STEERING_MODE 7;
BA_ "GenSigStartValue" SG_ 1487 GPS_ALTITUDE 50000;
BA_ "GenSigStartValue" SG_ 1592 ALTITUDE_CS_BIAS_GEO_VS_ELLIPS 15000;
BA_ "GenSigSendType" SG_ 1276 REM_DATA_12_MSG_CNT 7;
BA_ "GenSigStartValue" SG_ 1007 VCU_TorqueCoasting 48;
BA_ "GenSigStartValue" SG_ 989 LDC_Primary_Temperature 550;
BA_ "GenSigStartValue" SG_ 989 LDC_MOSFET_Temperature 550;
BA_ "GenSigStartValue" SG_ 989 LDC_Secondary_Temperature 550;
BA_ "GenSigStartValue" SG_ 825 BMS_BatteryMinTemperature 680;
BA_ "GenSigStartValue" SG_ 825 BMS_BatteryMaxTemperature 680;
BA_ "GenSigStartValue" SG_ 1005 BMS_BatteryAvgTemperature 680;
BA_ "GenSigStartValue" SG_ 301 BMS_BatteryBusVoltage 3650;
BA_ "GenSigStartValue" SG_ 301 BMS_BatteryPackCurrent 6000;
BA_ "GenSigStartValue" SG_ 1003 BMS_CellTemp9 500;
BA_ "GenSigStartValue" SG_ 1003 BMS_CellTemp8 500;
BA_ "GenSigStartValue" SG_ 1003 BMS_CellTemp7 500;
BA_ "GenSigStartValue" SG_ 1003 BMS_CellTemp6 500;
BA_ "GenSigStartValue" SG_ 1003 BMS_CellTemp5 500;
BA_ "GenSigStartValue" SG_ 1003 BMS_CellTemp4 500;
BA_ "GenSigStartValue" SG_ 1003 BMS_CellTemp32 500;
BA_ "GenSigStartValue" SG_ 1003 BMS_CellTemp31 500;
BA_ "GenSigStartValue" SG_ 1003 BMS_CellTemp30 500;
BA_ "GenSigStartValue" SG_ 1003 BMS_CellTemp29 500;
BA_ "GenSigStartValue" SG_ 1003 BMS_CellTemp28 500;
BA_ "GenSigStartValue" SG_ 1003 BMS_CellTemp27 500;
BA_ "GenSigStartValue" SG_ 1003 BMS_CellTemp26 500;
BA_ "GenSigStartValue" SG_ 1003 BMS_CellTemp25 500;
BA_ "GenSigStartValue" SG_ 1003 BMS_CellTemp24 500;
BA_ "GenSigStartValue" SG_ 1003 BMS_CellTemp23 500;
BA_ "GenSigStartValue" SG_ 1003 BMS_CellTemp22 500;
BA_ "GenSigStartValue" SG_ 1003 BMS_CellTemp21 500;
BA_ "GenSigStartValue" SG_ 1003 BMS_CellTemp20 500;
BA_ "GenSigStartValue" SG_ 1003 BMS_CellTemp19 500;
BA_ "GenSigStartValue" SG_ 1003 BMS_CellTemp18 500;
BA_ "GenSigStartValue" SG_ 1003 BMS_CellTemp17 500;
BA_ "GenSigStartValue" SG_ 1003 BMS_CellTemp16 500;
BA_ "GenSigStartValue" SG_ 1003 BMS_CellTemp15 500;
BA_ "GenSigStartValue" SG_ 1003 BMS_CellTemp14 500;
BA_ "GenSigStartValue" SG_ 1003 BMS_CellTemp13 500;
BA_ "GenSigStartValue" SG_ 1003 BMS_CellTemp12 500;
BA_ "GenSigStartValue" SG_ 1003 BMS_CellTemp11 500;
BA_ "GenSigStartValue" SG_ 1003 BMS_CellTemp10 500;
BA_ "GenSigStartValue" SG_ 1003 BMS_CellTemp3 500;
BA_ "GenSigStartValue" SG_ 1003 BMS_CellTemp2 500;
BA_ "GenSigStartValue" SG_ 1003 BMS_CellTemp1 500;
BA_ "GenSigSendType" SG_ 1949 DIAG_SBRM_RES_DATA 7;
BA_ "GenSigSendType" SG_ 1941 DIAG_SBRM_REQ_DATA 7;
BA_ "GenSigStartValue" SG_ 1170 IBS_BATT_TEMP_MBFM 80;
BA_ "GenSigStartValue" SG_ 1170 IBS_CURRENT_MBFM 1250;
BA_ "GenSigStartValue" SG_ 1280 REQ_POWERTRAIN_CUSTOM_MODE 2;
BA_ "GenSigSendType" SG_ 1280 IC11_MSG_CNT 7;
BA_ "GenSigSendType" SG_ 1280 IC11_CRC 7;
BA_ "GenSigStartValue" SG_ 1280 IC_DRV_MOD_REQ 2;
BA_ "GenSigSendType" SG_ 1280 IC_STEERING_MODE_REQ 7;
BA_ "GenSigSendType" SG_ 956 RESERVED_2 7;
BA_ "GenSigStartValue" SG_ 786 IBS_CURRENT 1250;
BA_ "GenSigStartValue" SG_ 786 IBS_BATT_TEMP 80;
BA_ "GenSigSendType" SG_ 295 ENG_LOSSES 7;
BA_ "GenSigEnvVarType" SG_ 295 ENG_LOSSES 0;
BA_ "GenSigSendType" SG_ 295 EMS21_MSG_CNT 7;
BA_ "GenSigSendType" SG_ 295 EMS21_CRC 7;
BA_ "GenSigSendType" SG_ 375 TGS_LEVER_AMT 7;
BA_ "GenSigEnvVarType" SG_ 375 TGS_LEVER_AMT 0;
BA_ "GenSigTimeoutTime_IS" SG_ 375 TGS_LEVER_AMT 100;
BA_ "SignalType" SG_ 375 TGS_LEVER_AMT "ENM";
BA_ "SignalType" SG_ 375 AMT_MIL "ENM";
BA_ "GenSigStartValue" SG_ 294 MAX_ALL_TRQ 1024;
BA_ "GenSigStartValue" SG_ 294 MIN_ALL_TRQ 1024;
BA_ "GenSigSendType" SG_ 304 ENGINE_DRIVE_MODE 7;
BA_ "GenSigStartValue" SG_ 1077 IDLING_INDEX 10;
BA_ "GenSigStartValue" SG_ 1077 GEAR_MISMATCH 10;
BA_ "GenSigStartValue" SG_ 1077 OVR_SPD 10;
BA_ "GenSigStartValue" SG_ 1077 CLTH_OVRRIDE 10;
BA_ "GenSigStartValue" SG_ 1077 AGG_BRK 10;
BA_ "GenSigStartValue" SG_ 1077 AGG_ACC 10;
BA_ "GenSigStartValue" SG_ 1582 COMMANDED_EGR 300;
BA_ "GenSigStartValue" SG_ 1582 EGR_ERR 600;
BA_ "GenSigStartValue" SG_ 1582 MEUNT_SETPOINT_RAIL_PRESSURE 200;
BA_ "GenSigStartValue" SG_ 1582 MEUNT_SETPOINT_ADPT_CORECT 200;
BA_ "GenSigStartValue" SG_ 1582 MEUNT_CTCL_FLTACT_CURVAL 100;
BA_ "GenSigStartValue" SG_ 1582 FUEL_RAIL_PRESSURE 100;
BA_ "GenSigSendType" SG_ 950 RESERVED_2 7;
BA_ "GenSigSendType" SG_ 962 RESERVED_2 7;
BA_ "GenSigSendType" SG_ 949 RESERVED_2 7;
BA_ "GenSigSendType" SG_ 2025 DIAG_TCU_RES_DATA 7;
BA_ "GenSigStartValue" SG_ 1581 COMMANDED_THRTL_ACTR_CTL 500;
BA_ "GenSigStartValue" SG_ 1413 ENG_OIL_TEMP 40;
BA_ "GenSigSendType" SG_ 259 IMMOVAL3 7;
BA_ "GenSigStartValue" SG_ 274 VCU_TorqueCommand 48;
BA_ "GenSigStartValue" SG_ 821 VCU_DISP_AMBT_TEMP_FATC 40;
VAL_ 3221225472 VCU_DRIVE_MODE 7 "Signal Invalid" 6 "Reserved" 5 "Reserved" 4 "Reserved" 3 "Normal/Default value" 2 "Sports" 1 "ECO Mode" 0 "Reserved" ;
VAL_ 1506 IBS_Q_DISCHARGE 65535 "Signal_Invalid" ;
VAL_ 1506 IBS_Q_CHARGE 65535 "Signal_Invalid" ;
VAL_ 1506 IBS_INT_RESISTANCE_ERR 15 "Invalid" 14 "Inaccurate (>15%)" ;
VAL_ 1506 IBS_INT_RESISTANCE 4095 "Signal_Invalid" ;
VAL_ 1041 T_BATT_IBS 255 "Signal_Invalid" ;
VAL_ 1041 ALTER_MODE_IBS 4 "Diagnostic" 3 "Regen" 2 "Float" 1 "Normal Temp" 0 "Cut off" ;
VAL_ 1041 ALTER_DUTYCYCLE_IBS 127 "Signal_Invalid" ;
VAL_ 1041 IBS_ERROR 1 "Error" 0 "No Error" ;
VAL_ 1041 U_BATT_IBS 16383 "Signal_Invalid" ;
VAL_ 1041 I_BATT_HIGH_IBS 65535 "Invalid" 65534 "Out of Range" ;
VAL_ 1166 SOC_ERR_IBS 15 "Invalid" 14 "Inaccurate (>15%)" ;
VAL_ 1166 SOH_SUL_ERR_IBS 15 "Invalid" 14 "Inaccurate (>15%)" ;
VAL_ 1166 ENG_COOLANT_FAN_IBS 3 "Both FAN ON" 2 "High speed Fan ON" 1 "Low speed FAN ON" 0 "OFF" ;
VAL_ 1166 GLOW_PLUG_IBS 1 "Glow Plug On" 0 "Glow Plug Off" ;
VAL_ 1166 SOFV_STOP_ENABLE_IBS 255 "Signal_Invalid" ;
VAL_ 1166 SOFV_RESTART_IBS 255 "Signal_Invalid" ;
VAL_ 1166 SOH_COR_IBS 255 "Signal_Invalid" ;
VAL_ 1166 SOH_LAM_IBS 255 "Signal_Invalid" ;
VAL_ 1166 SOH_SUL_IBS 127 "Signal_Invalid" ;
VAL_ 1166 SOC_IBS 127 "Signal_Invalid" ;
VAL_ 1443 IBS_START_ACTVN_DLY 1 "Starter Activation Delay ON" 0 "Starter Activation Delay OFF" ;
VAL_ 1443 BATT_FLG_DISCONN_IBS 1 "Battery_Disconnected" 0 "Battery_Connected" ;
VAL_ 1443 LV_BATT_FIT_MONTH_IBS 12 "Dec" 11 "Nov" 10 "Oct" 9 "Sep" 8 "Aug" 7 "Jul" 6 "Jun" 5 "May" 4 "Apr" 3 "Mar" 2 "Feb" 1 "Jan" 0 "Default" ;
VAL_ 1443 LV_BATT_MANF_MONTH_IBS 12 "Dec" 11 "Nov" 10 "Oct" 9 "Sep" 8 "Aug" 7 "Jul" 6 "Jun" 5 "May" 4 "Apr" 3 "Mar" 2 "Feb" 1 "Jan" 0 "Default" ;
VAL_ 1443 LV_BATT_CAPACITY_IBS 15 "Reserved" 14 "DIN 80 AH" 13 "DIN 70 AH" 12 "DIN 60 AH" 11 "DIN 50 AH" 10 "JIS 33 AH" 9 "JIS 38 AH" 8 "JIS 45 AH" 7 "JIS 50 AH" 6 "JIS 55 AH" 5 "JIS 65 AH" 4 "JIS 72 AH" 3 "JIS 80 AH" 2 "JIS 85 AH" 1 "JIS 90 AH" 0 "Default" ;
VAL_ 1443 LV_BATT_SUPPLIER_IBS 5 "Reserved" 4 "Amaron AM" 3 "Exide AM" 2 "Amaron OE" 1 "Exide OE" 0 "Default" ;
VAL_ 1443 IBS_WAKEUP_REASON 3 "Battery_Voltage_WakeUp" 2 "CurrentQuiesc_Wakeup" 1 "SOC_Wakeup" 0 "No_Wakeup" ;
VAL_ 1419 ALERT_CNG 1 "Switch to Petrol" 0 "No Alert/Default" ;
VAL_ 1419 STS_FUEL_LID_CNG 1 "Fuel Lid Open" 0 "Default / Fuel lid Closed" ;
VAL_ 1419 DIST_TO_EMPTY_CNG 1023 "Signal Invalid" 0 "Default value" ;
VAL_ 1419 SYSTEM_STS_CNG 7 "Reserved" 6 "Reserved" 5 "Reserved" 4 "Reserved" 3 "Petrol Mode" 2 "Petrol to CNG Transition" 1 "CNG to Petrol Transition" 0 "Default value / CNG mode" ;
VAL_ 1419 AVG_KMPL_CNG 511 "Signal Invalid" 0 "Default value" ;
VAL_ 1419 FUEL_LEVEL_CNG 127 "Signal Invalid" 126 "Default value" ;
VAL_ 535 RVC_GUIDED_VOICE_REQ 7 "Angle_Parking_VMS_2" 6 "Angle_Parking_VMS_1" 5 "Parallel Parking_VMS_4" 4 "Parallel Parking_VMS_3" 3 "Parallel Parking_VMS_2" 2 "Parallel Parking_VMS_1" 1 "Parking Slection" 0 "No Reminder Info" ;
VAL_ 535 RVC_OPERATION_STATE 7 "Reserved" 6 "Reserved" 5 "Test Mode(Internal)-video ON" 4 "RVC Faulty(RVC OFF)" 3 "Calibration EOL/Dealer Video ON" 2 "Fault(Video ON)" 1 "Operation(Video ON)" 0 "Standby(Video OFF)" ;
VAL_ 535 RVC_BUTTON_GROUP 15 "Reserved" 14 "Reserved" 13 "Reserved" 12 "Reserved" 11 "Button_Group_11" 10 "Button_Group_10" 9 "Button_Group_9" 8 "Button_Group_8" 7 "Button_Group_7" 6 "Button_Group_6" 5 "Button_Group_5" 4 "Button_Group_4" 3 "Button_Group_3" 2 "Button_Group_2" 1 "Button_Group_1" 0 "No Button / Default" ;
VAL_ 833 F_TRIG_F_STATE 3 "Reserved" 2 "Reserved" 1 "Stop Forced Authen process" 0 "Start Force Authen process" ;
VAL_ 545 STS_EPS_STEERING_MODE 3 "RESERVED" 2 "IN PROGRESS" 1 "ACTIVE" 0 "DEFAULT" ;
VAL_ 545 EPS_STEERING_MODE_ALERT 1 "EPS Steering mode inhibited" 0 "No alert/ DEFAULT" ;
VAL_ 545 EPS_STEERING_MODE 3 "RESERVED" 2 "SPORT" 1 "NORMAL" 0 "COMFORT" ;
VAL_ 545 EPS_DRV_ADV_MODE 7 "Signal Invalid" 6 "Sand / Mode 7" 5 "Mud & Rut / Mode 6" 4 "Grass/Snow / Mode 5" 3 "Normal / Mode 4" 2 "Sport / Mode 3" 1 "City Mode / Mode 2" 0 "Dynamic Mode / Mode 1" ;
VAL_ 545 INDC_EPS 1 "ON" 0 "OFF / Default" ;
VAL_ 545 EPS_FLEX_DISP 1 "Display" 0 "NoDisplay" ;
VAL_ 987 OBC_EVWARNING_TT 3 "Reserved" 2 "EV Warning Blink" 1 "EV Warning On" 0 "EV Warning Off/Default value" ;
VAL_ 987 OBC_ALERT_MESGS 45 "Reserved" 44 "Reserved" 43 "Reserved" 42 "Reserved" 41 "Reserved" 40 "Reserved" 39 "Reserved" 38 "Reserved" 37 "Reserved" 36 "Reserved" 35 "Reserved" 34 "Reserved" 33 "Reserved" 32 "Reserved" 31 "Reserved" 30 "Reserved" 29 "Reserved" 28 "Reserved" 27 "Reserved" 26 "Reserved" 25 "Reserved" 24 "Reserved" 23 "Reserved" 22 "Reserved" 21 "Reserved" 20 "Reserved" 19 "Reserved" 18 "Reserved" 17 "Reserved" 16 "Reserved" 15 "Reserved" 14 "Reserved" 13 "Reserved" 12 "Reserved" 11 "Reserved" 10 "Reserved" 9 "Reserved" 8 "Drive Fault( EV Sys Malfunction)" 7 "Safe Mode" 6 "Reserved" 5 "Reserved" 4 "Reserved" 3 "Reserved" 2 "Reserved" 1 "Charge Fault" 0 "No Message/Default value" ;
VAL_ 818 MCU_EVWARNING_TT 3 "Reserved" 2 "EV Warning Blink" 1 "EV Warning   On" 0 "EV Warning Off/Default value" ;
VAL_ 818 MCU_ALERT_MSGS 45 "Reserved" 44 "Reserved" 43 "Reserved" 42 "Reserved" 41 "Reserved" 40 "Reserved" 39 "Reserved" 38 "Reserved" 37 "Reserved" 36 "Reserved" 35 "Reserved" 34 "Reserved" 33 "Reserved" 32 "Reserved" 31 "Reserved" 30 "Reserved" 29 "Reserved" 28 "Hill hold Deactive" 27 "Reserved" 26 "Reserved" 25 "Reserved" 24 "Reserved" 23 "Reserved" 22 "Reserved" 21 "Reserved" 20 "Reserved" 19 "Reserved" 18 "Reserved" 17 "Reserved" 16 "Reserved" 15 "Reserved" 14 "Reserved" 13 "Reserved" 12 "Reserved" 11 "Reserved" 10 "Reserved" 9 "Reserved" 8 "Drive fault (EV Sys Malfunction)" 7 "Safe Mode" 6 "Reserved" 5 "Reserved" 4 "GO SLOW(Limp Home)" 3 "Reserved" 2 "Reserved" 1 "Reserved" 0 "Reserved" ;
VAL_ 992 LDC_EVWARNING_TT 3 "Reserved" 2 "EV Warning Blink" 1 "EV Warning   On" 0 "EV Warning Off/Default value" ;
VAL_ 992 LDC_ALERT_MSGS 45 "Reserved" 44 "Reserved" 43 "Reserved" 42 "Reserved" 41 "Reserved" 40 "Reserved" 39 "Reserved" 38 "Reserved" 37 "Reserved" 36 "Reserved" 35 "Reserved" 34 "Reserved" 33 "Reserved" 32 "Reserved" 31 "Reserved" 30 "Reserved" 29 "Reserved" 28 "Reserved" 27 "Reserved" 26 "Reserved" 25 "Reserved" 24 "Reserved" 23 "Reserved" 22 "Reserved" 21 "Reserved" 20 "Reserved" 19 "Reserved" 18 "Reserved" 17 "Reserved" 16 "Reserved" 15 "Reserved" 14 "Reserved" 13 "Reserved" 12 "Reserved" 11 "Reserved" 10 "Reserved" 9 "Reserved" 8 "Drive Fault( EV Sys Malfunction)" 7 "Reserved" 6 "Reserved" 5 "Reserved" 4 "Reserved" 3 "Reserved" 2 "Reserved" 1 "Reserved" 0 "No Message/Default value" ;
VAL_ 298 BMS_BattEnergyDisAcc_Drv 1 "SIGNAL INVALID" 0 "NO FAULT/DEFAULT" ;
VAL_ 298 BMS_BattEnergyAcc_Regen 1 "SIGNAL INVALID" 0 "NO FAULT/DEFAULT" ;
VAL_ 298 BMS_BattEnergyAcc_NC 1 "SIGNAL INVALID" 0 "NO FAULT/DEFAULT" ;
VAL_ 298 BMS_BattEnergyAcc_FC 1 "SIGNAL INVALID" 0 "NO FAULT/DEFAULT" ;
VAL_ 1019 BMS_ServiceDueDetection 3 "Signal Invalid" 2 "Reserved" 1 "Service due (battery pack)" 0 "No Service due (battery pack)" ;
VAL_ 1019 BMS_BatteryContactorLife 2047 "Signal Invalid" 0 "Default Value" ;
VAL_ 445 STS_ITA 3 "reserved" 2 "Not available" 1 "Available" 0 "Default" ;
VAL_ 445 ITA_ACTIVE 1 "Active" 0 "Inactive / DV" ;
VAL_ 445 CCO_WARNING 7 "RESERVED" 6 "RESERVED" 5 "RESERVED" 4 "RESERVED" 3 "CCO BUTTON FAILED" 2 "HDC FAILED" 1 "TEMP OFF" 0 "NO WARN/DEFAULT" ;
VAL_ 445 CCO_SET_SPD 7 "Target velocity 7" 6 "Target velocity 6" 5 "Target velocity 5" 4 "Target velocity 4" 3 "Target velocity 3" 2 "Target velocity 2" 1 "Target velocity 1" 0 "No speed requirement/default" ;
VAL_ 445 CCO_ACTIVE 3 "FAILURE" 2 "ACTIVE" 1 "STANDBY" 0 "OFF/DEFAULT" ;
VAL_ 1488 RSDS_TYPE 7 "Complete" 6 "Resume" 5 "Pause" 4 "Control" 3 "Abort" 2 "NACK_OR_RESEND" 1 "ACK_OR_CONT" 0 "Start" ;
VAL_ 1486 GPS_HDOP_V 1 "True" 0 "False" ;
VAL_ 1483 GPS_ALT_POSITION_STD_V 1 "True" 0 "False" ;
VAL_ 1483 GPS_NUM_SATELLITES_V 1 "True" 0 "False" ;
VAL_ 1483 GPS_MCU_TIMESTAMP_V 1 "True" 0 "False" ;
VAL_ 1483 GPS_LONGITUDE_V 1 "True" 0 "False" ;
VAL_ 1483 GPS_LONG_POSITION_STD_V 1 "True" 0 "False" ;
VAL_ 1483 GPS_LONG_DIRECTION_V 1 "True" 0 "False" ;
VAL_ 1483 GPS_LONG_DIRECTION 1 "WEST" 0 "EAST" ;
VAL_ 1483 GPS_LATITUDE_V 1 "True" 0 "False" ;
VAL_ 1483 GPS_LAT_POSITION_STD_V 1 "True" 0 "False" ;
VAL_ 1483 GPS_LAT_DIRECTION_V 1 "True" 0 "False" ;
VAL_ 1483 GPS_LAT_DIRECTION 1 "SOUTH" 0 "NORTH" ;
VAL_ 1483 GPS_EPOCH_TIMESTAMP_V 1 "True" 0 "False" ;
VAL_ 1483 GPS_COURSE_V 1 "True" 0 "False" ;
VAL_ 1483 GPS_ALTITUDE_V 1 "True" 0 "False" ;
VAL_ 1592 ALTITUDE_CS_GEO_VS_ELLIPS_VALID 1 "TRUE" 0 "FALSE" ;
VAL_ 1592 COUNTRY_CODE_CAPITAL 2 "Non_Capital/ Default" 1 "Capital" 0 "Not_Set" ;
VAL_ 1592 COUNTRY_CODE_FIRST_CHAR 26 "Z" 25 "Y" 24 "X" 23 "W" 22 "V" 21 "U" 20 "T" 19 "S" 18 "R" 17 "Q" 16 "P" 15 "O" 14 "N" 13 "M" 12 "L" 11 "K" 10 "J" 9 "I/ Default" 8 "H" 7 "G" 6 "F" 5 "E" 4 "D" 3 "C" 2 "B" 1 "A" 0 "NONE" ;
VAL_ 1592 FIX_STS 6 "TIME_FIX" 5 "3D_DR" 4 "DR" 3 "3D" 2 "2D" 1 "NO_FIX" 0 "INIT_FIX" ;
VAL_ 1592 FIX_STS_VALID 1 "TRUE" 0 "FALSE" ;
VAL_ 1592 GPS_EGO_SPEED_VALID 1 "TRUE" 0 "FALSE" ;
VAL_ 1592 HOR_DILU_PRECISION_VALID 1 "TRUE" 0 "FALSE" ;
VAL_ 1592 ONE_PPS 1 "TRUE" 0 "FALSE" ;
VAL_ 1592 ONE_PPS_VALID 1 "TRUE" 0 "FALSE" ;
VAL_ 1592 COUNTRY_CODE_SCND_CHAR 26 "Z" 25 "Y" 24 "X" 23 "W" 22 "V" 21 "U" 20 "T" 19 "S" 18 "R" 17 "Q" 16 "P" 15 "O" 14 "N/ Default" 13 "M" 12 "L" 11 "K" 10 "J" 9 "I" 8 "H" 7 "G" 6 "F" 5 "E" 4 "D" 3 "C" 2 "B" 1 "A" 0 "NONE" ;
VAL_ 1007 VCU_TorqueCoasting 0 "Default Value" ;
VAL_ 1007 VCU_SwitchS2 1 "Activated" 0 "Not Activated" ;
VAL_ 1007 VCU_StCreep 1 "Activated" 0 "Not Activated" ;
VAL_ 1007 VCU_StCoasting 1 "Activated" 0 "Not Activated" ;
VAL_ 1007 VCU_HVAccPowerConsumption 65535 "Invalid" 0 "Default" ;
VAL_ 1007 VCU_EConsPerKm 65535 "Invalid" 0 "Default" ;
VAL_ 823 VCU_StsCodEvse 7 "Reserved" 6 " EVSE_Malfunction" 5 "EVSE_EmergencyShutdown" 4 "EVSE_IsolationMonitoringActive" 3 " EVSE_UtilityInterruptEvent" 2 "EVSE_Shutdown" 1 "EVSE_Ready" 0 "EVSE_NotReady" ;
VAL_ 823 VCU_MaxDischargeCurrent 0 "Default Value" ;
VAL_ 823 VCU_MaxChargeCurrent 0 "Default Value" ;
VAL_ 823 VCU_CmdTargetVoltLDC 255 "Signal invalid" 0 "Default Value" ;
VAL_ 823 VCU_CmdEnableLDC 3 "Invalid" 2 "Reserved" 1 "Enable" 0 "Disable / Initial Value" ;
VAL_ 823 VCU_MainContactorControl 3 "Invalid" 2 "Open Contactor" 1 "Close Contactor" 0 "Init/Default" ;
VAL_ 628 LDC_Lid_STS 3 "SIgnal Invalid" 2 "Close" 1 "Open" 0 "Default" ;
VAL_ 628 LDC_HVIL_Interlock4 3 "Signal Invalid" 2 "Close" 1 "Open" 0 "Init" ;
VAL_ 628 LDC_ACTV_Discharge_STS 2 "ACT_DIS_unsuccessful_with_error" 1 "ACT_DIS_Initiated" 0 "Default" 4 "Signal Invalid" 3 "ACT_DIS_complete_without_error" ;
VAL_ 628 LDC_OperationMode 7 "Invalid" 6 "Reserved" 5 "Reserved" 4 "Fault" 3 "Power Delivery" 2 "Ready" 1 "Not Ready/ Wakeup" 0 "Default Value" ;
VAL_ 628 LDC_FCVoltageValue 4095 "Signal Invalid" 0 "Default Value" ;
VAL_ 628 LDC_HVIL_Interlock3 3 "Signal Invalid" 2 "Close" 1 "Open" 0 "Init" ;
VAL_ 628 LDC_HVIL_Interlock2 3 "Signal Invalid" 2 "Close" 1 "Open" 0 "Init" ;
VAL_ 628 LDC_HVIL_Interlock1 3 "Signal Invalid" 2 "Close" 1 "Open" 0 "Init" ;
VAL_ 991 LDC_OPV_Circuit_Error 1 "Fault" 0 "Default/No fault" ;
VAL_ 991 LDC_Low_Temp_Shutdown 1 "Fault" 0 "Default/No fault" ;
VAL_ 991 LDC_IPV_Circuit_Error 1 "Fault" 0 "Default/No fault" ;
VAL_ 991 LDC_INTERNAL_FAIL 1 "Fault" 0 "Default/No fault" ;
VAL_ 991 LDC_Input_Over_Current 1 "Fault" 0 "Default/No fault" ;
VAL_ 991 LDC_Heat_Sink_Over_Temp_Shutdown 1 "Fault/Warning" 0 "Default/No Fault" ;
VAL_ 991 LDC_HVDC_Side_Relay_Sts 1 "ON" 0 "OFF" ;
VAL_ 991 LDC_CC_CV_STS 1 "CV" 0 "CC" ;
VAL_ 991 LDC_Burst_Mode_Sts 1 "Burst Mode" 0 "Normal Mode" ;
VAL_ 991 LDC_HW_Enable 1 "ON" 0 "OFF" ;
VAL_ 991 LDC_Stage 7 "Signal Invalid" 0 "Default" ;
VAL_ 991 LDC_Debounce_Count 7 "Signal Invalid" 0 "Default " ;
VAL_ 991 LDC_Vprog_Out_of_Range 1 "Fault" 0 "Default/No fault" ;
VAL_ 991 LDC_Watchdog_Failure 1 "Fault/Warning" 0 "Default/No Fault" ;
VAL_ 991 LDC_VCU_Node_Absent 1 "Fault/Warning" 0 "Default/No Fault" ;
VAL_ 991 LDC_Temp_Sensing_Failure 1 "Fault/Warning" 0 "Default/No Fault" ;
VAL_ 991 LDC_IPC_COMM_ERR_OBC 1 "Fault/Warning" 0 "Default/No Fault" ;
VAL_ 991 LDC_EEPROM_Failure 1 "Fault/Warning" 0 "Default/No Fault" ;
VAL_ 991 LDC_Short_Circuit 1 "Fault/Warning" 0 "Default/No Fault" ;
VAL_ 991 LDC_Output_Under_Voltage 1 "Fault/Warning" 0 "Default/No Fault" ;
VAL_ 991 LDC_Output_Over_Voltage 1 "Fault/Warning" 0 "Default/No Fault" ;
VAL_ 991 LDC_Output_Over_Current 1 "Fault/Warning" 0 "Default/No Fault" ;
VAL_ 991 LDC_LPS_Under_Voltage 1 "Fault/Warning" 0 "Default/No Fault" ;
VAL_ 991 LDC_LPS_Over_Voltage 1 "Fault/Warning" 0 "Default/No Fault" ;
VAL_ 991 LDC_Input_Under_Voltage 1 "Fault/Warning" 0 "Default/No Fault" ;
VAL_ 991 LDC_Input_Over_Voltage 1 "Fault/Warning" 0 "Default/No Fault" ;
VAL_ 991 LDC_Heat_Sink_Over_Temp_Wng_2 1 "Fault/Warning" 0 "Default/No Fault" ;
VAL_ 991 LDC_Heat_Sink_Over_Temp_Wng_1 1 "Fault/Warning" 0 "Default/No Fault" ;
VAL_ 991 LDC_Heat_Sink_Over_Temp_Wng_0 1 "Fault/Warning" 0 "Default/No Fault" ;
VAL_ 991 LDC_Amb_Over_Temp_Wng 1 "Fault/Warning" 0 "Default/No Fault" ;
VAL_ 991 LDC_Amb_Over_Temp_Shutdown 1 "Fault/Warning" 0 "Default/No Fault" ;
VAL_ 580 LDC_OutputVoltageValue 4095 "Signal Invalid" 0 "Default Value" ;
VAL_ 580 LDC_OutputCurrent 16383 "Signal Invalid" 0 "Default Value" ;
VAL_ 580 LDC_InputVoltageValue 16383 "Signal Invalid" 0 "Default Value" ;
VAL_ 580 LDC_InputCurrentValue 0 "Default value" 255 "Signal Invalid" ;
VAL_ 989 LDC_Primary_Temperature 4095 "Signal Invalid" 820 "Default" ;
VAL_ 989 LDC_CoolingRequest 255 "Default" ;
VAL_ 989 LDC_MOSFET_Temperature 820 "Default value" 4095 "Invalid Value" ;
VAL_ 989 LDC_Secondary_Temperature 820 "Default value" 4095 "Invalid Value" ;
VAL_ 989 LDC_ProtectionMode 7 "Invalid" 6 "Reserved" 5 "Power Derating3" 4 "Power Derating2" 3 "PowerDerating1" 2 "Fault" 1 "Ok" 0 "Standby/Default" ;
VAL_ 825 BMS_BatteryMinTemperature 680 "Default Value" 4095 "Signal Invalid" ;
VAL_ 825 BMS_BatteryMaxTemperature 680 "DefaultValue" 4095 "Signal Invalid" ;
VAL_ 825 BMS_Actual_Batt_Heater_Pwr 255 "Signal invalid" 0 "Default Value" ;
VAL_ 825 BMS_Req_Batt_Heater_Pwr 255 "Signal Invalid" 0 "Default Value" ;
VAL_ 825 BMS_ChargingStop 1 "Charging Stop Request ON" 0 "Charging Stop Req OFF/Default" ;
VAL_ 825 BMS_BCoolingRequest 3 "Signal Invalid" 2 "Reserved" 1 "Cooling Request ON" 0 "Cooling Request OFF/Default" ;
VAL_ 979 BMS_Discharge_Cycle 65535 "Signal Invalid" 0 "Default Value" ;
VAL_ 979 BMS_Charge_Cycle 65535 "Signal Invalid" 0 "Default Value" ;
VAL_ 979 BMS_ChargePowerAvailable_2 0 "Default value" 4095 "Signal Invalid" ;
VAL_ 979 BMS_ChargePowerAvailable_10 0 "Default value" 4095 "Signal Invalid" ;
VAL_ 1005 BMS_BattBalancingCompSta 4 "Signal Invalid" 3 "Not Completed/Unsuccessful" 2 "In progress" 1 "Completed/Succesful" 0 "Default" ;
VAL_ 1005 BMS_BatteryBalancingSta 2 "Signal Invalid" 1 "ON" 0 "OFF/Default" ;
VAL_ 1005 BMS_BCoolPumpFBSta 6 "Reserved" 5 "Reserved" 4 "Reserved" 3 "Reserved" 7 "Signal Invalid" 2 "Error" 1 "ON" 0 "OFF/Init/Default" ;
VAL_ 1005 BMS_BatteryLowSOC 3 "Signal Invalid" 2 "Reserved" 1 "ON" 0 "OFF/Default" ;
VAL_ 1005 BMS_BatteryAvgTemperature 680 "Default Value" 4095 "Signal Invalid" ;
VAL_ 1005 BMS_STS_IGN 1 "ON (IGN Present)" 0 "OFF(IGN Not Present)/Default" ;
VAL_ 1005 BMS_CellVoltHighWarnDegdFault 3 "ON Level 3 (Fault)" 2 "ON Level 2 (Derated)" 1 "ON Level 1 (Warning)" 0 "OFF" ;
VAL_ 1005 BMS_BPlusContactorWeld 1 "BPlus Contactor Weld" 0 "BPlus Contactor Not Weld" ;
VAL_ 1005 BMS_BMinusContactorWeld 1 "Bminus Conatctor Weld" 0 "Bminus Contactor Not Weld" ;
VAL_ 301 BMS_ACTV_Discharge_STS 4 "Signal Invalid" 3 "Status Unknown" 2 "Active Discharge Failed" 1 "Active Discharge Success" 0 "Default" ;
VAL_ 301 BMS_BatteryBusVoltage 16383 "Signal Invalid" 3650 "Default Value" ;
VAL_ 301 BMS_BatteryPackStatus 7 "Signal Invalid" 6 "Reserved" 5 "Reserved" 4 "Reserved" 3 "Cutoff" 2 "Derated (Error2)" 1 "Warning (Error1)" 0 "Normal / Default  Value" ;
VAL_ 301 BMS_BatteryPackCurrent 6000 "Default Value" 16383 "Invalid Value" ;
VAL_ 301 BMS_OperationMode 15 "Signal Invalid" 14 "Reserved" 13 "Reserved" 12 "Reserved" 11 "Reserved" 10 "Reserved" 9 "Sleep" 8 "HV Disconnect wait" 7 "Discharge" 6 "Charge Stop" 5 "Charge" 4 "Ready" 3 "HV Connect Wait" 2 "Low Power" 1 "Wake Up" 0 "Reserved" ;
VAL_ 1003 BMS_CellTemp9 65535 "Signal Invalid" 750 "Default Value" ;
VAL_ 1003 BMS_CellTemp8 65535 "Signal Invalid" 750 "Default Value" ;
VAL_ 1003 BMS_CellTemp7 65535 "Signal Invalid" 750 "Default Value" ;
VAL_ 1003 BMS_CellTemp6 65535 "Signal Invalid" 750 "Default Value" ;
VAL_ 1003 BMS_CellTemp5 65535 "Signal Invalid" 750 "Default Value" ;
VAL_ 1003 BMS_CellTemp4 65535 "Signal Invalid" 750 "Default Value" ;
VAL_ 1003 BMS_CellTemp32 65535 "Signal Invalid" 750 "Default Value" ;
VAL_ 1003 BMS_CellTemp31 65535 "Signal Invalid" 750 "Default Value" ;
VAL_ 1003 BMS_CellTemp30 65535 "Signal Invalid" 750 "Default Value" ;
VAL_ 1003 BMS_CellTemp29 65535 "Signal Invalid" 750 "Default Value" ;
VAL_ 1003 BMS_CellTemp28 65535 "Signal Invalid" 750 "Default Value" ;
VAL_ 1003 BMS_CellTemp27 65535 "Signal Invalid" 750 "Default Value" ;
VAL_ 1003 BMS_CellTemp26 65535 "Signal Invalid" 750 "Default Value" ;
VAL_ 1003 BMS_CellTemp25 65535 "Signal Invalid" 750 "Default Value" ;
VAL_ 1003 BMS_CellTemp24 65535 "Signal Invalid" 750 "Default Value" ;
VAL_ 1003 BMS_CellTemp23 65535 "Signal Invalid" 750 "Default Value" ;
VAL_ 1003 BMS_CellTemp22 65535 "Signal Invalid" 750 "Default Value" ;
VAL_ 1003 BMS_CellTemp21 65535 "Signal Invalid" 750 "Default Value" ;
VAL_ 1003 BMS_CellTemp20 65535 "Signal Invalid" 750 "Default Value" ;
VAL_ 1003 BMS_CellTemp19 65535 "Signal Invalid" 750 "Default Value" ;
VAL_ 1003 BMS_CellTemp18 65535 "Signal Invalid" 750 "Default Value" ;
VAL_ 1003 BMS_CellTemp17 65535 "Signal Invalid" 750 "Default Value" ;
VAL_ 1003 BMS_CellTemp16 65535 "Signal Invalid" 750 "Default Value" ;
VAL_ 1003 BMS_CellTemp15 65535 "Signal Invalid" 750 "Default Value" ;
VAL_ 1003 BMS_CellTemp14 65535 "Signal Invalid" 750 "Default Value" ;
VAL_ 1003 BMS_CellTemp13 65535 "Signal Invalid" 750 "Default Value" ;
VAL_ 1003 BMS_CellTemp12 65535 "Signal Invalid" 750 "Default Value" ;
VAL_ 1003 BMS_CellTemp11 65535 "Signal Invalid" 750 "Default Value" ;
VAL_ 1003 BMS_CellTemp10 65535 "Signal Invalid" 750 "Default Value" ;
VAL_ 1003 BMS_CellTemp3 65535 "Signal Invalid" 750 "Default Value" ;
VAL_ 1003 BMS_CellTemp2 65535 "Signal Invalid" 750 "Default Value" ;
VAL_ 1003 BMS_CellTemp1 65535 "Signal Invalid" 750 "Default Value" ;
VAL_ 981 BMS_BatteryInstantEnergyCons 4095 "Signal Invalid" 0 "Default value" ;
VAL_ 981 BMS_AveEnergyCons 4095 "Signal Invalid" 0 "Default Value" ;
VAL_ 981 BMS_ALERT_MSGS 45 "Reserved" 44 "Reserved" 43 "Park and Leave Vehicle" 42 "Low Temperature" 41 "Reserved" 40 "Reserved" 39 "Reserved" 38 "Reserved" 37 "Reserved" 36 "Reserved" 35 "Reserved" 34 "Reserved" 33 "Reserved" 32 "Charging" 31 "Reserved" 30 "High Temperature" 29 "Reserved" 28 "Reserved" 27 "Reserved" 26 "Isolation fault" 25 "Reserved" 24 "Reserved" 23 "Reserved" 22 "Reserved" 21 "Reserved" 20 "Reserved" 19 "Reserved" 18 "Reserved" 17 "Reserved" 16 "Reserved" 15 "Reserved" 14 "Reserved" 13 "Reserved" 12 "Reserved" 11 "Service Due" 10 "Reserved" 9 "Reserved" 8 "Drive Fault(EV Sys Malfunction)" 7 "Safe Mode" 6 "Reserved" 5 "Reserved" 4 "GO SLOW(Limp Home)" 3 "Reserved" 2 "Reserved" 1 "Charge Fault" 0 "No Message/Default value" ;
VAL_ 981 BMS_STS_CHARGE_LIGHT_TT 3 "Reserved" 2 "Charge Light Blink" 1 "Charge Light On" 0 "Charge Light Off/Default" ;
VAL_ 981 BMS_SERVICE_LIGHT_TT 3 "Reserved" 2 "Service Light Blink" 1 "Service Light On" 0 "Service Light Off/Default value" ;
VAL_ 981 BMS_HV_BATT_TT 3 "Reserved" 2 "Flash" 1 "ON" 0 "No Failure/Default" ;
VAL_ 981 BMS_HIGH_TEMP_LIGHT_OP_TT 3 "Reserved" 2 "Temp Light Blink" 1 "Temp Light On" 0 "Temp Light Off/Default value" ;
VAL_ 981 BMS_EVWARNING_TT 3 "Reserved" 2 "EV Warning Blink" 1 "EV Warning   On" 0 "EV Warning Off/Default value" ;
VAL_ 779 TIME_GAP_FRM 255 "NO Object Detected / Default" ;
VAL_ 1585 TRANSFER_MODE_ICC 3 "Signal Invalid" 2 "4WD Low" 1 "4WD High" 0 "2WD / Default Value" ;
VAL_ 1585 ICC_ALERT_MSG 7 "Reserved" 6 "Reserved" 5 "Reserved" 4 "Reserved" 3 "Transfer Mode Entered" 2 "Transfer mod Shifting InProgress" 1 "Terrain Mode Inhibited" 0 "No Alert/ Default" ;
VAL_ 1170 IBS_BATT_TEMP_MBFM 65535 "Signal Invalid" 0 "Default" ;
VAL_ 1170 IBS_BATT_VOLT_MBFM 65535 "Signal Invalid" 4 "Default" ;
VAL_ 1170 IBS_CURRENT_MBFM 65535 "Signal Invalid" 0 "Default" ;
VAL_ 1169 BATT_RESET_FLG_MBFM 1 "True" 0 "False / Default" ;
VAL_ 1169 STS_ESS_DEACTIVATION_MBFM 7 "Reserved" 6 "Reserved" 5 "Reserved" 4 "Preemptive Start" 3 "ESS Deactivation" 2 "ESS Start Inhibit" 1 "ESS Stop Inhibit" 0 "Default" ;
VAL_ 1169 BATT_CHARGE_LAMP_INDC_MBFM 3 "Signal Invalid" 2 "Reserved" 1 "ON/Default" 0 "OFF" ;
VAL_ 1169 ALTERNATOR_MODE_MBFM 7 "Signal Invalid" 6 "Reserved" 5 "Reserved" 4 "Reserved" 3 "Redun" 2 "Cutoff" 1 "Regen" 0 "Normal/default" ;
VAL_ 1169 IBS_SOF_MBFM 255 "Signal Invalid" 0 "Default" ;
VAL_ 1169 IBS_SOH_MBFM 255 "Signal Invalid" 0 "Default" ;
VAL_ 1169 IBS_SOC_MBFM 255 "Signal Invalid" 0 "Default" ;
VAL_ 870 PKE_PACK_MCM 1 "Received" 0 "Other" ;
VAL_ 870 PKE_NACK_MCM 1 "Received" 0 "Other" ;
VAL_ 870 CURRENT_CYL_AUTH_STS_MCM 1 "Authentication Fail" 0 "Authentication Pass" ;
VAL_ 870 REMOTE_ENG_START_STATE_MCM 3 "Remote Engine Extension" 2 "Remote Engine Stop" 1 "Remote Engine Start request" 0 "Default" ;
VAL_ 870 TOTAL_AUTH_TIMER_STS_MCM 3 "Timer Elapsed" 2 "Reserve" 1 "Reserve" 0 "Timer not elapsed" ;
VAL_ 870 PREVIOUS_CYL_AUTH_STS 1 "Authentication Fail" 0 "Authentication Pass" ;
VAL_ 870 MCMTRG_RECEIVE_STS_MCM 1 "MCMTRG not sent" 0 "MCMTRG senrt" ;
VAL_ 870 MCM_NACK_TX 1 "Transmitted" 0 "Other" ;
VAL_ 870 MCM_PACK_TX 1 "Transmitted" 0 "Other" ;
VAL_ 870 RESPONSE_STS_MCM 1 "Response not sent" 0 "Response Sent" ;
VAL_ 870 PKE_CHALLENGE_STS_MCM 1 "PKE Challenge Not Received" 0 "PKE Challenge Received" ;
VAL_ 870 REMOTE_VEH_IMMO_STS_MCM 1 "Remote Vehicle Immobilization" 0 "Remote Vehicle Release" ;
VAL_ 870 SIG1_MATCH_STS 1 "SIG1 Match failed" 0 "SIG1 Match passed" ;
VAL_ 1654 UPDATE_REPROG_USER_AUTH 3 "Reserved" 2 "Default Value" 1 "Req UsrAuth to ReProg aft downld" 0 "Usr acptd/UsrAuth not req reprg" ;
VAL_ 1654 UPDATE_DOWNLOAD_USER_AUTH 3 "Reserved" 2 "Default Value" 1 "Req UsrAuth to downld update" 0 "Usr acptd/UsrAuth not req update" ;
VAL_ 1248 GEAR_UTILIZATION_ECO_GEAR_R 0 "Default Value" ;
VAL_ 1248 GEAR_UTILIZATION_ECO_GEAR_N 0 "Default Value" ;
VAL_ 1248 GEAR_UTILIZATION_ECO_GEAR_6 0 "Default Value" ;
VAL_ 1248 GEAR_UTILIZATION_ECO_GEAR_5 0 "Default Value" ;
VAL_ 1248 GEAR_UTILIZATION_ECO_GEAR_4 0 "Default Value" ;
VAL_ 1248 GEAR_UTILIZATION_ECO_GEAR_3 0 "Default Value" ;
VAL_ 1248 GEAR_UTILIZATION_ECO_GEAR_2 0 "Default Value" ;
VAL_ 1248 GEAR_UTILIZATION_ECO_GEAR_1 0 "Default Value" ;
VAL_ 1280 REQ_FATC_CUSTOM_MODE 7 "Reserved" 6 "Reserved" 5 "Reserved" 4 "Reserved" 3 "Default" 2 "Sport Mode" 1 "City  Mode" 0 "Dynamic Mode " ;
VAL_ 1280 REQ_EPS_CUSTOM_MODE 7 "Reserved" 6 "Reserved" 5 "Reserved" 4 "Reserved" 3 "Default" 2 "Sport Mode" 1 "City  Mode" 0 "Dynamic Mode " ;
VAL_ 1280 REQ_BRAKES_CUSTOM_MODE 7 "Reserved" 6 "Reserved" 5 "Reserved" 4 "Reserved" 3 "Default" 2 "Sport Mode" 1 "City  Mode" 0 "Dynamic Mode " ;
VAL_ 1280 REQ_POWERTRAIN_CUSTOM_MODE 7 "Reserved" 6 "Reserved" 5 "Reserved" 4 "Reserved" 3 "Default" 2 "Sport Mode" 1 "City  Mode" 0 "Dynamic Mode " ;
VAL_ 1280 CUSTOM_MODE_REQ_IC 1 "Custom Mode ON" 0 "Custom Mode OFF/DV" ;
VAL_ 1280 IC_DRV_MOD_REQ 7 "Signal Invalid" 6 "Reserved / Mode 6" 5 "Reserved / Mode 5" 4 "Reserved / Mode 4" 3 "Default" 2 "Sport Mode / Mode 3" 1 "Eco / City / Mode 2" 0 "Power / Dynamic / Mode 1 " ;
VAL_ 1280 MODE_SELECTION_SWT 13 "Reserved" 12 "Reserved" 11 "Reserved" 10 "Reserved" 9 "Reserved" 8 "Reserved" 7 "Reserved" 14 "Reserved" 15 "Signal Invalid" 6 "Reserved" 5 "Reserved" 4 "Reserved" 3 "SAND " 2 "MUD & RUT " 1 "Grass / Snow " 0 "Normal / Default" ;
VAL_ 1280 IC_STEERING_MODE_REQ 7 "SIGNAL INVALID" 6 "RESERVED" 5 "RESERVED" 4 "RESERVED" 3 "SPORT" 2 "NORMAL" 1 "COMFORT" 0 "DEFAULT" ;
VAL_ 154 MCM_WAKEUP_REASON 14 "Reserved" 13 "Reserved" 12 "Reserved" 11 "window open/close request" 10 "Vehicle Battery Status request" 9 "Remote Charging Request" 8 "Passive Ventilation request" 7 "Park Lamp OFF Request" 6 "Remote Engine Start Request" 5 "Headlamp ON/OFF Request" 4 "Hazard Request" 3 "Search Car Request" 2 "Door Unock Request" 1 "Door Lock Request" 0 "Default" ;
VAL_ 1587 VEH_BATT_STS_REQ 1 "Vehicle Battery Status Request" 0 "Default / No Request" ;
VAL_ 1587 REMOTE_START_TIMER_REQUEST 0 "Default" ;
VAL_ 1587 REQ_PASSIVE_VENT_MCM 3 "Reserved" 2 "Deactive Passive Ventilation" 1 "Activate Passive ventilation" 0 "Default/No request" ;
VAL_ 1587 SET_VACATION_MODE_MCM 1 "Enable" 0 "Disable/Default Value" ;
VAL_ 1587 TURN_OFF_AC_VALET_MCM 3 "SIGNAL INVALID" 2 "Default Value" 1 "Reserved" 0 "AC OFF" ;
VAL_ 1587 SUNROOF_UP_DOWN_MCM 3 "Reserved" 2 "Sunroof Close" 1 "Sunroof Open" 0 "Default" ;
VAL_ 1587 POWER_WIND_UP_DOWN_MCM 3 "Reserved" 2 "Power Window Open" 1 "Power Window Close" 0 "Default" ;
VAL_ 1587 REMOTE_START_EXT_REQ_MCM 4 "4th Extension" 3 "3rd Extension" 2 "2nd Extension" 1 "1st Extension" 0 "Default/No Extension" ;
VAL_ 1587 REMOTE_ENG_START_STOP_MCM 3 "Signal Invalid" 2 "Remote Engine Stop" 1 "Remote Engine Start" 0 "Default" ;
VAL_ 1587 INHIBIT_ENG_START_MCM 1 "Inhibit Engine Start" 0 "DEFAULT/NORMAL" ;
VAL_ 1587 TURN_ON_OFF_PARK_LAMP_MCM 1 "off request" 0 "No Request/Default" ;
VAL_ 1587 REQ_HEADLAMP_MCM 3 "Signal Invalid" 2 "Headlamp ON" 1 "Headlamp Off" 0 "Default / No req" ;
VAL_ 1587 REQ_HAZARD_MCM 3 "Signal Invalid" 2 "Hazard On" 1 "hazard Off" 0 "Default/No Req" ;
VAL_ 1587 SEARCH_CAR_MCM 1 "Search CAR Request" 0 "No Request" ;
VAL_ 1587 DOOR_LOCK_MCM 3 "Signal Invalid" 2 "Unlock" 1 "Lock" 0 "Default" ;
VAL_ 786 IBS_CURRENT 65535 "Signal Invalid" 0 "Default" ;
VAL_ 786 IBS_BATT_TEMP 65535 "Signal Invalid" 0 "Default" ;
VAL_ 786 IBS_BATT_VOLT 65535 "Signal Invalid" 4 "Default" ;
VAL_ 784 BATT_RESET_FLG 1 "True" 0 "False / Default" ;
VAL_ 784 STS_ESS_DEACTIVATION 7 "Reserved" 6 "Reserved" 5 "Reserved" 4 "Preemptive Start" 3 "ESS Deactivation" 2 "ESS Start Inhibit" 1 "ESS Stop Inhibit" 0 "Default" ;
VAL_ 784 IBS_SOC 255 "Signal Invalid" 0 "Default" ;
VAL_ 784 ALTERNATOR_MODE 7 "Signal Invalid" 6 "Reserved" 5 "Reserved" 4 "Reserved" 3 "Redun" 2 "Cutoff" 1 "Regen" 0 "Normal/default" ;
VAL_ 784 IBS_SOF 255 "Signal Invalid" 0 "Default" ;
VAL_ 784 IBS_SOH 255 "Signal Invalid" 0 "Default" ;
VAL_ 784 BATT_CHARGE_LAMP_INDC 3 "Signal Invalid" 2 "Reserved" 1 "ON/Default" 0 "OFF" ;
VAL_ 563 UREA_LEVEL_PERCENTAGE 255 "Signal Invalid" 0 "Default" ;
VAL_ 563 INCORRECT_DEF 7 "Reserved" 6 "Reserved" 5 "Reserved" 4 "Level4" 3 "Level3" 2 "Level2" 1 "Level1" 0 "Normal / Default value" ;
VAL_ 563 DIST_DEF_EMPTY 65533 "DEF Level Normal" 65535 "Signal invalid" 65534 "Default value" ;
VAL_ 563 DEF_LEVEL 7 "Reserved" 6 "Reserved" 5 "Reserved" 4 "Level4" 3 "Level3" 2 "Level2" 1 "Level1" 0 "Normal / Default value" ;
VAL_ 563 DEF_DOSING_MALFUNC 7 "Reserved" 6 "Reserved" 5 "Reserved" 4 "Level4" 3 "Level3" 2 "Level2" 1 "Level1" 0 "Normal / Default value" ;
VAL_ 563 INDC_REGEN 3 "Reserved" 2 "Regen TT Blink/regen in progress" 1 "Regen TT Lamp ON/regen needed" 0 "Regen TT Lamp OFF/No regen/DV" ;
VAL_ 295 ACC_PED_ACTUAL 255 "Signal Invalid" 0 "Default" ;
VAL_ 295 ENG_LOSSES 2047 "Signal invalid" 2046 "Default value" ;
VAL_ 295 BRK_PEDAL1 3 "Signal Invalid" 2 "Reserved" 1 "Depressed" 0 "Not Pressed / Default" ;
VAL_ 375 TGS_LEVER_AMT 15 "Signal Invalid" 14 "Middle Position" 13 "Default Value" 12 "M - Forward Drive Position" 11 "Tip -" 10 "Tip +" 9 "Park " 8 "Reverse" 7 "Neutral" 6 "Drive" 5 "Reserved" 4 "Reserved" 3 "Reserved" 2 "Reserved" 1 "Reserved" 0 "Reserved" ;
VAL_ 375 AMT_BUZZER 1 "BUZZER ON" 0 "BUZZER OFF / Default Value" ;
VAL_ 375 AMT_MIL 3 "Lamp ON" 2 "Reserved" 1 "Lamp Blinking" 0 "Lamp OFF / Default " ;
VAL_ 375 ALERT_AMT 7 "Reserved" 6 "Reserved" 5 "1st Gear not Enguage" 4 "Gear lock out" 3 "Operation Not Allowed" 2 "Press Brake" 1 "Put Vehicle in Neutral" 0 "Default Value" ;
VAL_ 294 HYBRID_LAMP_INDC 3 "Reserved" 2 "Lamp Blinking" 1 "Lamp ON" 0 "Lamp OFF/Default" ;
VAL_ 294 MAX_ALL_TRQ 2047 "Signal Invalid" 0 "Default" ;
VAL_ 294 GEAR_UP_FLG 1 "Flag Enable" 0 "Flag Disable / Default value" ;
VAL_ 294 GEAR_DOWN_FLG 1 "Gear_Down_Flag_Enable" 0 "Gear_Down_Flag_Disable" ;
VAL_ 294 MIN_ALL_TRQ 2047 "Signal Invalid" 0 "Default" ;
VAL_ 294 TARGET_GEAR_GSI 15 "Signal Invalid" 14 "Reserved" 13 "Reserved" 12 "Reserved" 11 "Reserved" 10 "Reserved" 9 "Reserved" 8 "Reserved" 7 "Reverse Gear" 6 "6th Gear" 5 "5th Gear" 4 "4th Gear" 3 "3rd Gear" 2 "2nd Gear" 1 "1st Gear" 0 "Neutral / Default" ;
VAL_ 304 ERROR_FLAG_VCU 3 "Reserved" 2 "Reserved" 1 "Error Present in EMS Memory" 0 "No Error Present in EMS memory" ;
VAL_ 304 CRUISE_ALERT 3 "Reserved" 2 "Cruise  Active " 1 "Cruise Standby" 0 "OFF / Default" ;
VAL_ 304 CRUISE_SET_SPD 65535 "Signal Invalid" 0 "Default" ;
VAL_ 304 INDC_SYS_LAMP 3 "Signal Invalid" 2 "Lamp ON" 1 "Lamp Blinking" 0 "Lamp OFF/Default" ;
VAL_ 304 ACC_READY 1 "Ready" 0 "Default / Not ready" ;
VAL_ 304 EMS_DRIVE_ALERT 3 "Reserved" 2 "Reserved" 1 "Drive Mode not possible" 0 "No Alert/Default" ;
VAL_ 304 STS_EMS_DRV_ADV_MODE 3 "Ready to enter" 2 "In Progress" 1 "Mode active / Default" 0 "Not active" ;
VAL_ 304 INDC_DPF_REGEN 3 "Reserved" 2 "Blink" 1 "DPF Lamp ON" 0 "DPF Lamp OFF / DV" ;
VAL_ 304 ENGINE_DRIVE_MODE 7 "Signal Invalid" 6 "Sand / Mode 7" 5 "Mud & Rut / Mode 6" 4 "Grass / Snow / Mode 5" 3 "Normal / Mode 4" 2 "Sport / Mode 3" 1 "Eco / City / Mode 2" 0 "Power / Dynamic / Mode 1" ;
VAL_ 304 FUEL_CONSMP_RATE 65535 "Signal Invalid" 0 "Default" ;
VAL_ 304 ENG_OIL_PRESSURE 1 "Oil Pressure Low" 0 "Normal / Default" ;
VAL_ 304 INDC_MIL 3 "Signal Invalid" 2 "MIL Lamp ON" 1 "MIL Lamp Blinking" 0 "MIL OFF/Default" ;
VAL_ 1638 ASD_TORQUE 127 "Signal Invalid" 0 " Default" ;
VAL_ 1638 ASD_POWER 127 "Signal Invalid" 0 " Default" ;
VAL_ 1638 INDC_ROLL_IS 127 "Signal Invalid" 0 "Default" ;
VAL_ 1638 INDC_PITCH_IS 127 "Signal Invalid" 0 "Default" ;
VAL_ 1638 ALTIMETER 8191 "Signal Invalid" 0 "Default" ;
VAL_ 1638 COMPASS_DIRECTION 15 "RESERVED" 14 "RESERVED" 13 "RESERVED" 12 "RESERVED" 11 "RESERVED" 10 "RESERVED" 9 "RESERVED" 8 "SOUTH WEST" 7 "SOUTH EAST" 6 "NORTH WEST" 5 "NORTH EAST" 4 "SOUTH" 3 "NORTH" 2 "WEST" 1 "EAST" 0 "Default" ;
VAL_ 1079 ESS_DURATION 4095 "Signal Invalid" 0 "Default Value" ;
VAL_ 1079 IDLING_DURATION 255 "Signal Invalid" 0 "Default Value" ;
VAL_ 1078 INST_ECO_INDEX_EMS 127 "Signal Invalid" 100 "Default Value" ;
VAL_ 1078 REMOTE_START_INHIBIT_REQ_IS 1 "Inhibit Request" 0 "No Request" ;
VAL_ 1078 TRIP_START_END 3 "Reserved" 2 "Trip End" 1 "Trip Start" 0 "Default" ;
VAL_ 1078 TRIP_ID 0 "Default" ;
VAL_ 1078 GEAR_UP_FLG 1 "Flag Enable" 0 "Flag Disable / Default value" ;
VAL_ 1078 GEAR_DOWN_FLG 1 "Gear_Down_Flag_Enable" 0 "Gear_Down_Flag_Disable" ;
VAL_ 1078 TRIP_DURATION_MIN 15 "Signal Invalid" 0 "Default Value" ;
VAL_ 1078 AVG_SPD 511 "Signal Invalid" 0 "Default Value" ;
VAL_ 1078 TOP_SPD 511 "Signal Invalid" 0 "Default Value" ;
VAL_ 1078 TRIP_DIST 65535 "Signal Invalid" 0 "Default Value" ;
VAL_ 1078 TRIP_DURATION_HOUR 127 "Signal Invalid" 0 "Default Value" ;
VAL_ 1406 FUEL_ECONOMY_ECO 0 "Description for the value '0x0'" ;
VAL_ 1406 TRIP_TAGGING_ECO 7 "Reserved" 6 "Reserved" 5 "Reserved" 4 "Reserved" 3 "Reserved" 2 "Personal Trip" 1 "Business Trip" 0 "Default Value" ;
VAL_ 1406 AGG_BRK_COUNT_ECO 0 "Description for the value '0x0'" ;
VAL_ 1406 AGG_ACC_COUNT_ECO 0 "Description for the value '0x0'" ;
VAL_ 1406 GEAR_UTILIZATION_ECO 0 "Default Value" ;
VAL_ 1406 AUDIO_SOURCE 15 "Reserved" 14 "Reserved" 13 "Reserved" 12 "Reserved" 11 "My Drive" 10 "Android Auto" 9 "Apple CARplay" 8 "Ipod" 7 "Bluetooth" 6 "AUX" 5 "USB" 4 "AM2" 3 "AM1" 2 "FM2" 1 "FM1" 0 "Default" ;
VAL_ 1077 CLUTCH_PRESS_CNT 255 "Signal Invalid" 0 "Default Value" ;
VAL_ 1077 BRK_PRESS_CNT 255 "Signal Invalid" 0 "Default Value" ;
VAL_ 1077 IDLING_INDEX 15 "Signal Invalid" 10 "Default value" ;
VAL_ 1077 GEAR_MISMATCH 15 "Signal Invalid" 10 "Default Value" ;
VAL_ 1077 OVR_SPD 15 "Signal Invalid" 10 "Default Value" ;
VAL_ 1077 CLTH_OVRRIDE 15 "Signal Invalid" 10 "Default Value" ;
VAL_ 1077 AGG_BRK 15 "Signal Invalid" 10 "Default Value" ;
VAL_ 1077 AGG_ACC 15 "Signal Invalid" 10 "Default Value" ;
VAL_ 1077 ECO_INDEX_IS11 127 "Signal Invalid" 100 "Default Value" ;
VAL_ 1077 STS_TRIP 1 "Trip Reset completed" 0 "Default Value" ;
VAL_ 1077 COMM_ERR_FLG 1 "Flag Enable" 0 "Flag Disable / Default Value" ;
VAL_ 1077 TPMS_FLG 1 "Flag Enable" 0 "Flag Disable / Default Value" ;
VAL_ 1077 AC_USAGE_REG_FLG 1 "Flag Enable" 0 "Flag Disable / Default Value" ;
VAL_ 1077 IDLING_FLG 1 "Flag Enable" 0 "Flag Disable / Default Value" ;
VAL_ 1077 OVRSPD_FLG 1 "Flag Enable" 0 "Flag Diable / Default Value" ;
VAL_ 1077 CLUTCH_OVRRIDE_FLG 1 "Flag Enable" 0 "Flag Disable / Default Value" ;
VAL_ 752 SVS_SWT 1 "Pressed" 0 "Not Pressed / Default" ;
VAL_ 752 STS_AUTO_ZOOM_IN_VIEW 1 "Enable" 0 "Disable/DV" ;
VAL_ 752 STS_AUTO_CORNER_VIEW 1 "Enable" 0 "Disable/DV" ;
VAL_ 752 DEFAULT_VIEW_FRONT 1 "Full View" 0 "Normal View" ;
VAL_ 752 SVS_SCREEN_ACTIVE_IS 1 "IS Screen Active" 0 "Not Active" ;
VAL_ 752 SVS_ENABLE_IS 1 "SVS Screen Enable" 0 "Default/SVS Screen Disable" ;
VAL_ 752 FIRST_TOUCH_COORDINATE_Y_IS 0 "Default Value" ;
VAL_ 752 FIRST_TOUCH_COORDINATE_X_IS 0 "Default Value" ;
VAL_ 752 FIRST_TOUCH_EVENT_IS 3 "Pen Move" 2 "Pen Up" 1 "Pen down" 0 "No touch/ Default value" ;
VAL_ 752 CMD_USER_INPUT 15 "Reserved" 14 "Reserved" 13 "Reserved" 12 "Reserved" 11 "Back" 10 "Right Corner View" 9 "Left Corner View" 8 "Merged Corner View" 7 "Full View" 6 "Zoom Out" 5 "Zoom In" 4 "Reset to parallel parking" 3 "Normal View" 2 "Vertical Parking" 1 "Parallel Parking" 0 "No Input/ Default" ;
VAL_ 752 ONTOUCH_INPUT_IS 3 "Three touch" 2 "Two touch" 1 "One touch" 0 "No touch/Default Value" ;
VAL_ 752 IS_REQUEST_VIEW 28 "Right full view without icons" 27 "Left full view without icons" 26 "Rear full view without icons" 24 "Right Fish View+2D/Man Cal" 23 "Left Fish View+2D/Man Cal" 22 "Rear Fish View+2D/Man Cal" 21 "Front Fish View+2D/Man Cal" 20 "2D Full View / Auto Cal" 19 "3D Full View / Bowl view" 18 " Intelligent View Rear" 17 " Intelligent View Front " 16 "2D+3D Rear Right view " 25 "Front full view without icons" 15 "2D+3D Rear Left view " 14 "2D+3D Front Right view " 13 "2D+3D Front Left view " 12 "2D+3D Right view " 11 "2D+3D Left view " 10 "2D+3D Rear view " 9 "2D+3D Front view " 8 "Right Full View" 7 "Left Full View" 6 "Rear Full View" 5 "Front Full View" 4 "2D+Right view " 3 "2D+Left view " 2 "2D+Rear view " 1 "2D+Front view " 0 "No View" ;
VAL_ 752 DEFAULT_VIEW_REAR 1 "Full View" 0 "Normal View" ;
VAL_ 752 IS_VIDEO_ENBL 7 "Reserved" 6 "Reserved" 5 "RVC & FVC Video Enabled" 4 "FVC Video Disabled" 3 "FVC Video Enabled" 2 "RVC Video Disabled" 1 "RVC Video Enabled" 0 "No Video Enabled / Default" ;
VAL_ 1428 BRAKE_PREDICTION_STS 3 "Invaild" 2 "Red" 1 "Green" 0 "Default / Not Available" ;
VAL_ 922 SVS_VIEW_REQUEST_IC 1 "Cluster view request" 0 "No request" ;
VAL_ 922 SVS_VIEW_REQUEST_IS 1 "Infotainment View Request" 0 "No request" ;
VAL_ 922 SVS_INFO 1 "pop-up" 0 "No pop-up" ;
VAL_ 922 SVS_GUIDED_VOICE_REQ 15 "Reserved" 14 "Reserved" 13 "Reserved" 12 "Reserved" 11 "Reserved" 10 "Reserved" 9 "Reserved" 8 "Reserved" 7 "Angle_Parking_VMS_2" 6 "Angle_Parking_VMS_1" 5 "Parallel Parking_VMS_4" 4 "Parallel Parking_VMS_3" 3 "Parallel Parking_VMS_2" 2 "Parallel Parking_VMS_1" 1 "Parking Slection" 0 "No Message" ;
VAL_ 1582 FUEL_PUMP_PREDICTION 0 "No Drift / Default" 3 "Reserved" 2 "High Drift" 1 "Moderate Drift" ;
VAL_ 767 ROTARY_ENCODER 63 "Reserved" 62 "Reserved" 61 "Reserved" 60 "Reserved" 59 "Reserved" 58 "Reserved" 57 "Reserved" 56 "Step 24" 55 "Step 23" 54 "Step 22" 53 "Step 21" 52 "Step 20" 51 "Step 19" 50 "Step 18" 49 "Step 17" 48 "Step 16" 47 "Step 15" 46 "Step 14" 45 "Step 13" 44 "Step 12" 43 "Step 11" 42 "Step 10" 41 "Step 9" 40 "Step 8" 39 "Step 7" 38 "Step 6" 37 "Step 5" 36 "Step 4" 35 "Step 3" 34 "Step 2" 33 "Step 1" 32 "Default" 31 "Step -1" 30 "Step -2" 29 "Step -3" 28 "Step -4" 27 "Step -5" 26 "Step -6" 25 "Step -7" 24 "Step -8" 23 "Step -9" 22 "Step -10" 21 "Step -11" 20 "Step -12" 19 "Step -13" 18 "Step -14" 17 "Step -15" 16 "Step -16" 15 "Step -17" 14 "Step -18" 13 "Step -19" 12 "Step -20" 11 "Step -21" 10 "Step -22" 9 "Step -23" 8 "Step -24" 7 "Reserved" 6 "Reserved" 5 "Reserved" 4 "Reserved" 3 "Reserved" 2 "Reserved" 1 "Reserved" 0 "Reserved" ;
VAL_ 767 CENTER_BUTTON_STS 3 "Switch Fault/ Signal Invalid" 2 "Reserved" 1 "Pressed" 0 "Not Pressed/ Default" ;
VAL_ 767 JOYSTICK_DB_STS 3 "Switch Fault/ Signal Invalid" 2 "Reserved" 1 "Pressed" 0 "Not Pressed/ Default" ;
VAL_ 767 JOYSTICK_UB_STS 3 "Switch Fault/ Signal Invalid" 2 "Reserved" 1 "Pressed" 0 "Not Pressed/ Default" ;
VAL_ 767 JOYSTICK_RB_STS 3 "Switch Fault/ Signal Invalid" 2 "Reserved" 1 "Pressed" 0 "Not Pressed/ Default" ;
VAL_ 767 JOYSTICK_LB_STS 3 "Switch Fault/ Signal Invalid" 2 "Reserved" 1 "Pressed" 0 "Not Pressed/ Default" ;
VAL_ 767 BUTTON4_STS 3 "Switch Fault/ Signal Invalid" 2 "Reserved" 1 "Pressed" 0 "Not Pressed/ Default" ;
VAL_ 767 BUTTON3_STS 3 "Switch Fault/ Signal Invalid" 2 "Reserved" 1 "Pressed" 0 "Not Pressed/ Default" ;
VAL_ 767 BUTTON2_STS 3 "Switch Fault/ Signal Invalid" 2 "Reserved" 1 "Pressed" 0 "Not Pressed/ Default" ;
VAL_ 767 BUTTON1_STS 3 "Switch Fault/ Signal Invalid" 2 "Reserved" 1 "Pressed" 0 "Not Pressed/ Default" ;
VAL_ 917 FVC_OPERATION_STATE 7 "Reserved" 6 "Reserved" 5 "Test Mode(Internal)-video ON" 4 "FVC Faulty(FVC OFF)" 3 "Calibration EOL/Dealer Video ON" 2 "Fault(Video ON)" 1 "Operation(Video ON)" 0 "Standby(Video OFF)" ;
VAL_ 917 FVC_BUTTON_GROUP 15 "Reserved" 14 "Reserved" 13 "Reserved" 12 "Reserved" 11 "Button_Group_11" 10 "Button_Group_10" 9 "Reserved" 8 "Reserved" 7 "Reserved" 6 "Button_Group_6" 5 "Button_Group_5" 4 "Button_Group_4" 3 "Button_Group_3" 2 "Reserved" 1 "Reserved" 0 "No Button / Default" ;
VAL_ 930 APA_MAMS_ACTIVE 1 "MAMS Active" 0 "MAMS Not Active / Default" ;
VAL_ 930 SLOT_LENGTH_WIDTH 161 "Reserved (0xA1 to 0xFE)" 1 "Valid lnght/Width(0x1 to 0xA0)" 255 "Invalid slot length/slot width" 0 "Default value" ;
VAL_ 930 SLOT_DEPTH 251 "Reserved (0xFB to 0xFE)" 1 "Valid slot depth(0x1 to 0xFA)" 255 "Invalid Slot Depth" 0 "Default Value" ;
VAL_ 930 DIST_TO_SLOT 201 "Reserved(0xC9 to 0xFE)" 1 "Valid dist to slot(0x1 to 0xC8)" 255 "Signal invalid" 0 "Default" ;
VAL_ 930 DIST_TO_SAFE_PT 201 "Reserved(0xC9 to 0xFE)" 1 "Valid dist to slot (0x1 to C8)" 255 "Signal invalid" 0 "Default" ;
VAL_ 930 APA_PROGRESS_PERCNTG 1 "Prcntg of  prgrss bar(0x1to0x63)" 100 "Progress bar is full" 101 "Reserved(0x65 to 0xFE)" 255 "Signal Invalid" 0 "Default" ;
VAL_ 930 APA_PARK_MODE 15 "Signal Invalid" 14 "Reserved" 13 "Reserved" 12 "Reserved" 11 "Reserved" 10 "Reserved" 9 "Reserved" 8 "Reserved" 7 "Reserved" 6 "Reserved" 5 "Reserved" 4 "Perpendicular drive out" 3 "Parallel drive out" 2 "Perpendicular parking" 1 "Parallel Parking" 0 "Default" ;
VAL_ 930 APA_PARK_DIRCTION 3 "Invalid" 2 "Left" 1 "Right" 0 "Default" ;
VAL_ 930 APA_INHIBIT_ST 1 "APA Inhibited" 0 "APA not Inhibited / Default" ;
VAL_ 930 APA_DISP_SUB_PIC 1 "Disp to guide drvr(0x1 to 0xE)" 15 "Signal Invalid" 0 "Default value(No pic to disp)" ;
VAL_ 930 APA_DISP_MAIN_PIC 1 "Disp to guide drvr(0x1 to 0x3E)" 63 "Signal Invalid" 0 "Default Value(No pic disp)" ;
VAL_ 930 APA_DISP 1 "APA Display on HMI Active" 0 "APA Display on HMI not active" ;
VAL_ 930 APA_ACTIVE 1 "APA System Active." 0 "APA System not active" ;
VAL_ 930 FPAS_SW_STS 1 "FPAS  Active." 0 "FPAS not active" ;
VAL_ 930 MAMS_SWT_STS 1 "MAMS switch pressed" 0 "MAMS switch not pressed / DV" ;
VAL_ 929 FLS_SEGMENT 15 "Sensor error" 14 "Reserved" 13 "Reserved" 12 "Reserved" 11 "Reserved" 10 "Reserved" 9 "Reserved" 8 "Reserved" 7 "Reserved" 6 "Display 6 Segment" 5 "Display 5 Segment" 4 "Display 4 Segment" 3 "Display 3 Segment" 2 "Display 2 Segment" 1 "Display 1 Segment" 0 "Default / No Display Segment" ;
VAL_ 929 LEFT_MIN_DIST 251 "Reserved (0xFB to 0xFE)" 255 "Default Value" 0 "Valid dist(0x0 to 0xFA)" ;
VAL_ 929 RRMS_SEGMENT 15 "Sensor error" 14 "Reserved" 13 "Reserved" 12 "Reserved" 11 "Reserved" 10 "Reserved" 9 "Reserved" 8 "Reserved" 7 "Reserved" 6 "Display 6 Segment" 5 "Display 5 Segment" 4 "Display 4 Segment" 3 "Display 3 Segment" 2 "Display 2 Segment" 1 "Display 1 Segment" 0 "Default / No Display Segment" ;
VAL_ 929 FRMS_SEGMENT 15 "Sensor error" 14 "Reserved" 13 "Reserved" 12 "Reserved" 11 "Reserved" 10 "Reserved" 9 "Reserved" 8 "Reserved" 7 "Reserved" 6 "Display 6 Segment" 5 "Display 5 Segment" 4 "Display 4 Segment" 3 "Display 3 Segment" 2 "Display 2 Segment" 1 "Display 1 Segment" 0 "Default / No Display Segment" ;
VAL_ 929 RIGHT_MIN_DIST 251 "Reserved (0xFB to 0x FE)" 255 "Default Value" 0 "Valid dist (0x0 t 0xFA)" ;
VAL_ 929 RRS_SEG_WARN 1 "Warning" 0 "No Warning/Default" ;
VAL_ 929 RRMS_SEG_WARN 1 "Warning" 0 "No Warning/Default" ;
VAL_ 929 RLMS_SEG_WARN 1 "Warning" 0 "No Warning/Default" ;
VAL_ 929 RLS_SEG_WARN 1 "Warning" 0 "No Warning/Default" ;
VAL_ 929 FRS_SEG_WARN 1 "Warning" 0 "No Warning/Default" ;
VAL_ 929 FLMS_SEG_WARN 1 "Warning" 0 "No Warning/Default" ;
VAL_ 929 RRS_SEGMENT 15 "Sensor error" 14 "Reserved" 13 "Reserved" 12 "Reserved" 11 "Reserved" 10 "Reserved" 9 "Reserved" 8 "Reserved" 7 "Reserved" 6 "Display 6 Segment" 5 "Display 5 Segment" 4 "Display 4 Segment" 3 "Display 3 Segment" 2 "Display 2 Segment" 1 "Display 1 Segment" 0 "Default / No Display Segment" ;
VAL_ 929 RLMS_SEGMENT 15 "Sensor error" 14 "Reserved" 13 "Reserved" 12 "Reserved" 11 "Reserved" 10 "Reserved" 9 "Reserved" 8 "Reserved" 7 "Reserved" 6 "Display 6 Segment" 5 "Display 5 Segment" 4 "Display 4 Segment" 3 "Display 3 Segment" 2 "Display 2 Segment" 1 "Display 1 Segment" 0 "Default / No Display Segment" ;
VAL_ 929 FLS_SEG_WARN 1 "Warning" 0 "No Warning/Default" ;
VAL_ 929 FRS_SEGMENT 15 "Sensor error" 14 "Reserved" 13 "Reserved" 12 "Reserved" 11 "Reserved" 10 "Reserved" 9 "Reserved" 8 "Reserved" 7 "Reserved" 6 "Display 6 Segment" 5 "Display 5 Segment" 4 "Display 4 Segment" 3 "Display 3 Segment" 2 "Display 2 Segment" 1 "Display 1 Segment" 0 "Default / No Display Segment" ;
VAL_ 929 FRMS_SEG_WARN 1 "Warning" 0 "No Warning/Default" ;
VAL_ 929 RLS_SEGMENT 15 "Sensor error" 14 "Reserved" 13 "Reserved" 12 "Reserved" 11 "Reserved" 10 "Reserved" 9 "Reserved" 8 "Reserved" 7 "Reserved" 6 "Display 6 Segment" 5 "Display 5 Segment" 4 "Display 4 Segment" 3 "Display 3 Segment" 2 "Display 2 Segment" 1 "Display 1 Segment" 0 "Default / No Display Segment" ;
VAL_ 929 FLMS_SEGMENT 15 "Sensor error" 14 "Reserved" 13 "Reserved" 12 "Reserved" 11 "Reserved" 10 "Reserved" 9 "Reserved" 8 "Reserved" 7 "Reserved" 6 "Display 6 Segment" 5 "Display 5 Segment" 4 "Display 4 Segment" 3 "Display 3 Segment" 2 "Display 2 Segment" 1 "Display 1 Segment" 0 "Default / No Display Segment" ;
VAL_ 1653 STS_CODE_FOTA 19 "Write Data Failed" 11 "ECU Re-Programming Completed" 10 "Metadata Download failed" 9 "SecAccess to target ECU fail" 8 "BattVolt Pre-Condition Not Met" 7 "EngSpd Pre-Condition Not Met" 6 "VehSpd Pre-Condition Not Met" 5 "ReProgram of targt ECU in Prog" 4 "Update Download frm Tele in Prog" 3 "Gateway Memory Full" 2 "Update Download to Gateway Fail" 1 "ECU Re-Programming Failed" 0 "No Error / Idle/ DV" ;
VAL_ 1653 REQ_REPROG_FOTA 1 "Gateway Ready For reprog" 0 "GW Not Rdy for Reprog Update/DV" ;
VAL_ 1653 READY_UPDATE_DOWNLOAD_FOTA 1 "Gateway Ready for Update" 0 "GW not Ready for Rx Update/DV" ;
VAL_ 272 CUR_CARD_SHAFT_TRQ 2047 "Signal Invalid" 0 "Default Value" ;
VAL_ 272 TRANSFER_MODE_TC 3 "Signal Invalid" 2 "4WDL" 1 "4WDH" 0 "2WD/Default Value" ;
VAL_ 272 INDC_TC_MALF 1 "ON" 0 "OFF/Default" ;
VAL_ 272 INDC_TC_ALERT 7 "Reserved" 6 "Reserved" 5 "Reserved" 4 "Reserved" 3 "Stop-shift into park/neutral(AT)" 2 "Stop-shift to neutral gear(MT)" 1 "Reduce Vehicle Spd below 80km/h" 0 "Default/No Alert" ;
VAL_ 158 ICC_WAKEUP_REASON 2 "Rotary Encoder" 1 "Any Joystick Button Press" 0 "Any Button Press" ;
VAL_ 1583 ENG_OPERATION_MODE 15 "Unused" 14 "Unused" 13 "Unused" 12 "Unused" 11 "Unused" 10 "Unused" 9 "Unused" 8 "Unused" 7 "WrmUp" 6 "CldStrt" 5 "DeSOx" 4 "DeNOx" 3 "DeSOxHeat" 2 "PFlt_Rgn2" 1 "PFlt_Rgn1" 0 "Normal" ;
VAL_ 1581 DPF_HIGH_FUEL_OIL_DILUTION 3 "Reserved" 2 "Red" 1 "Yellow" 0 "Green / Default" ;
VAL_ 1581 CAL_LOAD 255 "Signal invalid" 0 "Default vaue" ;
VAL_ 1413 STS_CLUTCH_HIGH_TEMP 1 "FALSE" 0 "TRUE" ;
VAL_ 1413 FUEL_INJECTOR_DRIFT_PRED_INJ4 3 "Reserved" 2 "High Drift" 1 "Moderate Drift" 0 "No Drift / Default" ;
VAL_ 1413 FUEL_INJECTOR_DRIFT_PRED_INJ3 3 "Reserved" 2 "High Drift" 1 "Moderate Drift" 0 "No Drift / Default" ;
VAL_ 1413 FUEL_INJECTOR_DRIFT_PRED_INJ2 3 "Reserved" 2 "High Drift" 1 "Moderate Drift" 0 "No Drift / Default" ;
VAL_ 1413 FUEL_INJECTOR_DRIFT_PRED_INJ1 3 "Reserved" 2 "High Drift" 1 "Moderate Drift" 0 "No Drift / Default" ;
VAL_ 1413 STS_ADAPTV_SPEED_CNTRL_MODE 1 "Adaptive Speed Control " 0 "Normal Mode /Default value" ;
VAL_ 1413 ADAPTIVE_SPD_EMS_FB 7 "Speed 7" 6 "Speed 6" 5 "Speed 5" 4 "Speed 4" 3 "Speed 3" 2 "Speed 2" 1 "Speed 1" 0 "Default/Normal" ;
VAL_ 1413 DRV_MODE_CUSTOM1 1 "Custom Mode ON" 0 "Custom Mode OFF/DV" ;
VAL_ 1413 ENG_OIL_TEMP 0 "Default Value" 255 "Invalid value" ;
VAL_ 1413 ENG_OIL_PRESSURE_VAL 31 "Signal Invalid" 0 "Default" ;
VAL_ 581 OBC_DCOutputVoltage 16383 "Signal Invalid" 0 "Default Value" ;
VAL_ 581 OBC_DCOutputCurrent 4095 "Signal invalid" 0 "Default Value" ;
VAL_ 581 OBC_ACInputVoltageRMS 4095 "Signal Invalid" 0 "Default value" ;
VAL_ 581 OBC_ACInputCurrentRMS 16383 "Signal Invalid" 0 "Default Value" ;
VAL_ 274 VCU_MsgSt 6 "Timeout" 5 "ResponseReceived" 4 "TransmissionConfirmed" 3 "RequestSent" 2 "StreamingRequest" 1 "WaitForNextRequest" 0 "None" ;
VAL_ 274 VCU_ErrStack 14 "SLAC" 13 "Reserved" 12 "Reserved" 11 "NvM Error" 10 "NegativeResponseCode" 9 "InvalidRxParameter" 8 "InvalidRxMessage" 7 "Crypto Error" 6 "XmlSecurity" 5 "Exi Error" 4 "IpBase Error" 3 "Timeout" 2 "InvalidTxParameter" 1 "Transport Layer Error" 0 "NoError" ;
VAL_ 274 VCU_Isolt_mtr_stp_req 1 "Stop monitoring" 0 "Monitoring" ;
VAL_ 274 VCU_VehicleState 7 "Signal Invalid" 6 "Reserved" 5 "Reserved" 4 "Invalid" 3 "Charging" 2 "Running" 1 "SoftStart" 0 "Stopped/Default" ;
VAL_ 274 VCU_TorqueCommand 0 "Default Value" ;
VAL_ 274 VCU_OperationReq 7 "Invalid Req" 6 "Reserved" 5 "Reserved" 4 "Reserved" 3 "Reserved" 2 "ShutdownReq" 1 "OperationReq" 0 "StandybyReq/Default" ;
VAL_ 274 VCU_OperationalModeCmd 7 "Signal Invalid" 6 "Reserved" 5 "Reserved" 2 "Reserved" 4 "Reserved" 3 "Ev" 1 "Reserved" 0 "Neutral/Default" ;
VAL_ 274 VCU_CommandMode 3 "Signal Invalid" 2 "Reserved" 1 "Speed Mode" 0 "Default/Torque Mode" ;
VAL_ 274 VCU112_COUNTER 0 "Default Value" ;
VAL_ 274 VCU112_Checksum 0 "Default Value" ;
VAL_ 274 VCU_ACTV_Discharge_REQ 1 "Request" 0 "No Request" ;
VAL_ 819 VCU_HVDisconnect_Reasons 4 "Cabin Heater HV DC Input Not Ok" 3 "ACComp/HVBat Htr HVDC InputNotOk" 2 "LDC/OBC HV DC Input Not Ok" 1 "MCU HV Not Ok" 0 "Default" ;
VAL_ 819 VCU_Gear_Actual 7 "Signal Invalid" 6 "Reserved" 5 "Park Mode" 4 "Reserved" 3 "Low Mode" 2 "Reverse Mode" 1 "Forward Mode" 0 "Neutral Mode/ Default" ;
VAL_ 819 VCU_CmdACPWM 0 "Default Value" 255 "Signal Invalid" ;
VAL_ 819 VCU_CmdACCP 7 "Signal Invalid" 6 "Reserved" 5 "Reserved" 4 "Stage F(-12)" 3 "Stage D(3V)" 2 "Stage C(6V)" 1 "Stage B(9V)" 0 "Stage A(0V)/Default" ;
VAL_ 819 VCU_VehChargeModeSta 7 "Signal Invalid" 6 "Reserved" 5 "Reserved" 4 "12V Battery Auto Charging Mode" 3 "Quick(DC) Charging Mode" 2 "Reserved" 1 "Normal(AC) Charging Mode" 0 "Standby/Default" ;
VAL_ 819 VCU_PP_CurrentLimit 255 "Signal Invalid" ;
VAL_ 821 VCU_HVConnect_Sta 3 "Signal Invalid" 2 "HV Disconnected" 1 "HV Connected" 0 "Default" ;
VAL_ 821 VCU_ChargingPlugSta 3 "Signal Invalid" 2 "DC Plug Connected" 1 "AC Plug Connected" 0 "DisConnected/Default" ;
VAL_ 821 VCU_DISP_AMBT_TEMP_FATC 65 "Default Value" 255 "Invalid Value" ;
VAL_ 821 VCU_HVACHeatingSta 3 "Signal Invalid" 2 "Reserved" 1 "ON" 0 "OFF/Default" ;
VAL_ 821 VCU_HVACCoolingSta 3 "Signal Invalid" 2 "Reserved" 1 "ON" 0 "OFF/Default" ;
VAL_ 821 VCU_HVACCoolingPower 1023 "Signal Invalid" 0 "Default" ;
VAL_ 821 VCU_ActiveDampingDisableCommand 3 "Invalid Request" 2 "Reserved" 1 "Request" 0 "No Request" ;
